VERSION "eCMP INFO-DIV vehicle review 2026-11-03; 125000 bit/s; PSA-RE 67f7581e7622410efdbb29c7eda3b86982b9b450; Apache-2.0"

NS_ :

BS_:

BU_: AAS AMPLI AVP BCM BGP BSG BSI BTA BTEL BTT CDC CMB CRT DIAG_TOOL EDP_C EMF FMUX IC ICSV IDVR IVC_D MATT MDS OVIP PDS_C RAD RBG SDCM VTH WLC

BO_ 223 EMF_MenuCommand: 4 EMF
 SG_ Unused1 : 26|3@0+ (1,0) [0|7] ""  RAD
 SG_ ListRefreshRequest : 28|2@0+ (1,0) [0|3] ""  RAD
 SG_ RepeatEnabled : 29|1@0+ (1,0) [0|1] ""  RAD
 SG_ ShuffleModeStatus : 30|1@0+ (1,0) [0|1] ""  RAD
 SG_ RandomEnabled : 31|1@0+ (1,0) [0|1] ""  RAD
 SG_ RadioDabFmStatus : 16|1@0+ (1,0) [0|1] ""  RAD
 SG_ RadioTextModeStatus : 17|1@0+ (1,0) [0|1] ""  RAD
 SG_ RadioRdsAfStatus : 18|1@0+ (1,0) [0|1] ""  RAD
 SG_ RadioNewsOption7Status : 19|1@0+ (1,0) [0|1] ""  RAD
 SG_ RadioNewsOption6Status : 20|1@0+ (1,0) [0|1] ""  RAD
 SG_ RadioNewsOption5Status : 21|1@0+ (1,0) [0|1] ""  RAD
 SG_ RadioNewsOption4Status : 22|1@0+ (1,0) [0|1] ""  RAD
 SG_ RadioNewsOption3Status : 23|1@0+ (1,0) [0|1] ""  RAD
 SG_ RadioNewsOption2Status : 8|1@0+ (1,0) [0|1] ""  RAD
 SG_ RadioNewsOption1Status : 9|1@0+ (1,0) [0|1] ""  RAD
 SG_ NextListTypeRequested : 12|3@0+ (1,0) [0|7] ""  RAD
 SG_ DesignatorBlockType : 15|3@0+ (1,0) [0|7] ""  RAD
 SG_ ListOpenRequest : 3|4@0+ (1,0) [0|15] ""  RAD
 SG_ CdTextModeStatus : 4|1@0+ (1,0) [0|1] ""  RAD
 SG_ ModificationInProgress : 5|1@0+ (1,0) [0|1] ""  RAD
 SG_ DesignatorButtonManager : 7|2@0+ (1,0) [0|3] ""  RAD

BO_ 224 BSI_ImmobilizerKeyUccEngine: 7 BSI
 SG_ AcPrecondSchedule4StartTime : 42|11@0+ (1,0) [0|1440] "min"  MDS,BTEL,OVIP
 SG_ Unused3 : 47|5@0+ (1,0) [0|31] ""  MDS,BTEL,OVIP
 SG_ AcPrecondSundaySchedule4Active : 32|1@0+ (1,0) [0|1] ""  MDS,BTEL,OVIP
 SG_ AcPrecondSaturdaySchedule4Active : 33|1@0+ (1,0) [0|1] ""  MDS,BTEL,OVIP
 SG_ AcPrecondFridaySchedule4Active : 34|1@0+ (1,0) [0|1] ""  MDS,BTEL,OVIP
 SG_ AcPrecondThursdaySchedule4Active : 35|1@0+ (1,0) [0|1] ""  MDS,BTEL,OVIP
 SG_ AcPrecondWednesdaySchedul_8f02bb : 36|1@0+ (1,0) [0|1] ""  MDS,BTEL,OVIP
 SG_ AcPrecondTuesdaySchedule4Active : 37|1@0+ (1,0) [0|1] ""  MDS,BTEL,OVIP
 SG_ AcPrecondMondaySchedule4Active : 38|1@0+ (1,0) [0|1] ""  MDS,BTEL,OVIP
 SG_ AcPrecondSchedule4Enabled : 39|1@0+ (1,0) [0|1] ""  MDS,BTEL,OVIP
 SG_ AcPrecondSchedule3StartTime : 18|11@0+ (1,0) [0|1440] "min"  MDS,BTEL,OVIP
 SG_ Unused2 : 23|5@0+ (1,0) [0|31] ""  MDS,BTEL,OVIP
 SG_ AcPrecondSundaySchedule3Active : 8|1@0+ (1,0) [0|1] ""  MDS,BTEL,OVIP
 SG_ AcPrecondSaturdaySchedule3Active : 9|1@0+ (1,0) [0|1] ""  MDS,BTEL,OVIP
 SG_ AcPrecondFridaySchedule3Active : 10|1@0+ (1,0) [0|1] ""  MDS,BTEL,OVIP
 SG_ AcPrecondThursdaySchedule3Active : 11|1@0+ (1,0) [0|1] ""  MDS,BTEL,OVIP
 SG_ AcPrecondWednesdaySchedul_dacc80 : 12|1@0+ (1,0) [0|1] ""  MDS,BTEL,OVIP
 SG_ AcPrecondTuesdaySchedule3Active : 13|1@0+ (1,0) [0|1] ""  MDS,BTEL,OVIP
 SG_ AcPrecondMondaySchedule3Active : 14|1@0+ (1,0) [0|1] ""  MDS,BTEL,OVIP
 SG_ AcPrecondSchedule3Enabled : 15|1@0+ (1,0) [0|1] ""  MDS,BTEL,OVIP
 SG_ Unused1 : 7|8@0+ (1,0) [0|255] ""  MDS,BTEL,OVIP

BO_ 225 AAS_Data: 8 AAS
 SG_ CpkMenuRequest : 56|1@0+ (1,0) [0|1] ""  RAD,BTEL,CMB,AVP,ICSV,MATT,BSI,AMPLI,EMF,PDS_C,OVIP,MDS
 SG_ Scp9HmiRequest : 59|3@0+ (1,0) [0|7] ""  RAD,BTEL,CMB,AVP,ICSV,MATT,BSI,AMPLI,EMF,PDS_C,OVIP,MDS
 SG_ Scp6HmiRequest : 62|3@0+ (1,0) [0|7] ""  RAD,BTEL,CMB,AVP,ICSV,MATT,BSI,AMPLI,EMF,PDS_C,OVIP,MDS
 SG_ Scp9Status : 63|1@0+ (1,0) [0|1] ""  RAD,BTEL,CMB,AVP,ICSV,MATT,BSI,AMPLI,EMF,PDS_C,OVIP,MDS
 SG_ NetworkVoltageBoostRequest : 48|1@0+ (1,0) [0|1] ""  RAD,BTEL,CMB,AVP,ICSV,MATT,BSI,AMPLI,EMF,PDS_C,OVIP,MDS
 SG_ EngineOnRequest : 49|1@0+ (1,0) [0|1] ""  RAD,BTEL,CMB,AVP,ICSV,MATT,BSI,AMPLI,EMF,PDS_C,OVIP,MDS
 SG_ SpaceMeasurementDisplayRequest : 50|1@0+ (1,0) [0|1] ""  RAD,BTEL,CMB,AVP,ICSV,MATT,BSI,AMPLI,EMF,PDS_C,OVIP,MDS
 SG_ MeasuredDistance : 52|2@0+ (1,0) [0|3] ""  RAD,BTEL,CMB,AVP,ICSV,MATT,BSI,AMPLI,EMF,PDS_C,OVIP,MDS
 SG_ SpaceMeasurementStatus : 55|3@0+ (1,0) [0|7] ""  RAD,BTEL,CMB,AVP,ICSV,MATT,BSI,AMPLI,EMF,PDS_C,OVIP,MDS
 SG_ Unused2 : 40|1@0+ (1,0) [0|1] ""  RAD,BTEL,CMB,AVP,ICSV,MATT,BSI,AMPLI,EMF,PDS_C,OVIP,MDS
 SG_ AasDisplayRequest : 41|1@0+ (1,0) [0|1] ""  RAD,BTEL,CMB,AVP,ICSV,MATT,BSI,AMPLI,EMF,PDS_C,OVIP,MDS
 SG_ FrontRightStatus : 44|3@0+ (1,0) [0|7] ""  RAD,BTEL,CMB,AVP,ICSV,MATT,BSI,AMPLI,EMF,PDS_C,OVIP,MDS
 SG_ FrontMiddleStatus : 47|3@0+ (1,0) [0|7] ""  RAD,BTEL,CMB,AVP,ICSV,MATT,BSI,AMPLI,EMF,PDS_C,OVIP,MDS
 SG_ LateralBeepLocation : 33|2@0+ (1,0) [0|3] ""  RAD,BTEL,CMB,AVP,ICSV,MATT,BSI,AMPLI,EMF,PDS_C,OVIP,MDS
 SG_ FrontLeftStatus : 36|3@0+ (1,0) [0|7] ""  RAD,BTEL,CMB,AVP,ICSV,MATT,BSI,AMPLI,EMF,PDS_C,OVIP,MDS
 SG_ RearRightStatus : 39|3@0+ (1,0) [0|7] ""  RAD,BTEL,CMB,AVP,ICSV,MATT,BSI,AMPLI,EMF,PDS_C,OVIP,MDS
 SG_ ScpLampStatus : 25|2@0+ (1,0) [0|3] ""  RAD,BTEL,CMB,AVP,ICSV,MATT,BSI,AMPLI,EMF,PDS_C,OVIP,MDS
 SG_ RearMiddleStatus : 28|3@0+ (1,0) [0|7] ""  RAD,BTEL,CMB,AVP,ICSV,MATT,BSI,AMPLI,EMF,PDS_C,OVIP,MDS
 SG_ RearLeftStatus : 31|3@0+ (1,0) [0|7] ""  RAD,BTEL,CMB,AVP,ICSV,MATT,BSI,AMPLI,EMF,PDS_C,OVIP,MDS
 SG_ ParkAssistBeepInterval : 21|6@0+ (8,0) [0|496] "ms"  RAD,BTEL,CMB,AVP,ICSV,MATT,BSI,AMPLI,EMF,PDS_C,OVIP,MDS
 SG_ ParkAssistBeepDuration : 23|2@0+ (1,0) [0|3] ""  RAD,BTEL,CMB,AVP,ICSV,MATT,BSI,AMPLI,EMF,PDS_C,OVIP,MDS
 SG_ Unused1 : 8|1@0+ (1,0) [0|1] ""  RAD,BTEL,CMB,AVP,ICSV,MATT,BSI,AMPLI,EMF,PDS_C,OVIP,MDS
 SG_ LateralParkAssistStatus : 11|3@0+ (1,0) [0|7] ""  RAD,BTEL,CMB,AVP,ICSV,MATT,BSI,AMPLI,EMF,PDS_C,OVIP,MDS
 SG_ SoundEnabled : 12|1@0+ (1,0) [0|1] ""  RAD,BTEL,CMB,AVP,ICSV,MATT,BSI,AMPLI,EMF,PDS_C,OVIP,MDS
 SG_ SoundFr : 13|1@0+ (1,0) [0|1] ""  RAD,BTEL,CMB,AVP,ICSV,MATT,BSI,AMPLI,EMF,PDS_C,OVIP,MDS
 SG_ SoundLr : 15|2@0+ (1,0) [0|3] ""  RAD,BTEL,CMB,AVP,ICSV,MATT,BSI,AMPLI,EMF,PDS_C,OVIP,MDS
 SG_ CpkSelection : 1|2@0+ (1,0) [0|3] ""  RAD,BTEL,CMB,AVP,ICSV,MATT,BSI,AMPLI,EMF,PDS_C,OVIP,MDS
 SG_ FrontStatus : 4|3@0+ (1,0) [0|7] ""  RAD,BTEL,CMB,AVP,ICSV,MATT,BSI,AMPLI,EMF,PDS_C,OVIP,MDS
 SG_ RearParkAssistStatus : 7|3@0+ (1,0) [0|7] ""  RAD,BTEL,CMB,AVP,ICSV,MATT,BSI,AMPLI,EMF,PDS_C,OVIP,MDS

BO_ 226 ICSV_CdChangerDiskListStatus: 8 ICSV
 SG_ Unused4 : 63|8@0+ (1,0) [0|255] ""  BTEL,OVIP,EMF,RAD
 SG_ DiscStatus6 : 49|2@0+ (1,0) [0|3] ""  BTEL,OVIP,EMF,RAD
 SG_ DiscFormat6 : 51|2@0+ (1,0) [0|3] ""  BTEL,OVIP,EMF,RAD
 SG_ DiscStatus5 : 53|2@0+ (1,0) [0|3] ""  BTEL,OVIP,EMF,RAD
 SG_ DiscFormat5 : 55|2@0+ (1,0) [0|3] ""  BTEL,OVIP,EMF,RAD
 SG_ DiscStatus4 : 41|2@0+ (1,0) [0|3] ""  BTEL,OVIP,EMF,RAD
 SG_ DiscFormat4 : 43|2@0+ (1,0) [0|3] ""  BTEL,OVIP,EMF,RAD
 SG_ DiscStatus3 : 45|2@0+ (1,0) [0|3] ""  BTEL,OVIP,EMF,RAD
 SG_ DiscFormat3 : 47|2@0+ (1,0) [0|3] ""  BTEL,OVIP,EMF,RAD
 SG_ DiscStatus2 : 33|2@0+ (1,0) [0|3] ""  BTEL,OVIP,EMF,RAD
 SG_ DiscFormat2 : 35|2@0+ (1,0) [0|3] ""  BTEL,OVIP,EMF,RAD
 SG_ DiscStatus1 : 37|2@0+ (1,0) [0|3] ""  BTEL,OVIP,EMF,RAD
 SG_ DiscFormat1 : 39|2@0+ (1,0) [0|3] ""  BTEL,OVIP,EMF,RAD
 SG_ Unused3 : 27|4@0+ (1,0) [0|15] ""  BTEL,OVIP,EMF,RAD
 SG_ SelectedPresetNumber : 31|4@0+ (1,0) [0|15] ""  BTEL,OVIP,EMF,RAD
 SG_ Unused2 : 17|2@0+ (1,0) [0|3] ""  BTEL,OVIP,EMF,RAD
 SG_ CdcListCommand : 19|2@0+ (1,0) [0|3] ""  BTEL,OVIP,EMF,RAD
 SG_ CdcDirectoryType : 23|4@0+ (1,0) [0|15] ""  BTEL,OVIP,EMF,RAD
 SG_ Unused1 : 7|16@0+ (1,0) [0|65535] ""  BTEL,OVIP,EMF,RAD

BO_ 230 ICSV_BrakeUnitStatus: 8 ICSV
 SG_ BrakeEcuFrame5Checksum : 59|4@0+ (1,0) [0|15] ""  BTEL,AAS,CMB,MDS,AVP,OVIP,RAD
 SG_ ProcessCounter4bit : 63|4@0+ (1,0) [0|15] ""  BTEL,AAS,CMB,MDS,AVP,OVIP,RAD
 SG_ Unused2 : 51|4@0+ (1,0) [0|15] ""  BTEL,AAS,CMB,MDS,AVP,OVIP,RAD
 SG_ BrakeFunctionNeedForStartStop : 53|2@0+ (1,0) [0|3] ""  BTEL,AAS,CMB,MDS,AVP,OVIP,RAD
 SG_ BrakeEcuPowerManagementFault : 54|1@0+ (1,0) [0|1] ""  BTEL,AAS,CMB,MDS,AVP,OVIP,RAD
 SG_ EmergencyBrakingSignaliza_517ee3 : 55|1@0+ (1,0) [0|1] ""  BTEL,AAS,CMB,MDS,AVP,OVIP,RAD
 SG_ BatteryVoltageUcBrake : 47|8@0+ (0.05,7) [7|18.5] "V"  BTEL,AAS,CMB,MDS,AVP,OVIP,RAD
 SG_ RearRightWheelSpinCounter : 30|15@0+ (1,0) [0|32767] ""  BTEL,AAS,CMB,MDS,AVP,OVIP,RAD
 SG_ RearRightWheelSpeedSensorFault : 31|1@0+ (1,0) [0|1] ""  BTEL,AAS,CMB,MDS,AVP,OVIP,RAD
 SG_ RearLeftWheelSpinCounter : 14|15@0+ (1,0) [0|32767] ""  BTEL,AAS,CMB,MDS,AVP,OVIP,RAD
 SG_ RearLeftWheelSpeedSensorFault : 15|1@0+ (1,0) [0|1] ""  BTEL,AAS,CMB,MDS,AVP,OVIP,RAD
 SG_ AbsFaultLampRequest : 0|1@0+ (1,0) [0|1] ""  BTEL,AAS,CMB,MDS,AVP,OVIP,RAD
 SG_ BrakeFluidLevelAlert : 1|1@0+ (1,0) [0|1] ""  BTEL,AAS,CMB,MDS,AVP,OVIP,RAD
 SG_ WornBrakePadsIndicator : 2|1@0+ (1,0) [0|1] ""  BTEL,AAS,CMB,MDS,AVP,OVIP,RAD
 SG_ RefInProgress : 3|1@0+ (1,0) [0|1] ""  BTEL,AAS,CMB,MDS,AVP,OVIP,RAD
 SG_ AutomaticHazardLightsByUcBrake : 4|1@0+ (1,0) [0|1] ""  BTEL,AAS,CMB,MDS,AVP,OVIP,RAD
 SG_ AbsInProgress : 5|1@0+ (1,0) [0|1] ""  BTEL,AAS,CMB,MDS,AVP,OVIP,RAD
 SG_ Unused1 : 6|1@0+ (1,0) [0|1] ""  BTEL,AAS,CMB,MDS,AVP,OVIP,RAD
 SG_ RefFaultLamp : 7|1@0+ (1,0) [0|1] ""  BTEL,AAS,CMB,MDS,AVP,OVIP,RAD

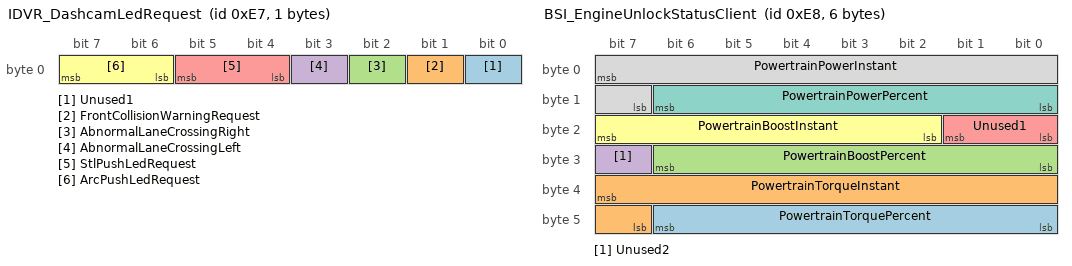
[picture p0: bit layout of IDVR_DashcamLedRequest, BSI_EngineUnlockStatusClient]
BO_ 231 IDVR_DashcamLedRequest: 1 IDVR
 SG_ Unused1 : 0|1@0+ (1,0) [0|1] ""  ICSV,FMUX,BTEL,CMB,OVIP,MDS
 SG_ FrontCollisionWarningRequest : 1|1@0+ (1,0) [0|1] ""  ICSV,FMUX,BTEL,CMB,OVIP,MDS
 SG_ AbnormalLaneCrossingRight : 2|1@0+ (1,0) [0|1] ""  ICSV,FMUX,BTEL,CMB,OVIP,MDS
 SG_ AbnormalLaneCrossingLeft : 3|1@0+ (1,0) [0|1] ""  ICSV,FMUX,BTEL,CMB,OVIP,MDS
 SG_ StlPushLedRequest : 5|2@0+ (1,0) [0|3] ""  ICSV,FMUX,BTEL,CMB,OVIP,MDS
 SG_ ArcPushLedRequest : 7|2@0+ (1,0) [0|3] ""  ICSV,FMUX,BTEL,CMB,OVIP,MDS

BO_ 232 BSI_EngineUnlockStatusClient: 6 BSI
 SG_ PowertrainTorquePercent : 46|7@0+ (1,0) [0|100] "%"  OVIP,CMB,MATT,RAD
 SG_ PowertrainTorqueInstant : 39|9@0+ (1,0) [0|500] "Nm"  OVIP,CMB,MATT,RAD
 SG_ PowertrainBoostPercent : 30|7@0+ (1,0) [0|100] "%"  OVIP,CMB,MATT,RAD
 SG_ Unused2 : 31|1@0+ (1,0) [0|1] ""  OVIP,CMB,MATT,RAD
 SG_ Unused1 : 17|2@0+ (1,0) [0|3] ""  OVIP,CMB,MATT,RAD
 SG_ PowertrainBoostInstant : 23|6@0+ (0.1,0) [0|5] "bar"  OVIP,CMB,MATT,RAD
 SG_ PowertrainPowerPercent : 14|7@0+ (1,0) [0|100] "%"  OVIP,CMB,MATT,RAD
 SG_ PowertrainPowerInstant : 7|9@0+ (1,0) [0|500] "hp"  OVIP,CMB,MATT,RAD

BO_ 233 ICSV_NavExportFlowControl: 8 ICSV
 SG_ FlowPadding5 m3 : 63|8@0+ (1,0) [0|255] "raw"  BTEL,OVIP
 SG_ FirstData6 m1 : 63|8@0+ (1,0) [0|255] "raw"  BTEL,OVIP
 SG_ UnknownData7 m4 : 63|8@0+ (1,0) [0|255] "raw"  BTEL,OVIP
 SG_ ConsecutiveData7 m2 : 63|8@0+ (1,0) [0|255] "raw"  BTEL,OVIP
 SG_ SingleData7 m0 : 63|8@0+ (1,0) [0|255] "raw"  BTEL,OVIP
 SG_ FlowPadding4 m3 : 55|8@0+ (1,0) [0|255] "raw"  BTEL,OVIP
 SG_ FirstData5 m1 : 55|8@0+ (1,0) [0|255] "raw"  BTEL,OVIP
 SG_ UnknownData6 m4 : 55|8@0+ (1,0) [0|255] "raw"  BTEL,OVIP
 SG_ ConsecutiveData6 m2 : 55|8@0+ (1,0) [0|255] "raw"  BTEL,OVIP
 SG_ SingleData6 m0 : 55|8@0+ (1,0) [0|255] "raw"  BTEL,OVIP
 SG_ FlowPadding3 m3 : 47|8@0+ (1,0) [0|255] "raw"  BTEL,OVIP
 SG_ FirstData4 m1 : 47|8@0+ (1,0) [0|255] "raw"  BTEL,OVIP
 SG_ UnknownData5 m4 : 47|8@0+ (1,0) [0|255] "raw"  BTEL,OVIP
 SG_ ConsecutiveData5 m2 : 47|8@0+ (1,0) [0|255] "raw"  BTEL,OVIP
 SG_ SingleData5 m0 : 47|8@0+ (1,0) [0|255] "raw"  BTEL,OVIP
 SG_ FlowPadding2 m3 : 39|8@0+ (1,0) [0|255] "raw"  BTEL,OVIP
 SG_ FirstData3 m1 : 39|8@0+ (1,0) [0|255] "raw"  BTEL,OVIP
 SG_ UnknownData4 m4 : 39|8@0+ (1,0) [0|255] "raw"  BTEL,OVIP
 SG_ ConsecutiveData4 m2 : 39|8@0+ (1,0) [0|255] "raw"  BTEL,OVIP
 SG_ SingleData4 m0 : 39|8@0+ (1,0) [0|255] "raw"  BTEL,OVIP
 SG_ FlowPadding1 m3 : 31|8@0+ (1,0) [0|255] "raw"  BTEL,OVIP
 SG_ FirstData2 m1 : 31|8@0+ (1,0) [0|255] "raw"  BTEL,OVIP
 SG_ UnknownData3 m4 : 31|8@0+ (1,0) [0|255] "raw"  BTEL,OVIP
 SG_ ConsecutiveData3 m2 : 31|8@0+ (1,0) [0|255] "raw"  BTEL,OVIP
 SG_ SingleData3 m0 : 31|8@0+ (1,0) [0|255] "raw"  BTEL,OVIP
 SG_ FirstData1 m1 : 23|8@0+ (1,0) [0|255] "raw"  BTEL,OVIP
 SG_ UnknownData2 m4 : 23|8@0+ (1,0) [0|255] "raw"  BTEL,OVIP
 SG_ ConsecutiveData2 m2 : 23|8@0+ (1,0) [0|255] "raw"  BTEL,OVIP
 SG_ SingleData2 m0 : 23|8@0+ (1,0) [0|255] "raw"  BTEL,OVIP
 SG_ SeparationTimeRaw m3 : 23|8@0+ (1,0) [0|255] "raw"  BTEL,OVIP
 SG_ UnknownData1 m4 : 15|8@0+ (1,0) [0|255] "raw"  BTEL,OVIP
 SG_ ConsecutiveData1 m2 : 15|8@0+ (1,0) [0|255] "raw"  BTEL,OVIP
 SG_ SingleData1 m0 : 15|8@0+ (1,0) [0|255] "raw"  BTEL,OVIP
 SG_ BlockSize m3 : 15|8@0+ (1,0) [0|255] "raw"  BTEL,OVIP
 SG_ UnknownPciLow m4 : 3|4@0+ (1,0) [0|15] "raw"  BTEL,OVIP
 SG_ FlowStatus m3 : 3|4@0+ (1,0) [0|15] "raw"  BTEL,OVIP
 SG_ ConsecutiveSequence m2 : 3|4@0+ (1,0) [0|15] "raw"  BTEL,OVIP
 SG_ FirstFrameLength m1 : 3|12@0+ (1,0) [0|4095] "raw"  BTEL,OVIP
 SG_ SingleFrameLength m0 : 3|4@0+ (1,0) [0|15] "raw"  BTEL,OVIP
 SG_ IsoTpFrameType M : 7|4@0+ (1,0) [0|15] ""  BTEL,OVIP

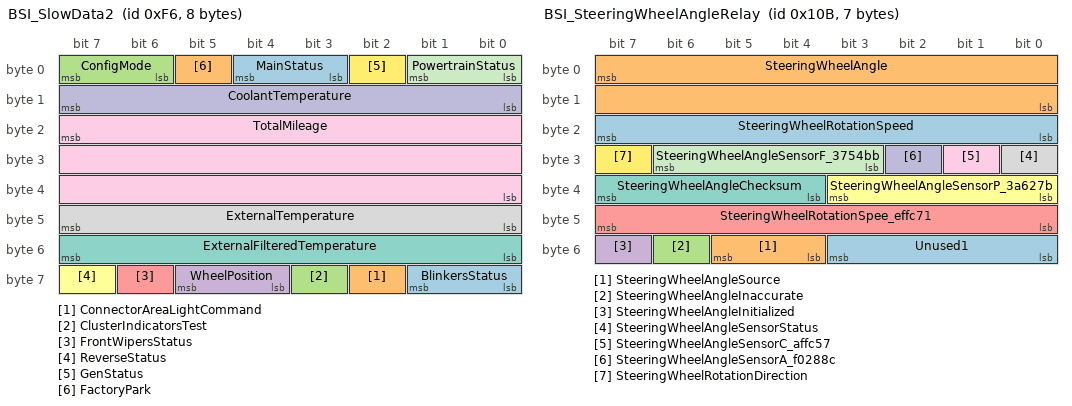
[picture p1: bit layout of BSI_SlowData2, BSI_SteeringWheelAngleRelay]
BO_ 246 BSI_SlowData2: 8 BSI
 SG_ BlinkersStatus : 57|2@0+ (1,0) [0|3] ""  SDCM,CRT,BTEL,ICSV,CDC,EMF,RAD,CMB,VTH,AAS,MDS,MATT,FMUX,BGP,AMPLI,AVP,OVIP,IDVR,WLC
 SG_ ConnectorAreaLightCommand : 58|1@0+ (1,0) [0|1] ""  SDCM,CRT,BTEL,ICSV,CDC,EMF,RAD,CMB,VTH,AAS,MDS,MATT,FMUX,BGP,AMPLI,AVP,OVIP,IDVR,WLC
 SG_ ClusterIndicatorsTest : 59|1@0+ (1,0) [0|1] ""  SDCM,CRT,BTEL,ICSV,CDC,EMF,RAD,CMB,VTH,AAS,MDS,MATT,FMUX,BGP,AMPLI,AVP,OVIP,IDVR,WLC
 SG_ WheelPosition : 61|2@0+ (1,0) [0|3] ""  SDCM,CRT,BTEL,ICSV,CDC,EMF,RAD,CMB,VTH,AAS,MDS,MATT,FMUX,BGP,AMPLI,AVP,OVIP,IDVR,WLC
 SG_ FrontWipersStatus : 62|1@0+ (1,0) [0|1] ""  SDCM,CRT,BTEL,ICSV,CDC,EMF,RAD,CMB,VTH,AAS,MDS,MATT,FMUX,BGP,AMPLI,AVP,OVIP,IDVR,WLC
 SG_ ReverseStatus : 63|1@0+ (1,0) [0|1] ""  SDCM,CRT,BTEL,ICSV,CDC,EMF,RAD,CMB,VTH,AAS,MDS,MATT,FMUX,BGP,AMPLI,AVP,OVIP,IDVR,WLC
 SG_ ExternalFilteredTemperature : 55|8@0+ (0.5,-40) [-40|85] "degC"  SDCM,CRT,BTEL,ICSV,CDC,EMF,RAD,CMB,VTH,AAS,MDS,MATT,FMUX,BGP,AMPLI,AVP,OVIP,IDVR,WLC
 SG_ ExternalTemperature : 47|8@0+ (0.5,-40) [-40|85] ""  SDCM,CRT,BTEL,ICSV,CDC,EMF,RAD,CMB,VTH,AAS,MDS,MATT,FMUX,BGP,AMPLI,AVP,OVIP,IDVR,WLC
 SG_ TotalMileage : 23|24@0+ (0.1,0) [0|1677721.4] "km"  SDCM,CRT,BTEL,ICSV,CDC,EMF,RAD,CMB,VTH,AAS,MDS,MATT,FMUX,BGP,AMPLI,AVP,OVIP,IDVR,WLC
 SG_ CoolantTemperature : 15|8@0+ (1,-40) [-40|214] "degC"  SDCM,CRT,BTEL,ICSV,CDC,EMF,RAD,CMB,VTH,AAS,MDS,MATT,FMUX,BGP,AMPLI,AVP,OVIP,IDVR,WLC
 SG_ PowertrainStatus : 1|2@0+ (1,0) [0|3] ""  SDCM,CRT,BTEL,ICSV,CDC,EMF,RAD,CMB,VTH,AAS,MDS,MATT,FMUX,BGP,AMPLI,AVP,OVIP,IDVR,WLC
 SG_ GenStatus : 2|1@0+ (1,0) [0|1] ""  SDCM,CRT,BTEL,ICSV,CDC,EMF,RAD,CMB,VTH,AAS,MDS,MATT,FMUX,BGP,AMPLI,AVP,OVIP,IDVR,WLC
 SG_ MainStatus : 4|2@0+ (1,0) [0|3] ""  SDCM,CRT,BTEL,ICSV,CDC,EMF,RAD,CMB,VTH,AAS,MDS,MATT,FMUX,BGP,AMPLI,AVP,OVIP,IDVR,WLC
 SG_ FactoryPark : 5|1@0+ (1,0) [0|1] ""  SDCM,CRT,BTEL,ICSV,CDC,EMF,RAD,CMB,VTH,AAS,MDS,MATT,FMUX,BGP,AMPLI,AVP,OVIP,IDVR,WLC
 SG_ ConfigMode : 7|2@0+ (1,0) [0|3] ""  SDCM,CRT,BTEL,ICSV,CDC,EMF,RAD,CMB,VTH,AAS,MDS,MATT,FMUX,BGP,AMPLI,AVP,OVIP,IDVR,WLC

BO_ 257 WLC_ScrVersion: 8 WLC
 SG_ FlowPadding5 m3 : 63|8@0+ (1,0) [0|255] "raw"  SDCM
 SG_ FirstData6 m1 : 63|8@0+ (1,0) [0|255] "raw"  SDCM
 SG_ UnknownData7 m4 : 63|8@0+ (1,0) [0|255] "raw"  SDCM
 SG_ ConsecutiveData7 m2 : 63|8@0+ (1,0) [0|255] "raw"  SDCM
 SG_ SingleData7 m0 : 63|8@0+ (1,0) [0|255] "raw"  SDCM
 SG_ FlowPadding4 m3 : 55|8@0+ (1,0) [0|255] "raw"  SDCM
 SG_ FirstData5 m1 : 55|8@0+ (1,0) [0|255] "raw"  SDCM
 SG_ UnknownData6 m4 : 55|8@0+ (1,0) [0|255] "raw"  SDCM
 SG_ ConsecutiveData6 m2 : 55|8@0+ (1,0) [0|255] "raw"  SDCM
 SG_ SingleData6 m0 : 55|8@0+ (1,0) [0|255] "raw"  SDCM
 SG_ FlowPadding3 m3 : 47|8@0+ (1,0) [0|255] "raw"  SDCM
 SG_ FirstData4 m1 : 47|8@0+ (1,0) [0|255] "raw"  SDCM
 SG_ UnknownData5 m4 : 47|8@0+ (1,0) [0|255] "raw"  SDCM
 SG_ ConsecutiveData5 m2 : 47|8@0+ (1,0) [0|255] "raw"  SDCM
 SG_ SingleData5 m0 : 47|8@0+ (1,0) [0|255] "raw"  SDCM
 SG_ FlowPadding2 m3 : 39|8@0+ (1,0) [0|255] "raw"  SDCM
 SG_ FirstData3 m1 : 39|8@0+ (1,0) [0|255] "raw"  SDCM
 SG_ UnknownData4 m4 : 39|8@0+ (1,0) [0|255] "raw"  SDCM
 SG_ ConsecutiveData4 m2 : 39|8@0+ (1,0) [0|255] "raw"  SDCM
 SG_ SingleData4 m0 : 39|8@0+ (1,0) [0|255] "raw"  SDCM
 SG_ FlowPadding1 m3 : 31|8@0+ (1,0) [0|255] "raw"  SDCM
 SG_ FirstData2 m1 : 31|8@0+ (1,0) [0|255] "raw"  SDCM
 SG_ UnknownData3 m4 : 31|8@0+ (1,0) [0|255] "raw"  SDCM
 SG_ ConsecutiveData3 m2 : 31|8@0+ (1,0) [0|255] "raw"  SDCM
 SG_ SingleData3 m0 : 31|8@0+ (1,0) [0|255] "raw"  SDCM
 SG_ FirstData1 m1 : 23|8@0+ (1,0) [0|255] "raw"  SDCM
 SG_ UnknownData2 m4 : 23|8@0+ (1,0) [0|255] "raw"  SDCM
 SG_ ConsecutiveData2 m2 : 23|8@0+ (1,0) [0|255] "raw"  SDCM
 SG_ SingleData2 m0 : 23|8@0+ (1,0) [0|255] "raw"  SDCM
 SG_ SeparationTimeRaw m3 : 23|8@0+ (1,0) [0|255] "raw"  SDCM
 SG_ UnknownData1 m4 : 15|8@0+ (1,0) [0|255] "raw"  SDCM
 SG_ ConsecutiveData1 m2 : 15|8@0+ (1,0) [0|255] "raw"  SDCM
 SG_ SingleData1 m0 : 15|8@0+ (1,0) [0|255] "raw"  SDCM
 SG_ BlockSize m3 : 15|8@0+ (1,0) [0|255] "raw"  SDCM
 SG_ UnknownPciLow m4 : 3|4@0+ (1,0) [0|15] "raw"  SDCM
 SG_ FlowStatus m3 : 3|4@0+ (1,0) [0|15] "raw"  SDCM
 SG_ ConsecutiveSequence m2 : 3|4@0+ (1,0) [0|15] "raw"  SDCM
 SG_ FirstFrameLength m1 : 3|12@0+ (1,0) [0|4095] "raw"  SDCM
 SG_ SingleFrameLength m0 : 3|4@0+ (1,0) [0|15] "raw"  SDCM
 SG_ IsoTpFrameType M : 7|4@0+ (1,0) [0|15] ""  SDCM

BO_ 267 BSI_SteeringWheelAngleRelay: 7 BSI
 SG_ Unused1 : 51|4@0+ (1,0) [0|15] ""  ICSV,AAS,AVP,BTEL,OVIP,IDVR
 SG_ SteeringWheelAngleSource : 53|2@0+ (1,0) [0|3] ""  ICSV,AAS,AVP,BTEL,OVIP,IDVR
 SG_ SteeringWheelAngleInaccurate : 54|1@0+ (1,0) [0|1] ""  ICSV,AAS,AVP,BTEL,OVIP,IDVR
 SG_ SteeringWheelAngleInitialized : 55|1@0+ (1,0) [0|1] ""  ICSV,AAS,AVP,BTEL,OVIP,IDVR
 SG_ SteeringWheelRotationSpee_effc71 : 47|8@0+ (4,0) [0|1016] ""  ICSV,AAS,AVP,BTEL,OVIP,IDVR
 SG_ SteeringWheelAngleSensorP_3a627b : 35|4@0+ (1,0) [0|15] ""  ICSV,AAS,AVP,BTEL,OVIP,IDVR
 SG_ SteeringWheelAngleChecksum : 39|4@0+ (1,0) [0|15] ""  ICSV,AAS,AVP,BTEL,OVIP,IDVR
 SG_ SteeringWheelAngleSensorStatus : 24|1@0+ (1,0) [0|1] ""  ICSV,AAS,AVP,BTEL,OVIP,IDVR
 SG_ SteeringWheelAngleSensorC_affc57 : 25|1@0+ (1,0) [0|1] ""  ICSV,AAS,AVP,BTEL,OVIP,IDVR
 SG_ SteeringWheelAngleSensorA_f0288c : 26|1@0+ (1,0) [0|1] ""  ICSV,AAS,AVP,BTEL,OVIP,IDVR
 SG_ SteeringWheelAngleSensorF_3754bb : 30|4@0+ (1,0) [0|15] ""  ICSV,AAS,AVP,BTEL,OVIP,IDVR
 SG_ SteeringWheelRotationDirection : 31|1@0+ (1,0) [0|1] ""  ICSV,AAS,AVP,BTEL,OVIP,IDVR
 SG_ SteeringWheelRotationSpeed : 23|8@0+ (4,0) [0|1016] ""  ICSV,AAS,AVP,BTEL,OVIP,IDVR
 SG_ SteeringWheelAngle : 7|16@0- (0.1,0) [-780|780] ""  ICSV,AAS,AVP,BTEL,OVIP,IDVR

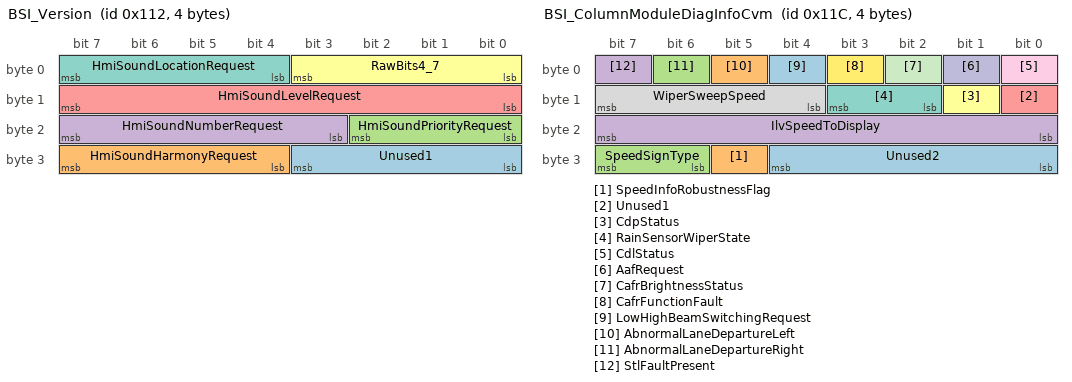
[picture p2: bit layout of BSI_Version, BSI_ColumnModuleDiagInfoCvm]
BO_ 274 BSI_Version: 4 BSI
 SG_ Unused1 : 27|4@0+ (1,0) [0|15] ""  BTEL
 SG_ HmiSoundHarmonyRequest : 31|4@0+ (1,0) [0|15] ""  BTEL
 SG_ HmiSoundPriorityRequest : 18|3@0+ (1,0) [0|7] ""  BTEL
 SG_ HmiSoundNumberRequest : 23|5@0+ (1,0) [0|22] ""  BTEL
 SG_ HmiSoundLevelRequest : 15|8@0+ (1,0) [0|255] ""  BTEL
 SG_ RawBits4_7 : 3|4@0+ (1,0) [0|15] "raw" Vector__XXX
 SG_ HmiSoundLocationRequest : 7|4@0+ (1,0) [0|15] ""  BTEL

BO_ 283 MDS_ClimatePrecondSchedRemote2: 7 MDS
 SG_ ClimatePrecondRemoteSlot4_321752 : 42|11@0+ (1,0) [0|1440] "min"  BSI
 SG_ RawBits40_44 : 47|5@0+ (1,0) [0|31] "raw" Vector__XXX
 SG_ ClimatePrecondRemoteSunda_f317f4 : 32|1@0+ (1,0) [0|1] ""  BSI
 SG_ ClimatePrecondRemoteSatur_993fe6 : 33|1@0+ (1,0) [0|1] ""  BSI
 SG_ ClimatePrecondRemoteFrida_b8e5fa : 34|1@0+ (1,0) [0|1] ""  BSI
 SG_ ClimatePrecondRemoteThurs_ff4734 : 35|1@0+ (1,0) [0|1] ""  BSI
 SG_ ClimatePrecondRemoteWedne_4ee4b3 : 36|1@0+ (1,0) [0|1] ""  BSI
 SG_ ClimatePrecondRemoteTuesd_931c43 : 37|1@0+ (1,0) [0|1] ""  BSI
 SG_ ClimatePrecondRemoteMonda_aa1b42 : 38|1@0+ (1,0) [0|1] ""  BSI
 SG_ ClimatePrecondRemoteSlot4Enabled : 39|1@0+ (1,0) [0|1] ""  BSI
 SG_ ClimatePrecondRemoteSlot3_8e10d4 : 18|11@0+ (1,0) [0|1440] "min"  BSI
 SG_ RawBits16_20 : 23|5@0+ (1,0) [0|31] "raw" Vector__XXX
 SG_ ClimatePrecondRemoteSunda_628b10 : 8|1@0+ (1,0) [0|1] ""  BSI
 SG_ ClimatePrecondRemoteSatur_18e3bf : 9|1@0+ (1,0) [0|1] ""  BSI
 SG_ ClimatePrecondRemoteFrida_c5f06a : 10|1@0+ (1,0) [0|1] ""  BSI
 SG_ ClimatePrecondRemoteThurs_3604aa : 11|1@0+ (1,0) [0|1] ""  BSI
 SG_ ClimatePrecondRemoteWedne_be6e1a : 12|1@0+ (1,0) [0|1] ""  BSI
 SG_ ClimatePrecondRemoteTuesd_46cf5d : 13|1@0+ (1,0) [0|1] ""  BSI
 SG_ ClimatePrecondRemoteMonda_edf0b6 : 14|1@0+ (1,0) [0|1] ""  BSI
 SG_ ClimatePrecondRemoteSlot3Enabled : 15|1@0+ (1,0) [0|1] ""  BSI
 SG_ RawByte1 : 7|8@0+ (1,0) [0|255] "raw" Vector__XXX

BO_ 284 BSI_ColumnModuleDiagInfoCvm: 4 BSI
 SG_ Unused2 : 28|5@0+ (1,0) [0|31] ""  BTEL,OVIP
 SG_ SpeedInfoRobustnessFlag : 29|1@0+ (1,0) [0|1] ""  BTEL,OVIP
 SG_ SpeedSignType : 31|2@0+ (1,0) [0|3] ""  BTEL,OVIP
 SG_ IlvSpeedToDisplay : 23|8@0+ (1,0) [0|253] "km/h"  BTEL,OVIP
 SG_ Unused1 : 8|1@0+ (1,0) [0|1] ""  BTEL,OVIP
 SG_ CdpStatus : 9|1@0+ (1,0) [0|1] ""  BTEL,OVIP
 SG_ RainSensorWiperState : 11|2@0+ (1,0) [0|3] ""  BTEL,OVIP
 SG_ WiperSweepSpeed : 15|4@0+ (1,0) [0|15] ""  BTEL,OVIP
 SG_ CdlStatus : 0|1@0+ (1,0) [0|1] ""  BTEL,OVIP
 SG_ AafRequest : 1|1@0+ (1,0) [0|1] ""  BTEL,OVIP
 SG_ CafrBrightnessStatus : 2|1@0+ (1,0) [0|1] ""  BTEL,OVIP
 SG_ CafrFunctionFault : 3|1@0+ (1,0) [0|1] ""  BTEL,OVIP
 SG_ LowHighBeamSwitchingRequest : 4|1@0+ (1,0) [0|1] ""  BTEL,OVIP
 SG_ AbnormalLaneDepartureLeft : 5|1@0+ (1,0) [0|1] ""  BTEL,OVIP
 SG_ AbnormalLaneDepartureRight : 6|1@0+ (1,0) [0|1] ""  BTEL,OVIP
 SG_ StlFaultPresent : 7|1@0+ (1,0) [0|1] ""  BTEL,OVIP

BO_ 287 ICSV_RadioReplyFlowControl: 8 ICSV
 SG_ FlowPadding5 m3 : 63|8@0+ (1,0) [0|255] "raw"  RAD
 SG_ FirstData6 m1 : 63|8@0+ (1,0) [0|255] "raw"  RAD
 SG_ UnknownData7 m4 : 63|8@0+ (1,0) [0|255] "raw"  RAD
 SG_ ConsecutiveData7 m2 : 63|8@0+ (1,0) [0|255] "raw"  RAD
 SG_ SingleData7 m0 : 63|8@0+ (1,0) [0|255] "raw"  RAD
 SG_ FlowPadding4 m3 : 55|8@0+ (1,0) [0|255] "raw"  RAD
 SG_ FirstData5 m1 : 55|8@0+ (1,0) [0|255] "raw"  RAD
 SG_ UnknownData6 m4 : 55|8@0+ (1,0) [0|255] "raw"  RAD
 SG_ ConsecutiveData6 m2 : 55|8@0+ (1,0) [0|255] "raw"  RAD
 SG_ SingleData6 m0 : 55|8@0+ (1,0) [0|255] "raw"  RAD
 SG_ FlowPadding3 m3 : 47|8@0+ (1,0) [0|255] "raw"  RAD
 SG_ FirstData4 m1 : 47|8@0+ (1,0) [0|255] "raw"  RAD
 SG_ UnknownData5 m4 : 47|8@0+ (1,0) [0|255] "raw"  RAD
 SG_ ConsecutiveData5 m2 : 47|8@0+ (1,0) [0|255] "raw"  RAD
 SG_ SingleData5 m0 : 47|8@0+ (1,0) [0|255] "raw"  RAD
 SG_ FlowPadding2 m3 : 39|8@0+ (1,0) [0|255] "raw"  RAD
 SG_ FirstData3 m1 : 39|8@0+ (1,0) [0|255] "raw"  RAD
 SG_ UnknownData4 m4 : 39|8@0+ (1,0) [0|255] "raw"  RAD
 SG_ ConsecutiveData4 m2 : 39|8@0+ (1,0) [0|255] "raw"  RAD
 SG_ SingleData4 m0 : 39|8@0+ (1,0) [0|255] "raw"  RAD
 SG_ FlowPadding1 m3 : 31|8@0+ (1,0) [0|255] "raw"  RAD
 SG_ FirstData2 m1 : 31|8@0+ (1,0) [0|255] "raw"  RAD
 SG_ UnknownData3 m4 : 31|8@0+ (1,0) [0|255] "raw"  RAD
 SG_ ConsecutiveData3 m2 : 31|8@0+ (1,0) [0|255] "raw"  RAD
 SG_ SingleData3 m0 : 31|8@0+ (1,0) [0|255] "raw"  RAD
 SG_ FirstData1 m1 : 23|8@0+ (1,0) [0|255] "raw"  RAD
 SG_ UnknownData2 m4 : 23|8@0+ (1,0) [0|255] "raw"  RAD
 SG_ ConsecutiveData2 m2 : 23|8@0+ (1,0) [0|255] "raw"  RAD
 SG_ SingleData2 m0 : 23|8@0+ (1,0) [0|255] "raw"  RAD
 SG_ SeparationTimeRaw m3 : 23|8@0+ (1,0) [0|255] "raw"  RAD
 SG_ UnknownData1 m4 : 15|8@0+ (1,0) [0|255] "raw"  RAD
 SG_ ConsecutiveData1 m2 : 15|8@0+ (1,0) [0|255] "raw"  RAD
 SG_ SingleData1 m0 : 15|8@0+ (1,0) [0|255] "raw"  RAD
 SG_ BlockSize m3 : 15|8@0+ (1,0) [0|255] "raw"  RAD
 SG_ UnknownPciLow m4 : 3|4@0+ (1,0) [0|15] "raw"  RAD
 SG_ FlowStatus m3 : 3|4@0+ (1,0) [0|15] "raw"  RAD
 SG_ ConsecutiveSequence m2 : 3|4@0+ (1,0) [0|15] "raw"  RAD
 SG_ FirstFrameLength m1 : 3|12@0+ (1,0) [0|4095] "raw"  RAD
 SG_ SingleFrameLength m0 : 3|4@0+ (1,0) [0|15] "raw"  RAD
 SG_ IsoTpFrameType M : 7|4@0+ (1,0) [0|15] ""  RAD

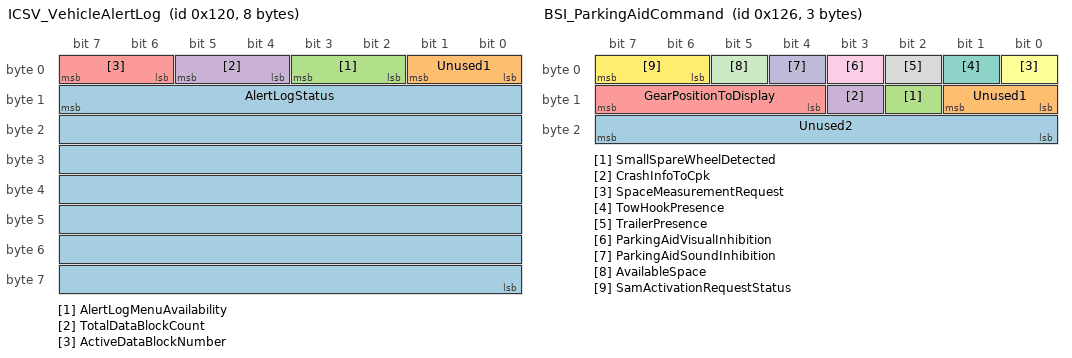
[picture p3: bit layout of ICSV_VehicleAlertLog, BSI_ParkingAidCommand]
BO_ 288 ICSV_VehicleAlertLog: 8 ICSV
 SG_ AlertLogStatus : 15|56@0+ (1,0) [0|7.20575940379279e+16] "raw"  OVIP,BTEL,EMF,CMB,MDS,RAD
 SG_ Unused1 : 1|2@0+ (1,0) [0|3] ""  OVIP,BTEL,EMF,CMB,MDS,RAD
 SG_ AlertLogMenuAvailability : 3|2@0+ (1,0) [0|3] ""  OVIP,BTEL,EMF,CMB,MDS,RAD
 SG_ TotalDataBlockCount : 5|2@0+ (1,0) [0|3] ""  OVIP,BTEL,EMF,CMB,MDS,RAD
 SG_ ActiveDataBlockNumber : 7|2@0+ (1,0) [0|3] ""  OVIP,BTEL,EMF,CMB,MDS,RAD

BO_ 289 BSI_GearboxRestartData: 1 BSI
 SG_ Unused1 : 5|6@0+ (1,0) [0|63] "" Vector__XXX
 SG_ StopStartPreparationStatus : 7|2@0+ (1,0) [0|3] "" Vector__XXX

BO_ 290 CMB_MultiplexedButtonsStatus2: 8 CMB
 SG_ Knob2StepCounter : 63|8@0+ (1,0) [0|255] ""  BSI,RAD,BTEL,OVIP
 SG_ Knob1StepCounter : 55|8@0+ (1,0) [0|255] ""  BSI,RAD,BTEL,OVIP
 SG_ Knob2SyncRequest : 40|1@0+ (1,0) [0|1] ""  BSI,RAD,BTEL,OVIP
 SG_ Knob1SyncRequest : 41|1@0+ (1,0) [0|1] ""  BSI,RAD,BTEL,OVIP
 SG_ FrontPanelBpKeyPressed : 42|1@0+ (1,0) [0|1] ""  BSI,RAD,BTEL,OVIP
 SG_ FrontPanelKey45Pressed : 43|1@0+ (1,0) [0|1] ""  BSI,RAD,BTEL,OVIP
 SG_ PanelKey44Pressed : 44|1@0+ (1,0) [0|1] ""  BSI,RAD,BTEL,OVIP
 SG_ PanelKey43Pressed : 45|1@0+ (1,0) [0|1] ""  BSI,RAD,BTEL,OVIP
 SG_ PanelKey42Pressed : 46|1@0+ (1,0) [0|1] ""  BSI,RAD,BTEL,OVIP
 SG_ PanelKey41Pressed : 47|1@0+ (1,0) [0|1] ""  BSI,RAD,BTEL,OVIP
 SG_ PanelKey40Pressed : 32|1@0+ (1,0) [0|1] ""  BSI,RAD,BTEL,OVIP
 SG_ PanelKey39Pressed : 33|1@0+ (1,0) [0|1] ""  BSI,RAD,BTEL,OVIP
 SG_ PanelKey38Pressed : 34|1@0+ (1,0) [0|1] ""  BSI,RAD,BTEL,OVIP
 SG_ PanelKey37Pressed : 35|1@0+ (1,0) [0|1] ""  BSI,RAD,BTEL,OVIP
 SG_ PanelKey36Pressed : 36|1@0+ (1,0) [0|1] ""  BSI,RAD,BTEL,OVIP
 SG_ PanelKey35Pressed : 37|1@0+ (1,0) [0|1] ""  BSI,RAD,BTEL,OVIP
 SG_ PanelKey34Pressed : 38|1@0+ (1,0) [0|1] ""  BSI,RAD,BTEL,OVIP
 SG_ PanelKey33Pressed : 39|1@0+ (1,0) [0|1] ""  BSI,RAD,BTEL,OVIP
 SG_ PanelKey32Pressed : 24|1@0+ (1,0) [0|1] ""  BSI,RAD,BTEL,OVIP
 SG_ PanelKey31Pressed : 25|1@0+ (1,0) [0|1] ""  BSI,RAD,BTEL,OVIP
 SG_ PanelKey30Pressed : 26|1@0+ (1,0) [0|1] ""  BSI,RAD,BTEL,OVIP
 SG_ PanelKey29Pressed : 27|1@0+ (1,0) [0|1] ""  BSI,RAD,BTEL,OVIP
 SG_ PanelKey28Pressed : 28|1@0+ (1,0) [0|1] ""  BSI,RAD,BTEL,OVIP
 SG_ PanelKey27Pressed : 29|1@0+ (1,0) [0|1] ""  BSI,RAD,BTEL,OVIP
 SG_ PanelKey26Pressed : 30|1@0+ (1,0) [0|1] ""  BSI,RAD,BTEL,OVIP
 SG_ PanelKey25Pressed : 31|1@0+ (1,0) [0|1] ""  BSI,RAD,BTEL,OVIP
 SG_ PanelKey24Pressed : 16|1@0+ (1,0) [0|1] ""  BSI,RAD,BTEL,OVIP
 SG_ PanelKey23Pressed : 17|1@0+ (1,0) [0|1] ""  BSI,RAD,BTEL,OVIP
 SG_ PanelKey22Pressed : 18|1@0+ (1,0) [0|1] ""  BSI,RAD,BTEL,OVIP
 SG_ PanelKey21Pressed : 19|1@0+ (1,0) [0|1] ""  BSI,RAD,BTEL,OVIP
 SG_ PanelKey20Pressed : 20|1@0+ (1,0) [0|1] ""  BSI,RAD,BTEL,OVIP
 SG_ PanelKey19Pressed : 21|1@0+ (1,0) [0|1] ""  BSI,RAD,BTEL,OVIP
 SG_ PanelKey18Pressed : 22|1@0+ (1,0) [0|1] ""  BSI,RAD,BTEL,OVIP
 SG_ PanelKey17Pressed : 23|1@0+ (1,0) [0|1] ""  BSI,RAD,BTEL,OVIP
 SG_ PanelKey16Pressed : 8|1@0+ (1,0) [0|1] ""  BSI,RAD,BTEL,OVIP
 SG_ PanelKey15Pressed : 9|1@0+ (1,0) [0|1] ""  BSI,RAD,BTEL,OVIP
 SG_ PanelKey14Pressed : 10|1@0+ (1,0) [0|1] ""  BSI,RAD,BTEL,OVIP
 SG_ PanelKey13Pressed : 11|1@0+ (1,0) [0|1] ""  BSI,RAD,BTEL,OVIP
 SG_ PanelKey12Pressed : 12|1@0+ (1,0) [0|1] ""  BSI,RAD,BTEL,OVIP
 SG_ PanelKey11Pressed : 13|1@0+ (1,0) [0|1] ""  BSI,RAD,BTEL,OVIP
 SG_ PanelKey10Pressed : 14|1@0+ (1,0) [0|1] ""  BSI,RAD,BTEL,OVIP
 SG_ PanelKey9Pressed : 15|1@0+ (1,0) [0|1] ""  BSI,RAD,BTEL,OVIP
 SG_ PanelKey8Pressed : 0|1@0+ (1,0) [0|1] ""  BSI,RAD,BTEL,OVIP
 SG_ PanelKey7Pressed : 1|1@0+ (1,0) [0|1] ""  BSI,RAD,BTEL,OVIP
 SG_ PanelKey6Pressed : 2|1@0+ (1,0) [0|1] ""  BSI,RAD,BTEL,OVIP
 SG_ PanelKey5Pressed : 3|1@0+ (1,0) [0|1] ""  BSI,RAD,BTEL,OVIP
 SG_ PanelKey4Pressed : 4|1@0+ (1,0) [0|1] ""  BSI,RAD,BTEL,OVIP
 SG_ PanelKey3Pressed : 5|1@0+ (1,0) [0|1] ""  BSI,RAD,BTEL,OVIP
 SG_ PanelKey2Pressed : 6|1@0+ (1,0) [0|1] ""  BSI,RAD,BTEL,OVIP
 SG_ PanelKey1Pressed : 7|1@0+ (1,0) [0|1] ""  BSI,RAD,BTEL,OVIP

BO_ 291 RAD_KmlCallStatus: 8 RAD
 SG_ FlowPadding5 m3 : 63|8@0+ (1,0) [0|255] "raw"  EMF,CRT,FMUX
 SG_ FirstData6 m1 : 63|8@0+ (1,0) [0|255] "raw"  EMF,CRT,FMUX
 SG_ UnknownData7 m4 : 63|8@0+ (1,0) [0|255] "raw"  EMF,CRT,FMUX
 SG_ ConsecutiveData7 m2 : 63|8@0+ (1,0) [0|255] "raw"  EMF,CRT,FMUX
 SG_ SingleData7 m0 : 63|8@0+ (1,0) [0|255] "raw"  EMF,CRT,FMUX
 SG_ FlowPadding4 m3 : 55|8@0+ (1,0) [0|255] "raw"  EMF,CRT,FMUX
 SG_ FirstData5 m1 : 55|8@0+ (1,0) [0|255] "raw"  EMF,CRT,FMUX
 SG_ UnknownData6 m4 : 55|8@0+ (1,0) [0|255] "raw"  EMF,CRT,FMUX
 SG_ ConsecutiveData6 m2 : 55|8@0+ (1,0) [0|255] "raw"  EMF,CRT,FMUX
 SG_ SingleData6 m0 : 55|8@0+ (1,0) [0|255] "raw"  EMF,CRT,FMUX
 SG_ FlowPadding3 m3 : 47|8@0+ (1,0) [0|255] "raw"  EMF,CRT,FMUX
 SG_ FirstData4 m1 : 47|8@0+ (1,0) [0|255] "raw"  EMF,CRT,FMUX
 SG_ UnknownData5 m4 : 47|8@0+ (1,0) [0|255] "raw"  EMF,CRT,FMUX
 SG_ ConsecutiveData5 m2 : 47|8@0+ (1,0) [0|255] "raw"  EMF,CRT,FMUX
 SG_ SingleData5 m0 : 47|8@0+ (1,0) [0|255] "raw"  EMF,CRT,FMUX
 SG_ FlowPadding2 m3 : 39|8@0+ (1,0) [0|255] "raw"  EMF,CRT,FMUX
 SG_ FirstData3 m1 : 39|8@0+ (1,0) [0|255] "raw"  EMF,CRT,FMUX
 SG_ UnknownData4 m4 : 39|8@0+ (1,0) [0|255] "raw"  EMF,CRT,FMUX
 SG_ ConsecutiveData4 m2 : 39|8@0+ (1,0) [0|255] "raw"  EMF,CRT,FMUX
 SG_ SingleData4 m0 : 39|8@0+ (1,0) [0|255] "raw"  EMF,CRT,FMUX
 SG_ FlowPadding1 m3 : 31|8@0+ (1,0) [0|255] "raw"  EMF,CRT,FMUX
 SG_ FirstData2 m1 : 31|8@0+ (1,0) [0|255] "raw"  EMF,CRT,FMUX
 SG_ UnknownData3 m4 : 31|8@0+ (1,0) [0|255] "raw"  EMF,CRT,FMUX
 SG_ ConsecutiveData3 m2 : 31|8@0+ (1,0) [0|255] "raw"  EMF,CRT,FMUX
 SG_ SingleData3 m0 : 31|8@0+ (1,0) [0|255] "raw"  EMF,CRT,FMUX
 SG_ FirstData1 m1 : 23|8@0+ (1,0) [0|255] "raw"  EMF,CRT,FMUX
 SG_ UnknownData2 m4 : 23|8@0+ (1,0) [0|255] "raw"  EMF,CRT,FMUX
 SG_ ConsecutiveData2 m2 : 23|8@0+ (1,0) [0|255] "raw"  EMF,CRT,FMUX
 SG_ SingleData2 m0 : 23|8@0+ (1,0) [0|255] "raw"  EMF,CRT,FMUX
 SG_ SeparationTimeRaw m3 : 23|8@0+ (1,0) [0|255] "raw"  EMF,CRT,FMUX
 SG_ UnknownData1 m4 : 15|8@0+ (1,0) [0|255] "raw"  EMF,CRT,FMUX
 SG_ ConsecutiveData1 m2 : 15|8@0+ (1,0) [0|255] "raw"  EMF,CRT,FMUX
 SG_ SingleData1 m0 : 15|8@0+ (1,0) [0|255] "raw"  EMF,CRT,FMUX
 SG_ BlockSize m3 : 15|8@0+ (1,0) [0|255] "raw"  EMF,CRT,FMUX
 SG_ UnknownPciLow m4 : 3|4@0+ (1,0) [0|15] "raw"  EMF,CRT,FMUX
 SG_ FlowStatus m3 : 3|4@0+ (1,0) [0|15] "raw"  EMF,CRT,FMUX
 SG_ ConsecutiveSequence m2 : 3|4@0+ (1,0) [0|15] "raw"  EMF,CRT,FMUX
 SG_ FirstFrameLength m1 : 3|12@0+ (1,0) [0|4095] "raw"  EMF,CRT,FMUX
 SG_ SingleFrameLength m0 : 3|4@0+ (1,0) [0|15] "raw"  EMF,CRT,FMUX
 SG_ IsoTpFrameType M : 7|4@0+ (1,0) [0|15] ""  EMF,CRT,FMUX

BO_ 293 RAD_Radio: 8 RAD
 SG_ FlowPadding5 m3 : 63|8@0+ (1,0) [0|255] "raw"  EMF
 SG_ FirstData6 m1 : 63|8@0+ (1,0) [0|255] "raw"  EMF
 SG_ UnknownData7 m4 : 63|8@0+ (1,0) [0|255] "raw"  EMF
 SG_ ConsecutiveData7 m2 : 63|8@0+ (1,0) [0|255] "raw"  EMF
 SG_ SingleData7 m0 : 63|8@0+ (1,0) [0|255] "raw"  EMF
 SG_ FlowPadding4 m3 : 55|8@0+ (1,0) [0|255] "raw"  EMF
 SG_ FirstData5 m1 : 55|8@0+ (1,0) [0|255] "raw"  EMF
 SG_ UnknownData6 m4 : 55|8@0+ (1,0) [0|255] "raw"  EMF
 SG_ ConsecutiveData6 m2 : 55|8@0+ (1,0) [0|255] "raw"  EMF
 SG_ SingleData6 m0 : 55|8@0+ (1,0) [0|255] "raw"  EMF
 SG_ FlowPadding3 m3 : 47|8@0+ (1,0) [0|255] "raw"  EMF
 SG_ FirstData4 m1 : 47|8@0+ (1,0) [0|255] "raw"  EMF
 SG_ UnknownData5 m4 : 47|8@0+ (1,0) [0|255] "raw"  EMF
 SG_ ConsecutiveData5 m2 : 47|8@0+ (1,0) [0|255] "raw"  EMF
 SG_ SingleData5 m0 : 47|8@0+ (1,0) [0|255] "raw"  EMF
 SG_ FlowPadding2 m3 : 39|8@0+ (1,0) [0|255] "raw"  EMF
 SG_ FirstData3 m1 : 39|8@0+ (1,0) [0|255] "raw"  EMF
 SG_ UnknownData4 m4 : 39|8@0+ (1,0) [0|255] "raw"  EMF
 SG_ ConsecutiveData4 m2 : 39|8@0+ (1,0) [0|255] "raw"  EMF
 SG_ SingleData4 m0 : 39|8@0+ (1,0) [0|255] "raw"  EMF
 SG_ FlowPadding1 m3 : 31|8@0+ (1,0) [0|255] "raw"  EMF
 SG_ FirstData2 m1 : 31|8@0+ (1,0) [0|255] "raw"  EMF
 SG_ UnknownData3 m4 : 31|8@0+ (1,0) [0|255] "raw"  EMF
 SG_ ConsecutiveData3 m2 : 31|8@0+ (1,0) [0|255] "raw"  EMF
 SG_ SingleData3 m0 : 31|8@0+ (1,0) [0|255] "raw"  EMF
 SG_ FirstData1 m1 : 23|8@0+ (1,0) [0|255] "raw"  EMF
 SG_ UnknownData2 m4 : 23|8@0+ (1,0) [0|255] "raw"  EMF
 SG_ ConsecutiveData2 m2 : 23|8@0+ (1,0) [0|255] "raw"  EMF
 SG_ SingleData2 m0 : 23|8@0+ (1,0) [0|255] "raw"  EMF
 SG_ SeparationTimeRaw m3 : 23|8@0+ (1,0) [0|255] "raw"  EMF
 SG_ UnknownData1 m4 : 15|8@0+ (1,0) [0|255] "raw"  EMF
 SG_ ConsecutiveData1 m2 : 15|8@0+ (1,0) [0|255] "raw"  EMF
 SG_ SingleData1 m0 : 15|8@0+ (1,0) [0|255] "raw"  EMF
 SG_ BlockSize m3 : 15|8@0+ (1,0) [0|255] "raw"  EMF
 SG_ UnknownPciLow m4 : 3|4@0+ (1,0) [0|15] "raw"  EMF
 SG_ FlowStatus m3 : 3|4@0+ (1,0) [0|15] "raw"  EMF
 SG_ ConsecutiveSequence m2 : 3|4@0+ (1,0) [0|15] "raw"  EMF
 SG_ FirstFrameLength m1 : 3|12@0+ (1,0) [0|4095] "raw"  EMF
 SG_ SingleFrameLength m0 : 3|4@0+ (1,0) [0|15] "raw"  EMF
 SG_ IsoTpFrameType M : 7|4@0+ (1,0) [0|15] ""  EMF

BO_ 294 BSI_ParkingAidCommand: 3 BSI
 SG_ Unused2 : 23|8@0+ (1,0) [0|255] ""  ICSV,BTEL,AAS,AVP,OVIP,RAD
 SG_ Unused1 : 9|2@0+ (1,0) [0|3] ""  ICSV,BTEL,AAS,AVP,OVIP,RAD
 SG_ SmallSpareWheelDetected : 10|1@0+ (1,0) [0|1] ""  ICSV,BTEL,AAS,AVP,OVIP,RAD
 SG_ CrashInfoToCpk : 11|1@0+ (1,0) [0|1] ""  ICSV,BTEL,AAS,AVP,OVIP,RAD
 SG_ GearPositionToDisplay : 15|4@0+ (1,0) [0|15] ""  ICSV,BTEL,AAS,AVP,OVIP,RAD
 SG_ SpaceMeasurementRequest : 0|1@0+ (1,0) [0|1] ""  ICSV,BTEL,AAS,AVP,OVIP,RAD
 SG_ TowHookPresence : 1|1@0+ (1,0) [0|1] ""  ICSV,BTEL,AAS,AVP,OVIP,RAD
 SG_ TrailerPresence : 2|1@0+ (1,0) [0|1] ""  ICSV,BTEL,AAS,AVP,OVIP,RAD
 SG_ ParkingAidVisualInhibition : 3|1@0+ (1,0) [0|1] ""  ICSV,BTEL,AAS,AVP,OVIP,RAD
 SG_ ParkingAidSoundInhibition : 4|1@0+ (1,0) [0|1] ""  ICSV,BTEL,AAS,AVP,OVIP,RAD
 SG_ AvailableSpace : 5|1@0+ (1,0) [0|1] ""  ICSV,BTEL,AAS,AVP,OVIP,RAD
 SG_ SamActivationRequestStatus : 7|2@0+ (1,0) [0|3] ""  ICSV,BTEL,AAS,AVP,OVIP,RAD

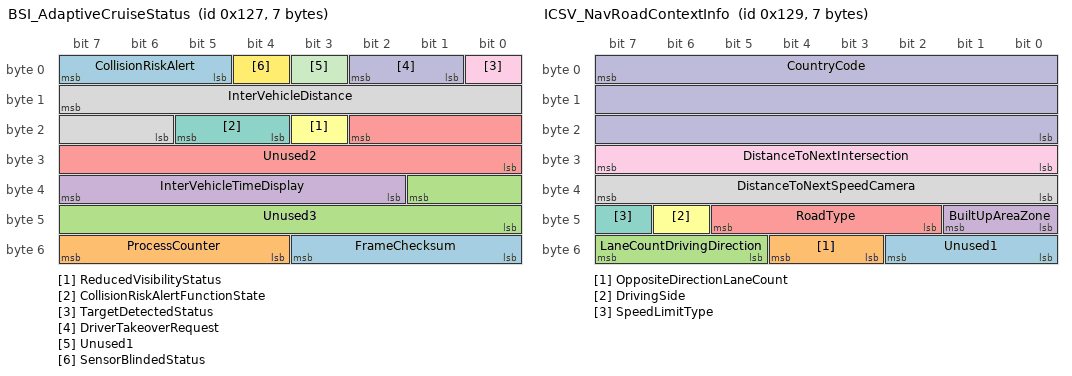
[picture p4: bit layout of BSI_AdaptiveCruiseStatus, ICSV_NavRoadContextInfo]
BO_ 295 BSI_AdaptiveCruiseStatus: 7 BSI
 SG_ FrameChecksum : 51|4@0+ (1,0) [0|15] ""  MATT,VTH
 SG_ ProcessCounter : 55|4@0+ (1,0) [0|15] ""  MATT,VTH
 SG_ Unused3 : 33|10@0+ (1,0) [0|1023] ""  MATT,VTH
 SG_ InterVehicleTimeDisplay : 39|6@0+ (0.1,0) [0|6.3] ""  MATT,VTH
 SG_ Unused2 : 18|11@0+ (1,0) [0|2047] ""  MATT,VTH
 SG_ ReducedVisibilityStatus : 19|1@0+ (1,0) [0|1] ""  MATT,VTH
 SG_ CollisionRiskAlertFunctionState : 21|2@0+ (1,0) [0|3] ""  MATT,VTH
 SG_ InterVehicleDistance : 15|10@0+ (0.25,0) [0|255.75] "m"  MATT,VTH
 SG_ TargetDetectedStatus : 0|1@0+ (1,0) [0|1] ""  MATT,VTH
 SG_ DriverTakeoverRequest : 2|2@0+ (1,0) [0|3] ""  MATT,VTH
 SG_ Unused1 : 3|1@0+ (1,0) [0|1] ""  MATT,VTH
 SG_ SensorBlindedStatus : 4|1@0+ (1,0) [0|1] ""  MATT,VTH
 SG_ CollisionRiskAlert : 7|3@0+ (1,0) [0|7] ""  MATT,VTH

BO_ 296 ICSV_ClusterSignalCommand: 8 ICSV
 SG_ Customization : 56|1@0+ (1,0) [0|1] ""  FMUX,BTEL,CMB,MATT,AVP,OVIP,MDS,RAD
 SG_ ColorChange : 57|1@0+ (1,0) [0|1] ""  FMUX,BTEL,CMB,MATT,AVP,OVIP,MDS,RAD
 SG_ IgnitionReady : 58|1@0+ (1,0) [0|1] ""  FMUX,BTEL,CMB,MATT,AVP,OVIP,MDS,RAD
 SG_ LowFuelBlink : 59|1@0+ (1,0) [0|1] ""  FMUX,BTEL,CMB,MATT,AVP,OVIP,MDS,RAD
 SG_ ClutchPedal : 61|2@0+ (1,0) [0|3] ""  FMUX,BTEL,CMB,MATT,AVP,OVIP,MDS,RAD
 SG_ EngineWarningLampCommand : 63|2@0+ (1,0) [0|3] ""  FMUX,BTEL,CMB,MATT,AVP,OVIP,MDS,RAD
 SG_ FrontPassengerProtection : 48|1@0+ (1,0) [0|1] ""  FMUX,BTEL,CMB,MATT,AVP,OVIP,MDS,RAD
 SG_ Warnings : 49|1@0+ (1,0) [0|1] ""  FMUX,BTEL,CMB,MATT,AVP,OVIP,MDS,RAD
 SG_ OdometerStatus : 50|1@0+ (1,0) [0|1] ""  FMUX,BTEL,CMB,MATT,AVP,OVIP,MDS,RAD
 SG_ RearRightSeatbeltBlinkDuplicate : 51|1@0+ (1,0) [0|1] ""  FMUX,BTEL,CMB,MATT,AVP,OVIP,MDS,RAD
 SG_ RearRightSeatbelt : 52|1@0+ (1,0) [0|1] ""  FMUX,BTEL,CMB,MATT,AVP,OVIP,MDS,RAD
 SG_ RearMiddleSeatbeltBlink : 53|1@0+ (1,0) [0|1] ""  FMUX,BTEL,CMB,MATT,AVP,OVIP,MDS,RAD
 SG_ RearMiddleSeatbelt : 54|1@0+ (1,0) [0|1] ""  FMUX,BTEL,CMB,MATT,AVP,OVIP,MDS,RAD
 SG_ RearLeftSeatbeltBlink : 55|1@0+ (1,0) [0|1] ""  FMUX,BTEL,CMB,MATT,AVP,OVIP,MDS,RAD
 SG_ RearLeftSeatbelt : 40|1@0+ (1,0) [0|1] ""  FMUX,BTEL,CMB,MATT,AVP,OVIP,MDS,RAD
 SG_ RequestPilotLigthScr : 42|2@0+ (1,0) [0|3] ""  FMUX,BTEL,CMB,MATT,AVP,OVIP,MDS,RAD
 SG_ FrontRightSeatbeltBlink : 43|1@0+ (1,0) [0|1] ""  FMUX,BTEL,CMB,MATT,AVP,OVIP,MDS,RAD
 SG_ FrontRightSeatbelt : 44|1@0+ (1,0) [0|1] ""  FMUX,BTEL,CMB,MATT,AVP,OVIP,MDS,RAD
 SG_ FrontLeftSeatbeltBlink : 45|1@0+ (1,0) [0|1] ""  FMUX,BTEL,CMB,MATT,AVP,OVIP,MDS,RAD
 SG_ FrontLeftSeatbelt : 46|1@0+ (1,0) [0|1] ""  FMUX,BTEL,CMB,MATT,AVP,OVIP,MDS,RAD
 SG_ LowFuel : 47|1@0+ (1,0) [0|1] ""  FMUX,BTEL,CMB,MATT,AVP,OVIP,MDS,RAD
 SG_ Suspension : 32|1@0+ (1,0) [0|1] ""  FMUX,BTEL,CMB,MATT,AVP,OVIP,MDS,RAD
 SG_ EspBlink : 33|1@0+ (1,0) [0|1] ""  FMUX,BTEL,CMB,MATT,AVP,OVIP,MDS,RAD
 SG_ EspDesactived : 34|1@0+ (1,0) [0|1] ""  FMUX,BTEL,CMB,MATT,AVP,OVIP,MDS,RAD
 SG_ CafrIndicatorLighting : 35|1@0+ (1,0) [0|1] ""  FMUX,BTEL,CMB,MATT,AVP,OVIP,MDS,RAD
 SG_ AvailablePlaceBlink : 36|1@0+ (1,0) [0|1] ""  FMUX,BTEL,CMB,MATT,AVP,OVIP,MDS,RAD
 SG_ AvailableSpace : 37|1@0+ (1,0) [0|1] ""  FMUX,BTEL,CMB,MATT,AVP,OVIP,MDS,RAD
 SG_ OpenDoorWarningLamp : 38|1@0+ (1,0) [0|1] ""  FMUX,BTEL,CMB,MATT,AVP,OVIP,MDS,RAD
 SG_ Preheat : 39|1@0+ (1,0) [0|1] ""  FMUX,BTEL,CMB,MATT,AVP,OVIP,MDS,RAD
 SG_ ParkingBrakeDesactivated : 24|1@0+ (1,0) [0|1] ""  FMUX,BTEL,CMB,MATT,AVP,OVIP,MDS,RAD
 SG_ ParkingBrakes : 25|1@0+ (1,0) [0|1] ""  FMUX,BTEL,CMB,MATT,AVP,OVIP,MDS,RAD
 SG_ BrakePedal : 27|2@0+ (1,0) [0|3] ""  FMUX,BTEL,CMB,MATT,AVP,OVIP,MDS,RAD
 SG_ PassengerAirbag : 28|1@0+ (1,0) [0|1] ""  FMUX,BTEL,CMB,MATT,AVP,OVIP,MDS,RAD
 SG_ ChildSafety : 29|1@0+ (1,0) [0|1] ""  FMUX,BTEL,CMB,MATT,AVP,OVIP,MDS,RAD
 SG_ Stop : 30|1@0+ (1,0) [0|1] ""  FMUX,BTEL,CMB,MATT,AVP,OVIP,MDS,RAD
 SG_ Maintenance : 31|1@0+ (1,0) [0|1] ""  FMUX,BTEL,CMB,MATT,AVP,OVIP,MDS,RAD
 SG_ GearboxType : 17|2@0+ (1,0) [0|3] ""  FMUX,BTEL,CMB,MATT,AVP,OVIP,MDS,RAD
 SG_ GearShiftArrow : 19|2@0+ (1,0) [0|3] ""  FMUX,BTEL,CMB,MATT,AVP,OVIP,MDS,RAD
 SG_ GearboxMode : 22|3@0+ (1,0) [0|7] ""  FMUX,BTEL,CMB,MATT,AVP,OVIP,MDS,RAD
 SG_ GearShiftArrowBlink : 23|1@0+ (1,0) [0|1] ""  FMUX,BTEL,CMB,MATT,AVP,OVIP,MDS,RAD
 SG_ CurrentGearBlink : 8|1@0+ (1,0) [0|1] ""  FMUX,BTEL,CMB,MATT,AVP,OVIP,MDS,RAD
 SG_ DriveGear : 11|3@0+ (1,0) [0|7] ""  FMUX,BTEL,CMB,MATT,AVP,OVIP,MDS,RAD
 SG_ GearPositionToDisplay : 15|4@0+ (1,0) [0|15] ""  FMUX,BTEL,CMB,MATT,AVP,OVIP,MDS,RAD
 SG_ Daylights : 0|1@0+ (1,0) [0|1] ""  FMUX,BTEL,CMB,MATT,AVP,OVIP,MDS,RAD
 SG_ LeftTurn : 1|1@0+ (1,0) [0|1] ""  FMUX,BTEL,CMB,MATT,AVP,OVIP,MDS,RAD
 SG_ RightTurn : 2|1@0+ (1,0) [0|1] ""  FMUX,BTEL,CMB,MATT,AVP,OVIP,MDS,RAD
 SG_ RearFogLights : 3|1@0+ (1,0) [0|1] ""  FMUX,BTEL,CMB,MATT,AVP,OVIP,MDS,RAD
 SG_ FrontFogLights : 4|1@0+ (1,0) [0|1] ""  FMUX,BTEL,CMB,MATT,AVP,OVIP,MDS,RAD
 SG_ FullBeam : 5|1@0+ (1,0) [0|1] ""  FMUX,BTEL,CMB,MATT,AVP,OVIP,MDS,RAD
 SG_ LowBeam : 6|1@0+ (1,0) [0|1] ""  FMUX,BTEL,CMB,MATT,AVP,OVIP,MDS,RAD
 SG_ Sidelights : 7|1@0+ (1,0) [0|1] ""  FMUX,BTEL,CMB,MATT,AVP,OVIP,MDS,RAD

BO_ 297 ICSV_NavRoadContextInfo: 7 ICSV
 SG_ Unused1 : 50|3@0+ (1,0) [0|7] ""  BSI
 SG_ OppositeDirectionLaneCount : 52|2@0+ (1,0) [0|3] ""  BSI
 SG_ LaneCountDrivingDirection : 55|3@0+ (1,0) [0|7] ""  BSI
 SG_ BuiltUpAreaZone : 41|2@0+ (1,0) [0|3] ""  BSI
 SG_ RoadType : 45|4@0+ (1,0) [0|15] ""  BSI
 SG_ DrivingSide : 46|1@0+ (1,0) [0|1] ""  BSI
 SG_ SpeedLimitType : 47|1@0+ (1,0) [0|1] ""  BSI
 SG_ DistanceToNextSpeedCamera : 39|8@0+ (10,0) [0|1000] "m"  BSI
 SG_ DistanceToNextIntersection : 31|8@0+ (10,0) [0|1000] "m"  BSI
 SG_ CountryCode : 7|24@0+ (1,0) [0|16777215] "raw"  BSI

BO_TX_BU_ 223 : EMF,ICSV;
BO_TX_BU_ 226 : ICSV,CDC;
BO_TX_BU_ 230 : ICSV,BSI;
BO_TX_BU_ 233 : ICSV,CMB;
BO_TX_BU_ 287 : ICSV,EMF;
BO_TX_BU_ 288 : ICSV,BSI;
BO_TX_BU_ 290 : CMB,CRT,EMF,FMUX,ICSV;
BO_TX_BU_ 291 : RAD,ICSV;
BO_TX_BU_ 293 : RAD,ICSV;
BO_TX_BU_ 296 : ICSV,BSI;
BO_TX_BU_ 297 : ICSV,BTEL,OVIP;
CM_ BO_ 223 "DATABASE_CANDIDATE: physical interpretation unverified; capture/layout evidence reported separately. INFO-DIV CAN, 125000 bit/s; CAN ID 0x0DF. PSA-RE title: EMF_MENU_COMMAND. Menu command sent by the EMF module to the radio/display: selected item code, list line count and new value. Source: https://github.com/prototux/PSA-RE/blob/67f7581e7622410efdbb29c7eda3b86982b9b450/buses/AEE2010.full/LS.INFO-DIV/0DF.yml. Source sender alternatives: EMF,ICSV; physical TX/gateway forwarding not verified. ";
CM_ SG_ 223 Unused1 "DATABASE_CANDIDATE: physical interpretation unverified; capture/layout evidence reported separately. PSA-RE bits 4.2-4.0. ";
CM_ SG_ 223 ListRefreshRequest "DATABASE_CANDIDATE: physical interpretation unverified; capture/layout evidence reported separately. PSA-RE bits 4.4-4.3. Request to refresh or stop refreshing the list Upstream default raw=0 (not necessarily valid data).";
CM_ SG_ 223 RepeatEnabled "DATABASE_CANDIDATE: physical interpretation unverified; capture/layout evidence reported separately. PSA-RE bits 4.5. Disc/directory repeat mode activation status Upstream default raw=0 (not necessarily valid data).";
CM_ SG_ 223 ShuffleModeStatus "DATABASE_CANDIDATE: physical interpretation unverified; capture/layout evidence reported separately. PSA-RE bits 4.6. Global shuffle mode activation status Upstream default raw=0 (not necessarily valid data).";
CM_ SG_ 223 RandomEnabled "DATABASE_CANDIDATE: physical interpretation unverified; capture/layout evidence reported separately. PSA-RE bits 4.7. Track/file shuffle mode activation status Upstream default raw=0 (not necessarily valid data).";
CM_ SG_ 223 RadioDabFmStatus "DATABASE_CANDIDATE: physical interpretation unverified; capture/layout evidence reported separately. PSA-RE bits 3.0. Status of the DAB/FM option Upstream default raw=0 (not necessarily valid data).";
CM_ SG_ 223 RadioTextModeStatus "DATABASE_CANDIDATE: physical interpretation unverified; capture/layout evidence reported separately. PSA-RE bits 3.1. Radio Text mode activation status Upstream default raw=0 (not necessarily valid data).";
CM_ SG_ 223 RadioRdsAfStatus "DATABASE_CANDIDATE: physical interpretation unverified; capture/layout evidence reported separately. PSA-RE bits 3.2. Status of RDS alternative frequency (AF) monitoring Upstream default raw=0 (not necessarily valid data).";
CM_ SG_ 223 RadioNewsOption7Status "DATABASE_CANDIDATE: physical interpretation unverified; capture/layout evidence reported separately. PSA-RE bits 3.3. Status of the NEWS7 radio option Upstream default raw=0 (not necessarily valid data).";
CM_ SG_ 223 RadioNewsOption6Status "DATABASE_CANDIDATE: physical interpretation unverified; capture/layout evidence reported separately. PSA-RE bits 3.4. Status of the NEWS6 radio option Upstream default raw=0 (not necessarily valid data).";
CM_ SG_ 223 RadioNewsOption5Status "DATABASE_CANDIDATE: physical interpretation unverified; capture/layout evidence reported separately. PSA-RE bits 3.5. Status of the NEWS5 radio option Upstream default raw=0 (not necessarily valid data).";
CM_ SG_ 223 RadioNewsOption4Status "DATABASE_CANDIDATE: physical interpretation unverified; capture/layout evidence reported separately. PSA-RE bits 3.6. Status of the NEWS4 radio option Upstream default raw=0 (not necessarily valid data).";
CM_ SG_ 223 RadioNewsOption3Status "DATABASE_CANDIDATE: physical interpretation unverified; capture/layout evidence reported separately. PSA-RE bits 3.7. Status of the NEWS3 radio option Upstream default raw=0 (not necessarily valid data).";
CM_ SG_ 223 RadioNewsOption2Status "DATABASE_CANDIDATE: physical interpretation unverified; capture/layout evidence reported separately. PSA-RE bits 2.0. Status of the NEWS2 radio option Upstream default raw=0 (not necessarily valid data).";
CM_ SG_ 223 RadioNewsOption1Status "DATABASE_CANDIDATE: physical interpretation unverified; capture/layout evidence reported separately. PSA-RE bits 2.1. Status of the NEWS1 radio option Upstream default raw=0 (not necessarily valid data).";
CM_ SG_ 223 NextListTypeRequested "DATABASE_CANDIDATE: physical interpretation unverified; capture/layout evidence reported separately. PSA-RE bits 2.4-2.2. Type of the next list requested (directory, artist, genre, playlist) Upstream default raw=0 (not necessarily valid data).";
CM_ SG_ 223 DesignatorBlockType "DATABASE_CANDIDATE: physical interpretation unverified; capture/layout evidence reported separately. PSA-RE bits 2.7-2.5. Type of blocks processed by the device managing the designator button presses Upstream default raw=2 (not necessarily valid data).";
CM_ SG_ 223 ListOpenRequest "DATABASE_CANDIDATE: physical interpretation unverified; capture/layout evidence reported separately. PSA-RE bits 1.3-1.0. Request to open a list (media, paired device, or directory) Upstream default raw=0 (not necessarily valid data).";
CM_ SG_ 223 CdTextModeStatus "DATABASE_CANDIDATE: physical interpretation unverified; capture/layout evidence reported separately. PSA-RE bits 1.4. CD Text mode activation status Upstream default raw=0 (not necessarily valid data).";
CM_ SG_ 223 ModificationInProgress "DATABASE_CANDIDATE: physical interpretation unverified; capture/layout evidence reported separately. PSA-RE bits 1.5. Modification in progress Upstream default raw=0 (not necessarily valid data).";
CM_ SG_ 223 DesignatorButtonManager "DATABASE_CANDIDATE: physical interpretation unverified; capture/layout evidence reported separately. PSA-RE bits 1.7-1.6. Device managing the designator (scroll wheel) button presses Upstream default raw=0 (not necessarily valid data).";
CM_ BO_ 224 "DATABASE_CANDIDATE: physical interpretation unverified; capture/layout evidence reported separately. INFO-DIV CAN, 125000 bit/s; CAN ID 0x0E0. PSA-RE title: IMMOBILIZER_KEY_UCC_ENGINE. Preconditioning (cabin climate scheduling) profile information, defined by the profile message structure. Source: https://github.com/prototux/PSA-RE/blob/67f7581e7622410efdbb29c7eda3b86982b9b450/buses/AEE2010.full/LS.INFO-DIV/0E0.yml. Source sender alternatives: BSI; physical TX/gateway forwarding not verified. Observed 1173 frames in info_apka.csv,info_buzeni_obc.csv,info_charging.csv,info_standby.csv,info_start_jizda.csv,infocan.csv; DLCs [7]. ";
CM_ SG_ 224 AcPrecondSchedule4StartTime "DATABASE_CANDIDATE: physical interpretation unverified; capture/layout evidence reported separately. PSA-RE bits 6.2-7.0. Memorized start time of climate preconditioning schedule 4, in minutes since midnight Upstream default raw=0 (not necessarily valid data).";
CM_ SG_ 224 Unused3 "DATABASE_CANDIDATE: physical interpretation unverified; capture/layout evidence reported separately. PSA-RE bits 6.7-6.3. ";
CM_ SG_ 224 AcPrecondSundaySchedule4Active "DATABASE_CANDIDATE: physical interpretation unverified; capture/layout evidence reported separately. PSA-RE bits 5.0. Memorized activation status of climate preconditioning schedule 4 for Sunday Upstream default raw=0 (not necessarily valid data).";
CM_ SG_ 224 AcPrecondSaturdaySchedule4Active "DATABASE_CANDIDATE: physical interpretation unverified; capture/layout evidence reported separately. PSA-RE bits 5.1. Memorized activation status of climate preconditioning schedule 4 for Saturday Upstream default raw=0 (not necessarily valid data).";
CM_ SG_ 224 AcPrecondFridaySchedule4Active "DATABASE_CANDIDATE: physical interpretation unverified; capture/layout evidence reported separately. PSA-RE bits 5.2. Memorized activation status of climate preconditioning schedule 4 for Friday Upstream default raw=0 (not necessarily valid data).";
CM_ SG_ 224 AcPrecondThursdaySchedule4Active "DATABASE_CANDIDATE: physical interpretation unverified; capture/layout evidence reported separately. PSA-RE bits 5.3. Memorized activation status of climate preconditioning schedule 4 for Thursday Upstream default raw=0 (not necessarily valid data).";
CM_ SG_ 224 AcPrecondWednesdaySchedul_8f02bb "DATABASE_CANDIDATE: physical interpretation unverified; capture/layout evidence reported separately. PSA-RE bits 5.4. Memorized activation status of climate preconditioning schedule 4 for Wednesday Upstream default raw=0 (not necessarily valid data).";
CM_ SG_ 224 AcPrecondTuesdaySchedule4Active "DATABASE_CANDIDATE: physical interpretation unverified; capture/layout evidence reported separately. PSA-RE bits 5.5. Memorized activation status of climate preconditioning schedule 4 for Tuesday Upstream default raw=0 (not necessarily valid data).";
CM_ SG_ 224 AcPrecondMondaySchedule4Active "DATABASE_CANDIDATE: physical interpretation unverified; capture/layout evidence reported separately. PSA-RE bits 5.6. Memorized activation status of climate preconditioning schedule 4 for Monday Upstream default raw=0 (not necessarily valid data).";
CM_ SG_ 224 AcPrecondSchedule4Enabled "DATABASE_CANDIDATE: physical interpretation unverified; capture/layout evidence reported separately. PSA-RE bits 5.7. Memorized global activation status of climate preconditioning schedule 4 Upstream default raw=0 (not necessarily valid data).";
CM_ SG_ 224 AcPrecondSchedule3StartTime "DATABASE_CANDIDATE: physical interpretation unverified; capture/layout evidence reported separately. PSA-RE bits 3.2-4.0. Memorized start time of climate preconditioning schedule 3, in minutes since midnight Upstream default raw=0 (not necessarily valid data).";
CM_ SG_ 224 Unused2 "DATABASE_CANDIDATE: physical interpretation unverified; capture/layout evidence reported separately. PSA-RE bits 3.7-3.3. ";
CM_ SG_ 224 AcPrecondSundaySchedule3Active "DATABASE_CANDIDATE: physical interpretation unverified; capture/layout evidence reported separately. PSA-RE bits 2.0. Memorized activation status of climate preconditioning schedule 3 for Sunday Upstream default raw=0 (not necessarily valid data).";
CM_ SG_ 224 AcPrecondSaturdaySchedule3Active "DATABASE_CANDIDATE: physical interpretation unverified; capture/layout evidence reported separately. PSA-RE bits 2.1. Memorized activation status of climate preconditioning schedule 3 for Saturday Upstream default raw=0 (not necessarily valid data).";
CM_ SG_ 224 AcPrecondFridaySchedule3Active "DATABASE_CANDIDATE: physical interpretation unverified; capture/layout evidence reported separately. PSA-RE bits 2.2. Memorized activation status of climate preconditioning schedule 3 for Friday Upstream default raw=0 (not necessarily valid data).";
CM_ SG_ 224 AcPrecondThursdaySchedule3Active "DATABASE_CANDIDATE: physical interpretation unverified; capture/layout evidence reported separately. PSA-RE bits 2.3. Memorized activation status of climate preconditioning schedule 3 for Thursday Upstream default raw=0 (not necessarily valid data).";
CM_ SG_ 224 AcPrecondWednesdaySchedul_dacc80 "DATABASE_CANDIDATE: physical interpretation unverified; capture/layout evidence reported separately. PSA-RE bits 2.4. Memorized activation status of climate preconditioning schedule 3 for Wednesday Upstream default raw=0 (not necessarily valid data).";
CM_ SG_ 224 AcPrecondTuesdaySchedule3Active "DATABASE_CANDIDATE: physical interpretation unverified; capture/layout evidence reported separately. PSA-RE bits 2.5. Memorized activation status of climate preconditioning schedule 3 for Tuesday Upstream default raw=0 (not necessarily valid data).";
CM_ SG_ 224 AcPrecondMondaySchedule3Active "DATABASE_CANDIDATE: physical interpretation unverified; capture/layout evidence reported separately. PSA-RE bits 2.6. Memorized activation status of climate preconditioning schedule 3 for Monday Upstream default raw=0 (not necessarily valid data).";
CM_ SG_ 224 AcPrecondSchedule3Enabled "DATABASE_CANDIDATE: physical interpretation unverified; capture/layout evidence reported separately. PSA-RE bits 2.7. Memorized global activation status of climate preconditioning schedule 3 Upstream default raw=0 (not necessarily valid data).";
CM_ SG_ 224 Unused1 "DATABASE_CANDIDATE: physical interpretation unverified; capture/layout evidence reported separately. PSA-RE bits 1.7-1.0. ";
CM_ BO_ 225 "DATABASE_CANDIDATE: physical interpretation unverified; capture/layout evidence reported separately. INFO-DIV CAN, 125000 bit/s; CAN ID 0x0E1. PSA-RE title: AAS_DATA. Parking aid status: display request, measured side, beep delay/duration, and distances at front and rear (left, right, centre). Source: https://github.com/prototux/PSA-RE/blob/67f7581e7622410efdbb29c7eda3b86982b9b450/buses/AEE2010.full/LS.INFO-DIV/0E1.yml. Source sender alternatives: AAS; physical TX/gateway forwarding not verified. ";
CM_ SG_ 225 CpkMenuRequest "DATABASE_CANDIDATE: physical interpretation unverified; capture/layout evidence reported separately. PSA-RE bits 8.0. CPK (park assist) menu request Upstream default raw=0 (not necessarily valid data).";
CM_ SG_ 225 Scp9HmiRequest "DATABASE_CANDIDATE: physical interpretation unverified; capture/layout evidence reported separately. PSA-RE bits 8.3-8.1. SCP9 (automatic parking) HMI request Upstream default raw=0 (not necessarily valid data).";
CM_ SG_ 225 Scp6HmiRequest "DATABASE_CANDIDATE: physical interpretation unverified; capture/layout evidence reported separately. PSA-RE bits 8.6-8.4. SCP6 (automatic parking) HMI request Upstream default raw=0 (not necessarily valid data).";
CM_ SG_ 225 Scp9Status "DATABASE_CANDIDATE: physical interpretation unverified; capture/layout evidence reported separately. PSA-RE bits 8.7. SCP9 (automatic parking) status Upstream default raw=0 (not necessarily valid data).";
CM_ SG_ 225 NetworkVoltageBoostRequest "DATABASE_CANDIDATE: physical interpretation unverified; capture/layout evidence reported separately. PSA-RE bits 7.0. Onboard network voltage boost need Upstream default raw=0 (not necessarily valid data).";
CM_ SG_ 225 EngineOnRequest "DATABASE_CANDIDATE: physical interpretation unverified; capture/layout evidence reported separately. PSA-RE bits 7.1. Engine-on request status (for ACPK parking assist HMI) Upstream default raw=0 (not necessarily valid data).";
CM_ SG_ 225 SpaceMeasurementDisplayRequest "DATABASE_CANDIDATE: physical interpretation unverified; capture/layout evidence reported separately. PSA-RE bits 7.2. Request to display the evaluation result of the measured parking spot Upstream default raw=0 (not necessarily valid data).";
CM_ SG_ 225 MeasuredDistance "DATABASE_CANDIDATE: physical interpretation unverified; capture/layout evidence reported separately. PSA-RE bits 7.4-7.3. System evaluation of the measured parking spot size Upstream default raw=0 (not necessarily valid data).";
CM_ SG_ 225 SpaceMeasurementStatus "DATABASE_CANDIDATE: physical interpretation unverified; capture/layout evidence reported separately. PSA-RE bits 7.7-7.5. Available space measurement system status Upstream default raw=6 (not necessarily valid data).";
CM_ SG_ 225 Unused2 "DATABASE_CANDIDATE: physical interpretation unverified; capture/layout evidence reported separately. PSA-RE bits 6.0. ";
CM_ SG_ 225 AasDisplayRequest "DATABASE_CANDIDATE: physical interpretation unverified; capture/layout evidence reported separately. PSA-RE bits 6.1. Parking assist display request Upstream default raw=0 (not necessarily valid data).";
CM_ SG_ 225 FrontRightStatus "DATABASE_CANDIDATE: physical interpretation unverified; capture/layout evidence reported separately. PSA-RE bits 6.4-6.2. Obstacle distance for the parking aid display unit Upstream default raw=7 (not necessarily valid data).";
CM_ SG_ 225 FrontMiddleStatus "DATABASE_CANDIDATE: physical interpretation unverified; capture/layout evidence reported separately. PSA-RE bits 6.7-6.5. Obstacle distance for the parking aid display unit Upstream default raw=7 (not necessarily valid data).";
CM_ SG_ 225 LateralBeepLocation "DATABASE_CANDIDATE: physical interpretation unverified; capture/layout evidence reported separately. PSA-RE bits 5.1-5.0. Front / rear location for the lateral parking assist beep Upstream default raw=0 (not necessarily valid data).";
CM_ SG_ 225 FrontLeftStatus "DATABASE_CANDIDATE: physical interpretation unverified; capture/layout evidence reported separately. PSA-RE bits 5.4-5.2. Obstacle distance for the parking aid display unit Upstream default raw=7 (not necessarily valid data).";
CM_ SG_ 225 RearRightStatus "DATABASE_CANDIDATE: physical interpretation unverified; capture/layout evidence reported separately. PSA-RE bits 5.7-5.5. Obstacle distance for the parking aid display unit Upstream default raw=7 (not necessarily valid data).";
CM_ SG_ 225 ScpLampStatus "DATABASE_CANDIDATE: physical interpretation unverified; capture/layout evidence reported separately. PSA-RE bits 4.1-4.0. SCP (automatic parking) telltale lamp status Upstream default raw=0 (not necessarily valid data).";
CM_ SG_ 225 RearMiddleStatus "DATABASE_CANDIDATE: physical interpretation unverified; capture/layout evidence reported separately. PSA-RE bits 4.4-4.2. Obstacle distance for the parking aid display unit Upstream default raw=7 (not necessarily valid data).";
CM_ SG_ 225 RearLeftStatus "DATABASE_CANDIDATE: physical interpretation unverified; capture/layout evidence reported separately. PSA-RE bits 4.7-4.5. Obstacle distance for the parking aid display unit Upstream default raw=7 (not necessarily valid data).";
CM_ SG_ 225 ParkAssistBeepInterval "DATABASE_CANDIDATE: physical interpretation unverified; capture/layout evidence reported separately. PSA-RE bits 3.5-3.0. Time between two parking assist beeps Upstream default raw=63 (not necessarily valid data).";
CM_ SG_ 225 ParkAssistBeepDuration "DATABASE_CANDIDATE: physical interpretation unverified; capture/layout evidence reported separately. PSA-RE bits 3.7-3.6. Parking assist beep duration (provisional) Upstream default raw=0 (not necessarily valid data).";
CM_ SG_ 225 Unused1 "DATABASE_CANDIDATE: physical interpretation unverified; capture/layout evidence reported separately. PSA-RE bits 2.0. ";
CM_ SG_ 225 LateralParkAssistStatus "DATABASE_CANDIDATE: physical interpretation unverified; capture/layout evidence reported separately. PSA-RE bits 2.3-2.1. Lateral ultrasonic park assist status Upstream default raw=0 (not necessarily valid data).";
CM_ SG_ 225 SoundEnabled "DATABASE_CANDIDATE: physical interpretation unverified; capture/layout evidence reported separately. PSA-RE bits 2.4. Audio activation request (parking assist) Upstream default raw=0 (not necessarily valid data).";
CM_ SG_ 225 SoundFr "DATABASE_CANDIDATE: physical interpretation unverified; capture/layout evidence reported separately. PSA-RE bits 2.5. Front / rear location for the parking assist beep Upstream default raw=0 (not necessarily valid data).";
CM_ SG_ 225 SoundLr "DATABASE_CANDIDATE: physical interpretation unverified; capture/layout evidence reported separately. PSA-RE bits 2.7-2.6. Left / right distribution area for the parking assist beep (audio) Upstream default raw=0 (not necessarily valid data).";
CM_ SG_ 225 CpkSelection "DATABASE_CANDIDATE: physical interpretation unverified; capture/layout evidence reported separately. PSA-RE bits 1.1-1.0. Choice of the CPK manoeuvre side Upstream default raw=0 (not necessarily valid data).";
CM_ SG_ 225 FrontStatus "DATABASE_CANDIDATE: physical interpretation unverified; capture/layout evidence reported separately. PSA-RE bits 1.4-1.2. Front parking assist status Upstream default raw=6 (not necessarily valid data).";
CM_ SG_ 225 RearParkAssistStatus "DATABASE_CANDIDATE: physical interpretation unverified; capture/layout evidence reported separately. PSA-RE bits 1.7-1.5. Rear parking assist status Upstream default raw=6 (not necessarily valid data).";
CM_ BO_ 226 "DATABASE_CANDIDATE: physical interpretation unverified; capture/layout evidence reported separately. INFO-DIV CAN, 125000 bit/s; CAN ID 0x0E2. PSA-RE title: CD_CHANGER_DISK_LIST_STATUS. CD changer per-slot disk status (6 slots), preset selection and reply type. Source: https://github.com/prototux/PSA-RE/blob/67f7581e7622410efdbb29c7eda3b86982b9b450/buses/AEE2010.full/LS.INFO-DIV/0E2.yml. Source sender alternatives: ICSV,CDC; physical TX/gateway forwarding not verified. ";
CM_ SG_ 226 Unused4 "DATABASE_CANDIDATE: physical interpretation unverified; capture/layout evidence reported separately. PSA-RE bits 8.7-8.0. ";
CM_ SG_ 226 DiscStatus6 "DATABASE_CANDIDATE: physical interpretation unverified; capture/layout evidence reported separately. PSA-RE bits 7.1-7.0. Status of disc 6 Upstream default raw=0 (not necessarily valid data).";
CM_ SG_ 226 DiscFormat6 "DATABASE_CANDIDATE: physical interpretation unverified; capture/layout evidence reported separately. PSA-RE bits 7.3-7.2. Format of disc 6 Upstream default raw=0 (not necessarily valid data).";
CM_ SG_ 226 DiscStatus5 "DATABASE_CANDIDATE: physical interpretation unverified; capture/layout evidence reported separately. PSA-RE bits 7.5-7.4. Status of disc 5 Upstream default raw=0 (not necessarily valid data).";
CM_ SG_ 226 DiscFormat5 "DATABASE_CANDIDATE: physical interpretation unverified; capture/layout evidence reported separately. PSA-RE bits 7.7-7.6. Format of disc 5 Upstream default raw=0 (not necessarily valid data).";
CM_ SG_ 226 DiscStatus4 "DATABASE_CANDIDATE: physical interpretation unverified; capture/layout evidence reported separately. PSA-RE bits 6.1-6.0. Status of disc 4 Upstream default raw=0 (not necessarily valid data).";
CM_ SG_ 226 DiscFormat4 "DATABASE_CANDIDATE: physical interpretation unverified; capture/layout evidence reported separately. PSA-RE bits 6.3-6.2. Format of disc 4 Upstream default raw=0 (not necessarily valid data).";
CM_ SG_ 226 DiscStatus3 "DATABASE_CANDIDATE: physical interpretation unverified; capture/layout evidence reported separately. PSA-RE bits 6.5-6.4. Status of disc 3 Upstream default raw=0 (not necessarily valid data).";
CM_ SG_ 226 DiscFormat3 "DATABASE_CANDIDATE: physical interpretation unverified; capture/layout evidence reported separately. PSA-RE bits 6.7-6.6. Format of disc 3 Upstream default raw=0 (not necessarily valid data).";
CM_ SG_ 226 DiscStatus2 "DATABASE_CANDIDATE: physical interpretation unverified; capture/layout evidence reported separately. PSA-RE bits 5.1-5.0. Status of disc 2 Upstream default raw=0 (not necessarily valid data).";
CM_ SG_ 226 DiscFormat2 "DATABASE_CANDIDATE: physical interpretation unverified; capture/layout evidence reported separately. PSA-RE bits 5.3-5.2. Format of disc 2 Upstream default raw=0 (not necessarily valid data).";
CM_ SG_ 226 DiscStatus1 "DATABASE_CANDIDATE: physical interpretation unverified; capture/layout evidence reported separately. PSA-RE bits 5.5-5.4. Status of disc 1 Upstream default raw=0 (not necessarily valid data).";
CM_ SG_ 226 DiscFormat1 "DATABASE_CANDIDATE: physical interpretation unverified; capture/layout evidence reported separately. PSA-RE bits 5.7-5.6. Format of disc 1 Upstream default raw=0 (not necessarily valid data).";
CM_ SG_ 226 Unused3 "DATABASE_CANDIDATE: physical interpretation unverified; capture/layout evidence reported separately. PSA-RE bits 4.3-4.0. ";
CM_ SG_ 226 SelectedPresetNumber "DATABASE_CANDIDATE: physical interpretation unverified; capture/layout evidence reported separately. PSA-RE bits 4.7-4.4. Number of the selected preset Upstream default raw=0 (not necessarily valid data).";
CM_ SG_ 226 Unused2 "DATABASE_CANDIDATE: physical interpretation unverified; capture/layout evidence reported separately. PSA-RE bits 3.1-3.0. ";
CM_ SG_ 226 CdcListCommand "DATABASE_CANDIDATE: physical interpretation unverified; capture/layout evidence reported separately. PSA-RE bits 3.3-3.2. CD/MP3 list command Upstream default raw=0 (not necessarily valid data).";
CM_ SG_ 226 CdcDirectoryType "DATABASE_CANDIDATE: physical interpretation unverified; capture/layout evidence reported separately. PSA-RE bits 3.7-3.4. Type of directory sent by the CD changer Upstream default raw=0 (not necessarily valid data).";
CM_ SG_ 226 Unused1 "DATABASE_CANDIDATE: physical interpretation unverified; capture/layout evidence reported separately. PSA-RE bits 1.7-2.0. ";
CM_ BO_ 230 "DATABASE_CANDIDATE: physical interpretation unverified; capture/layout evidence reported separately. INFO-DIV CAN, 125000 bit/s; CAN ID 0x0E6. PSA-RE title: BRAKE_UNIT_STATUS. Brake unit status relayed by the body computer: brake fluid alert, hill-hold request, wheel pulse counters and start&stop brake demand. Source: https://github.com/prototux/PSA-RE/blob/67f7581e7622410efdbb29c7eda3b86982b9b450/buses/AEE2010.full/LS.INFO-DIV/0E6.yml. Source sender alternatives: ICSV,BSI; physical TX/gateway forwarding not verified. Observed 1703 frames in info_apka.csv,info_buzeni_obc.csv,info_charging.csv,info_standby.csv,info_start_jizda.csv,infocan.csv; DLCs [8]. ";
CM_ SG_ 230 BrakeEcuFrame5Checksum "DATABASE_CANDIDATE: physical interpretation unverified; capture/layout evidence reported separately. PSA-RE bits 8.3-8.0. Checksum of dynamic frame 5 from the brake ECU";
CM_ SG_ 230 ProcessCounter4bit "DATABASE_CANDIDATE: physical interpretation unverified; capture/layout evidence reported separately. PSA-RE bits 8.7-8.4. 4-bit process counter Upstream default raw=0 (not necessarily valid data).";
CM_ SG_ 230 Unused2 "DATABASE_CANDIDATE: physical interpretation unverified; capture/layout evidence reported separately. PSA-RE bits 7.3-7.0. ";
CM_ SG_ 230 BrakeFunctionNeedForStartStop "DATABASE_CANDIDATE: physical interpretation unverified; capture/layout evidence reported separately. PSA-RE bits 7.5-7.4. Brake function requirement for the stop-start (STT) system Upstream default raw=0 (not necessarily valid data).";
CM_ SG_ 230 BrakeEcuPowerManagementFault "DATABASE_CANDIDATE: physical interpretation unverified; capture/layout evidence reported separately. PSA-RE bits 7.6. Electrical power management fault detected by the brake ECU Upstream default raw=0 (not necessarily valid data).";
CM_ SG_ 230 EmergencyBrakingSignaliza_517ee3 "DATABASE_CANDIDATE: physical interpretation unverified; capture/layout evidence reported separately. PSA-RE bits 7.7. Indicates whether the emergency braking signal function is implemented in the brake ECU Upstream default raw=0 (not necessarily valid data).";
CM_ SG_ 230 BatteryVoltageUcBrake "DATABASE_CANDIDATE: physical interpretation unverified; capture/layout evidence reported separately. PSA-RE bits 6.7-6.0. Battery voltage measured by the brake ECU Raw invalid=255; numeric DBC decoders may still scale it: check raw before use.";
CM_ SG_ 230 RearRightWheelSpinCounter "DATABASE_CANDIDATE: physical interpretation unverified; capture/layout evidence reported separately. PSA-RE bits 4.6-5.0. Free-running rear right wheel speed sensor pulse counter";
CM_ SG_ 230 RearRightWheelSpeedSensorFault "DATABASE_CANDIDATE: physical interpretation unverified; capture/layout evidence reported separately. PSA-RE bits 4.7. Rear right wheel-speed pulse counter malfunction";
CM_ SG_ 230 RearLeftWheelSpinCounter "DATABASE_CANDIDATE: physical interpretation unverified; capture/layout evidence reported separately. PSA-RE bits 2.6-3.0. Free-running rear left wheel speed sensor pulse counter";
CM_ SG_ 230 RearLeftWheelSpeedSensorFault "DATABASE_CANDIDATE: physical interpretation unverified; capture/layout evidence reported separately. PSA-RE bits 2.7. Rear left wheel-speed pulse counter malfunction";
CM_ SG_ 230 AbsFaultLampRequest "DATABASE_CANDIDATE: physical interpretation unverified; capture/layout evidence reported separately. PSA-RE bits 1.0. ABS fault warning lamp activation request";
CM_ SG_ 230 BrakeFluidLevelAlert "DATABASE_CANDIDATE: physical interpretation unverified; capture/layout evidence reported separately. PSA-RE bits 1.1. Brake fluid level alert";
CM_ SG_ 230 WornBrakePadsIndicator "DATABASE_CANDIDATE: physical interpretation unverified; capture/layout evidence reported separately. PSA-RE bits 1.2. Brake pad wear indicator";
CM_ SG_ 230 RefInProgress "DATABASE_CANDIDATE: physical interpretation unverified; capture/layout evidence reported separately. PSA-RE bits 1.3. Electronic brake force distribution (REF) regulation in progress Upstream default raw=0 (not necessarily valid data).";
CM_ SG_ 230 AutomaticHazardLightsByUcBrake "DATABASE_CANDIDATE: physical interpretation unverified; capture/layout evidence reported separately. PSA-RE bits 1.4. Indicates whether the automatic hazard warning lights function is implemented in the brake ECU Upstream default raw=0 (not necessarily valid data).";
CM_ SG_ 230 AbsInProgress "DATABASE_CANDIDATE: physical interpretation unverified; capture/layout evidence reported separately. PSA-RE bits 1.5. ABS regulation in progress";
CM_ SG_ 230 Unused1 "DATABASE_CANDIDATE: physical interpretation unverified; capture/layout evidence reported separately. PSA-RE bits 1.6. ";
CM_ SG_ 230 RefFaultLamp "DATABASE_CANDIDATE: physical interpretation unverified; capture/layout evidence reported separately. PSA-RE bits 1.7. Electronic brake force distribution (REF) fault warning lamp activation request";
CM_ BO_ 231 "DATABASE_CANDIDATE: physical interpretation unverified; capture/layout evidence reported separately. INFO-DIV CAN, 125000 bit/s; CAN ID 0x0E7. PSA-RE title: DASHCAM_LED_REQUEST. Request to light the LEDs of the dashcam recording buttons, sent by the dashcam (IDVR). Source: https://github.com/prototux/PSA-RE/blob/67f7581e7622410efdbb29c7eda3b86982b9b450/buses/AEE2010.full/LS.INFO-DIV/0E7.yml. Source sender alternatives: IDVR; physical TX/gateway forwarding not verified. ";
CM_ SG_ 231 Unused1 "DATABASE_CANDIDATE: physical interpretation unverified; capture/layout evidence reported separately. PSA-RE bits 1.0. ";
CM_ SG_ 231 FrontCollisionWarningRequest "DATABASE_CANDIDATE: physical interpretation unverified; capture/layout evidence reported separately. PSA-RE bits 1.1. Front collision warning request (for IDVR) Upstream default raw=0 (not necessarily valid data).";
CM_ SG_ 231 AbnormalLaneCrossingRight "DATABASE_CANDIDATE: physical interpretation unverified; capture/layout evidence reported separately. PSA-RE bits 1.2. Abnormal right-hand lane crossing (for IDVR) Upstream default raw=0 (not necessarily valid data).";
CM_ SG_ 231 AbnormalLaneCrossingLeft "DATABASE_CANDIDATE: physical interpretation unverified; capture/layout evidence reported separately. PSA-RE bits 1.3. Abnormal left-hand lane crossing (for IDVR) Upstream default raw=0 (not necessarily valid data).";
CM_ SG_ 231 StlPushLedRequest "DATABASE_CANDIDATE: physical interpretation unverified; capture/layout evidence reported separately. PSA-RE bits 1.5-1.4. Request to light the LED on the lateral path control button (for IDVR) Upstream default raw=0 (not necessarily valid data).";
CM_ SG_ 231 ArcPushLedRequest "DATABASE_CANDIDATE: physical interpretation unverified; capture/layout evidence reported separately. PSA-RE bits 1.7-1.6. Request to light the LED on the front collision warning button Upstream default raw=0 (not necessarily valid data).";
CM_ BO_ 232 "DATABASE_CANDIDATE: physical interpretation unverified; capture/layout evidence reported separately. INFO-DIV CAN, 125000 bit/s; CAN ID 0x0E8. PSA-RE title: ENGINE_UNLOCK_STATUS_CLIENT. Powertrain dynamic data: instantaneous and percentage boost, power and torque. Source: https://github.com/prototux/PSA-RE/blob/67f7581e7622410efdbb29c7eda3b86982b9b450/buses/AEE2010.full/LS.INFO-DIV/0E8.yml. Source sender alternatives: BSI; physical TX/gateway forwarding not verified. Observed 2933 frames in info_apka.csv,info_buzeni_obc.csv,info_charging.csv,info_standby.csv,info_start_jizda.csv,infocan.csv; DLCs [6]. ";
CM_ SG_ 232 PowertrainTorquePercent "DATABASE_CANDIDATE: physical interpretation unverified; capture/layout evidence reported separately. PSA-RE bits 6.6-6.0. Powertrain torque percentage Raw invalid=101; numeric DBC decoders may still scale it: check raw before use. Upstream default raw=0 (not necessarily valid data).";
CM_ SG_ 232 PowertrainTorqueInstant "DATABASE_CANDIDATE: physical interpretation unverified; capture/layout evidence reported separately. PSA-RE bits 5.7-6.7. Powertrain instantaneous torque value Upstream default raw=0 (not necessarily valid data).";
CM_ SG_ 232 PowertrainBoostPercent "DATABASE_CANDIDATE: physical interpretation unverified; capture/layout evidence reported separately. PSA-RE bits 4.6-4.0. Powertrain boost percentage Raw invalid=101; numeric DBC decoders may still scale it: check raw before use. Upstream default raw=0 (not necessarily valid data).";
CM_ SG_ 232 Unused2 "DATABASE_CANDIDATE: physical interpretation unverified; capture/layout evidence reported separately. PSA-RE bits 4.7. ";
CM_ SG_ 232 Unused1 "DATABASE_CANDIDATE: physical interpretation unverified; capture/layout evidence reported separately. PSA-RE bits 3.1-3.0. ";
CM_ SG_ 232 PowertrainBoostInstant "DATABASE_CANDIDATE: physical interpretation unverified; capture/layout evidence reported separately. PSA-RE bits 3.7-3.2. Powertrain instantaneous boost value Upstream default raw=0 (not necessarily valid data).";
CM_ SG_ 232 PowertrainPowerPercent "DATABASE_CANDIDATE: physical interpretation unverified; capture/layout evidence reported separately. PSA-RE bits 2.6-2.0. Powertrain power percentage Raw invalid=101; numeric DBC decoders may still scale it: check raw before use. Upstream default raw=0 (not necessarily valid data).";
CM_ SG_ 232 PowertrainPowerInstant "DATABASE_CANDIDATE: physical interpretation unverified; capture/layout evidence reported separately. PSA-RE bits 1.7-2.7. Powertrain instantaneous power value Upstream default raw=0 (not necessarily valid data).";
CM_ BO_ 233 "DATABASE_CANDIDATE: physical interpretation unverified; capture/layout evidence reported separately. INFO-DIV CAN, 125000 bit/s; CAN ID 0x0E9. PSA-RE title: NAV_EXPORT_FLOW_CONTROL. ISO-TP flow-control frame for the second navigation export multi-frame transfer. Source: https://github.com/prototux/PSA-RE/blob/67f7581e7622410efdbb29c7eda3b86982b9b450/buses/AEE2010.full/LS.INFO-DIV/0E9.yml. Source sender alternatives: ICSV,CMB; physical TX/gateway forwarding not verified. WIRE ISO-TP ONLY: normal addressing candidate, maximum Classical CAN DLC 8; actual DLC may be shorter. Data includes padding. No reassembly, text, DID or application-layer decoding. Original application layouts are preserved in source JSON; do not decode them at wire offsets. ";
CM_ SG_ 233 FlowPadding5 "TRANSPORT_CANDIDATE: normal-addressing ISO-TP. PSA-RE bits 8.7-8.0. ";
CM_ SG_ 233 FirstData6 "TRANSPORT_CANDIDATE: normal-addressing ISO-TP. PSA-RE bits 8.7-8.0. ";
CM_ SG_ 233 UnknownData7 "TRANSPORT_CANDIDATE: normal-addressing ISO-TP. PSA-RE bits 8.7-8.0. ";
CM_ SG_ 233 ConsecutiveData7 "TRANSPORT_CANDIDATE: normal-addressing ISO-TP. PSA-RE bits 8.7-8.0. ";
CM_ SG_ 233 SingleData7 "TRANSPORT_CANDIDATE: normal-addressing ISO-TP. PSA-RE bits 8.7-8.0. ";
CM_ SG_ 233 FlowPadding4 "TRANSPORT_CANDIDATE: normal-addressing ISO-TP. PSA-RE bits 7.7-7.0. ";
CM_ SG_ 233 FirstData5 "TRANSPORT_CANDIDATE: normal-addressing ISO-TP. PSA-RE bits 7.7-7.0. ";
CM_ SG_ 233 UnknownData6 "TRANSPORT_CANDIDATE: normal-addressing ISO-TP. PSA-RE bits 7.7-7.0. ";
CM_ SG_ 233 ConsecutiveData6 "TRANSPORT_CANDIDATE: normal-addressing ISO-TP. PSA-RE bits 7.7-7.0. ";
CM_ SG_ 233 SingleData6 "TRANSPORT_CANDIDATE: normal-addressing ISO-TP. PSA-RE bits 7.7-7.0. ";
CM_ SG_ 233 FlowPadding3 "TRANSPORT_CANDIDATE: normal-addressing ISO-TP. PSA-RE bits 6.7-6.0. ";
CM_ SG_ 233 FirstData4 "TRANSPORT_CANDIDATE: normal-addressing ISO-TP. PSA-RE bits 6.7-6.0. ";
CM_ SG_ 233 UnknownData5 "TRANSPORT_CANDIDATE: normal-addressing ISO-TP. PSA-RE bits 6.7-6.0. ";
CM_ SG_ 233 ConsecutiveData5 "TRANSPORT_CANDIDATE: normal-addressing ISO-TP. PSA-RE bits 6.7-6.0. ";
CM_ SG_ 233 SingleData5 "TRANSPORT_CANDIDATE: normal-addressing ISO-TP. PSA-RE bits 6.7-6.0. ";
CM_ SG_ 233 FlowPadding2 "TRANSPORT_CANDIDATE: normal-addressing ISO-TP. PSA-RE bits 5.7-5.0. ";
CM_ SG_ 233 FirstData3 "TRANSPORT_CANDIDATE: normal-addressing ISO-TP. PSA-RE bits 5.7-5.0. ";
CM_ SG_ 233 UnknownData4 "TRANSPORT_CANDIDATE: normal-addressing ISO-TP. PSA-RE bits 5.7-5.0. ";
CM_ SG_ 233 ConsecutiveData4 "TRANSPORT_CANDIDATE: normal-addressing ISO-TP. PSA-RE bits 5.7-5.0. ";
CM_ SG_ 233 SingleData4 "TRANSPORT_CANDIDATE: normal-addressing ISO-TP. PSA-RE bits 5.7-5.0. ";
CM_ SG_ 233 FlowPadding1 "TRANSPORT_CANDIDATE: normal-addressing ISO-TP. PSA-RE bits 4.7-4.0. ";
CM_ SG_ 233 FirstData2 "TRANSPORT_CANDIDATE: normal-addressing ISO-TP. PSA-RE bits 4.7-4.0. ";
CM_ SG_ 233 UnknownData3 "TRANSPORT_CANDIDATE: normal-addressing ISO-TP. PSA-RE bits 4.7-4.0. ";
CM_ SG_ 233 ConsecutiveData3 "TRANSPORT_CANDIDATE: normal-addressing ISO-TP. PSA-RE bits 4.7-4.0. ";
CM_ SG_ 233 SingleData3 "TRANSPORT_CANDIDATE: normal-addressing ISO-TP. PSA-RE bits 4.7-4.0. ";
CM_ SG_ 233 FirstData1 "TRANSPORT_CANDIDATE: normal-addressing ISO-TP. PSA-RE bits 3.7-3.0. ";
CM_ SG_ 233 UnknownData2 "TRANSPORT_CANDIDATE: normal-addressing ISO-TP. PSA-RE bits 3.7-3.0. ";
CM_ SG_ 233 ConsecutiveData2 "TRANSPORT_CANDIDATE: normal-addressing ISO-TP. PSA-RE bits 3.7-3.0. ";
CM_ SG_ 233 SingleData2 "TRANSPORT_CANDIDATE: normal-addressing ISO-TP. PSA-RE bits 3.7-3.0. ";
CM_ SG_ 233 SeparationTimeRaw "TRANSPORT_CANDIDATE: normal-addressing ISO-TP. PSA-RE bits 3.7-3.0. Raw STmin code; 0xF1..0xF9 are not milliseconds.";
CM_ SG_ 233 UnknownData1 "TRANSPORT_CANDIDATE: normal-addressing ISO-TP. PSA-RE bits 2.7-2.0. ";
CM_ SG_ 233 ConsecutiveData1 "TRANSPORT_CANDIDATE: normal-addressing ISO-TP. PSA-RE bits 2.7-2.0. ";
CM_ SG_ 233 SingleData1 "TRANSPORT_CANDIDATE: normal-addressing ISO-TP. PSA-RE bits 2.7-2.0. ";
CM_ SG_ 233 BlockSize "TRANSPORT_CANDIDATE: normal-addressing ISO-TP. PSA-RE bits 2.7-2.0. ";
CM_ SG_ 233 UnknownPciLow "TRANSPORT_CANDIDATE: normal-addressing ISO-TP. PSA-RE bits 1.3-1.0. ";
CM_ SG_ 233 FlowStatus "TRANSPORT_CANDIDATE: normal-addressing ISO-TP. PSA-RE bits 1.3-1.0. ";
CM_ SG_ 233 ConsecutiveSequence "TRANSPORT_CANDIDATE: normal-addressing ISO-TP. PSA-RE bits 1.3-1.0. ";
CM_ SG_ 233 FirstFrameLength "TRANSPORT_CANDIDATE: normal-addressing ISO-TP. PSA-RE bits 1.3-2.0. 12-bit declared PDU length; not a reassembled value.";
CM_ SG_ 233 SingleFrameLength "TRANSPORT_CANDIDATE: normal-addressing ISO-TP. PSA-RE bits 1.3-1.0. Declared data length; not a validity check.";
CM_ SG_ 233 IsoTpFrameType "TRANSPORT_CANDIDATE: normal-addressing ISO-TP. PSA-RE bits 1.7-1.4. PCI high nibble; normal addressing candidate.";
CM_ BO_ 246 "OWNER_CONFIRMED_FIELDS: TotalMileage, ExternalFilteredTemperature; other fields remain candidates. INFO-DIV CAN, 125000 bit/s; CAN ID 0x0F6. PSA-RE title: BSI_SLOW_DATA_2. Vehicle state broadcast by the body controller: lighting/dimming, power supply state and key position, coolant temperature, odometer, outside temperature. Source: https://github.com/prototux/PSA-RE/blob/67f7581e7622410efdbb29c7eda3b86982b9b450/buses/AEE2010.full/LS.INFO-DIV/0F6.yml. Source sender alternatives: BSI; physical TX/gateway forwarding not verified. Observed 1183 frames in info_apka.csv,info_buzeni_obc.csv,info_charging.csv,info_standby.csv,info_start_jizda.csv,infocan.csv; DLCs [8]. ";
CM_ SG_ 246 BlinkersStatus "DATABASE_CANDIDATE: physical interpretation unverified; capture/layout evidence reported separately. PSA-RE bits 8.1-8.0. Turn indicator state Upstream default raw=0 (not necessarily valid data).";
CM_ SG_ 246 ConnectorAreaLightCommand "DATABASE_CANDIDATE: physical interpretation unverified; capture/layout evidence reported separately. PSA-RE bits 8.2. Interface/connector area lighting command Upstream default raw=0 (not necessarily valid data).";
CM_ SG_ 246 ClusterIndicatorsTest "DATABASE_CANDIDATE: physical interpretation unverified; capture/layout evidence reported separately. PSA-RE bits 8.3. Instrument cluster telltale lamps test Upstream default raw=0 (not necessarily valid data).";
CM_ SG_ 246 WheelPosition "DATABASE_CANDIDATE: physical interpretation unverified; capture/layout evidence reported separately. PSA-RE bits 8.5-8.4. Type of vehicle steering (left-hand / right-hand drive) Upstream default raw=0 (not necessarily valid data).";
CM_ SG_ 246 FrontWipersStatus "DATABASE_CANDIDATE: physical interpretation unverified; capture/layout evidence reported separately. PSA-RE bits 8.6. Confirmed front wiping Upstream default raw=0 (not necessarily valid data).";
CM_ SG_ 246 ReverseStatus "DATABASE_CANDIDATE: physical interpretation unverified; capture/layout evidence reported separately. PSA-RE bits 8.7. Reverse gear state Upstream default raw=0 (not necessarily valid data).";
CM_ SG_ 246 ExternalFilteredTemperature "OWNER_CONFIRMED: owner Opel Corsa-e, 2026-10-31; Owner confirms BSI_SlowData2 data matches the vehicle. Scope: Currently consumed odometer and filtered outside temperature; remaining fields have not been checked individually.. PSA-RE bits 7.7-7.0. Filtered outside temperature Raw invalid=255; numeric DBC decoders may still scale it: check raw before use. Upstream default raw=255 (not necessarily valid data).";
CM_ SG_ 246 ExternalTemperature "DATABASE_CANDIDATE: physical interpretation unverified; capture/layout evidence reported separately. PSA-RE bits 6.7-6.0. Outside temperature, T = N/2 - 40 °C; specific codes indicate sensor absent or unmanaged Raw invalid=255; numeric DBC decoders may still scale it: check raw before use. Upstream default raw=252 (not necessarily valid data).";
CM_ SG_ 246 TotalMileage "OWNER_CONFIRMED: owner Opel Corsa-e, 2026-10-31; Owner confirms BSI_SlowData2 data matches the vehicle. Scope: Currently consumed odometer and filtered outside temperature; remaining fields have not been checked individually.. PSA-RE bits 3.7-5.0. Vehicle odometer, 0.1 km per bit; invalid when all bits set Raw invalid=16777215; numeric DBC decoders may still scale it: check raw before use. Upstream default raw=16777215 (not necessarily valid data).";
CM_ SG_ 246 CoolantTemperature "DATABASE_CANDIDATE: physical interpretation unverified; capture/layout evidence reported separately. PSA-RE bits 2.7-2.0. Coolant temperature Raw invalid=255; numeric DBC decoders may still scale it: check raw before use. Upstream default raw=60 (not necessarily valid data).";
CM_ SG_ 246 PowertrainStatus "DATABASE_CANDIDATE: physical interpretation unverified; capture/layout evidence reported separately. PSA-RE bits 1.1-1.0. Powertrain operating status (off, stopped, starting, restarting, running) Upstream default raw=0 (not necessarily valid data).";
CM_ SG_ 246 GenStatus "DATABASE_CANDIDATE: physical interpretation unverified; capture/layout evidence reported separately. PSA-RE bits 1.2. Generator state Upstream default raw=0 (not necessarily valid data).";
CM_ SG_ 246 MainStatus "DATABASE_CANDIDATE: physical interpretation unverified; capture/layout evidence reported separately. PSA-RE bits 1.4-1.3. Vehicle electrical system main state Upstream default raw=0 (not necessarily valid data).";
CM_ SG_ 246 FactoryPark "DATABASE_CANDIDATE: physical interpretation unverified; capture/layout evidence reported separately. PSA-RE bits 1.5. Factory park (storage) configuration Upstream default raw=0 (not necessarily valid data).";
CM_ SG_ 246 ConfigMode "DATABASE_CANDIDATE: physical interpretation unverified; capture/layout evidence reported separately. PSA-RE bits 1.7-1.6. Configuration mode Upstream default raw=2 (not necessarily valid data).";
CM_ BO_ 257 "DATABASE_CANDIDATE: physical interpretation unverified; capture/layout evidence reported separately. INFO-DIV CAN, 125000 bit/s; CAN ID 0x101. PSA-RE title: SCR_VERSION. Data payload sent by the wireless charger module, carrying navigation export information. Source: https://github.com/prototux/PSA-RE/blob/67f7581e7622410efdbb29c7eda3b86982b9b450/buses/AEE2010.full/LS.INFO-DIV/101.yml. Source sender alternatives: WLC; physical TX/gateway forwarding not verified. WIRE ISO-TP ONLY: normal addressing candidate, maximum Classical CAN DLC 8; actual DLC may be shorter. Data includes padding. No reassembly, text, DID or application-layer decoding. Original application layouts are preserved in source JSON; do not decode them at wire offsets. Unresolved alternative source layouts preserved in source JSON. ";
CM_ SG_ 257 FlowPadding5 "TRANSPORT_CANDIDATE: normal-addressing ISO-TP. PSA-RE bits 8.7-8.0. ";
CM_ SG_ 257 FirstData6 "TRANSPORT_CANDIDATE: normal-addressing ISO-TP. PSA-RE bits 8.7-8.0. ";
CM_ SG_ 257 UnknownData7 "TRANSPORT_CANDIDATE: normal-addressing ISO-TP. PSA-RE bits 8.7-8.0. ";
CM_ SG_ 257 ConsecutiveData7 "TRANSPORT_CANDIDATE: normal-addressing ISO-TP. PSA-RE bits 8.7-8.0. ";
CM_ SG_ 257 SingleData7 "TRANSPORT_CANDIDATE: normal-addressing ISO-TP. PSA-RE bits 8.7-8.0. ";
CM_ SG_ 257 FlowPadding4 "TRANSPORT_CANDIDATE: normal-addressing ISO-TP. PSA-RE bits 7.7-7.0. ";
CM_ SG_ 257 FirstData5 "TRANSPORT_CANDIDATE: normal-addressing ISO-TP. PSA-RE bits 7.7-7.0. ";
CM_ SG_ 257 UnknownData6 "TRANSPORT_CANDIDATE: normal-addressing ISO-TP. PSA-RE bits 7.7-7.0. ";
CM_ SG_ 257 ConsecutiveData6 "TRANSPORT_CANDIDATE: normal-addressing ISO-TP. PSA-RE bits 7.7-7.0. ";
CM_ SG_ 257 SingleData6 "TRANSPORT_CANDIDATE: normal-addressing ISO-TP. PSA-RE bits 7.7-7.0. ";
CM_ SG_ 257 FlowPadding3 "TRANSPORT_CANDIDATE: normal-addressing ISO-TP. PSA-RE bits 6.7-6.0. ";
CM_ SG_ 257 FirstData4 "TRANSPORT_CANDIDATE: normal-addressing ISO-TP. PSA-RE bits 6.7-6.0. ";
CM_ SG_ 257 UnknownData5 "TRANSPORT_CANDIDATE: normal-addressing ISO-TP. PSA-RE bits 6.7-6.0. ";
CM_ SG_ 257 ConsecutiveData5 "TRANSPORT_CANDIDATE: normal-addressing ISO-TP. PSA-RE bits 6.7-6.0. ";
CM_ SG_ 257 SingleData5 "TRANSPORT_CANDIDATE: normal-addressing ISO-TP. PSA-RE bits 6.7-6.0. ";
CM_ SG_ 257 FlowPadding2 "TRANSPORT_CANDIDATE: normal-addressing ISO-TP. PSA-RE bits 5.7-5.0. ";
CM_ SG_ 257 FirstData3 "TRANSPORT_CANDIDATE: normal-addressing ISO-TP. PSA-RE bits 5.7-5.0. ";
CM_ SG_ 257 UnknownData4 "TRANSPORT_CANDIDATE: normal-addressing ISO-TP. PSA-RE bits 5.7-5.0. ";
CM_ SG_ 257 ConsecutiveData4 "TRANSPORT_CANDIDATE: normal-addressing ISO-TP. PSA-RE bits 5.7-5.0. ";
CM_ SG_ 257 SingleData4 "TRANSPORT_CANDIDATE: normal-addressing ISO-TP. PSA-RE bits 5.7-5.0. ";
CM_ SG_ 257 FlowPadding1 "TRANSPORT_CANDIDATE: normal-addressing ISO-TP. PSA-RE bits 4.7-4.0. ";
CM_ SG_ 257 FirstData2 "TRANSPORT_CANDIDATE: normal-addressing ISO-TP. PSA-RE bits 4.7-4.0. ";
CM_ SG_ 257 UnknownData3 "TRANSPORT_CANDIDATE: normal-addressing ISO-TP. PSA-RE bits 4.7-4.0. ";
CM_ SG_ 257 ConsecutiveData3 "TRANSPORT_CANDIDATE: normal-addressing ISO-TP. PSA-RE bits 4.7-4.0. ";
CM_ SG_ 257 SingleData3 "TRANSPORT_CANDIDATE: normal-addressing ISO-TP. PSA-RE bits 4.7-4.0. ";
CM_ SG_ 257 FirstData1 "TRANSPORT_CANDIDATE: normal-addressing ISO-TP. PSA-RE bits 3.7-3.0. ";
CM_ SG_ 257 UnknownData2 "TRANSPORT_CANDIDATE: normal-addressing ISO-TP. PSA-RE bits 3.7-3.0. ";
CM_ SG_ 257 ConsecutiveData2 "TRANSPORT_CANDIDATE: normal-addressing ISO-TP. PSA-RE bits 3.7-3.0. ";
CM_ SG_ 257 SingleData2 "TRANSPORT_CANDIDATE: normal-addressing ISO-TP. PSA-RE bits 3.7-3.0. ";
CM_ SG_ 257 SeparationTimeRaw "TRANSPORT_CANDIDATE: normal-addressing ISO-TP. PSA-RE bits 3.7-3.0. Raw STmin code; 0xF1..0xF9 are not milliseconds.";
CM_ SG_ 257 UnknownData1 "TRANSPORT_CANDIDATE: normal-addressing ISO-TP. PSA-RE bits 2.7-2.0. ";
CM_ SG_ 257 ConsecutiveData1 "TRANSPORT_CANDIDATE: normal-addressing ISO-TP. PSA-RE bits 2.7-2.0. ";
CM_ SG_ 257 SingleData1 "TRANSPORT_CANDIDATE: normal-addressing ISO-TP. PSA-RE bits 2.7-2.0. ";
CM_ SG_ 257 BlockSize "TRANSPORT_CANDIDATE: normal-addressing ISO-TP. PSA-RE bits 2.7-2.0. ";
CM_ SG_ 257 UnknownPciLow "TRANSPORT_CANDIDATE: normal-addressing ISO-TP. PSA-RE bits 1.3-1.0. ";
CM_ SG_ 257 FlowStatus "TRANSPORT_CANDIDATE: normal-addressing ISO-TP. PSA-RE bits 1.3-1.0. ";
CM_ SG_ 257 ConsecutiveSequence "TRANSPORT_CANDIDATE: normal-addressing ISO-TP. PSA-RE bits 1.3-1.0. ";
CM_ SG_ 257 FirstFrameLength "TRANSPORT_CANDIDATE: normal-addressing ISO-TP. PSA-RE bits 1.3-2.0. 12-bit declared PDU length; not a reassembled value.";
CM_ SG_ 257 SingleFrameLength "TRANSPORT_CANDIDATE: normal-addressing ISO-TP. PSA-RE bits 1.3-1.0. Declared data length; not a validity check.";
CM_ SG_ 257 IsoTpFrameType "TRANSPORT_CANDIDATE: normal-addressing ISO-TP. PSA-RE bits 1.7-1.4. PCI high nibble; normal addressing candidate.";
CM_ BO_ 267 "DATABASE_CANDIDATE: physical interpretation unverified; capture/layout evidence reported separately. INFO-DIV CAN, 125000 bit/s; CAN ID 0x10B. PSA-RE title: STEERING_WHEEL_ANGLE_RELAY. Steering wheel angle data relayed to the car-comfort bus by the body computer (BSI) gateway. Source: https://github.com/prototux/PSA-RE/blob/67f7581e7622410efdbb29c7eda3b86982b9b450/buses/AEE2010.full/LS.INFO-DIV/10B.yml. Source sender alternatives: BSI; physical TX/gateway forwarding not verified. Observed 284 frames in info_start_jizda.csv; DLCs [7]. Unresolved alternative source layouts preserved in source JSON. ";
CM_ SG_ 267 Unused1 "DATABASE_CANDIDATE: physical interpretation unverified; capture/layout evidence reported separately. PSA-RE bits 7.3-7.0. ";
CM_ SG_ 267 SteeringWheelAngleSource "DATABASE_CANDIDATE: physical interpretation unverified; capture/layout evidence reported separately. PSA-RE bits 7.5-7.4. Indication of the source of the steering wheel angle information Upstream default raw=0 (not necessarily valid data).";
CM_ SG_ 267 SteeringWheelAngleInaccurate "DATABASE_CANDIDATE: physical interpretation unverified; capture/layout evidence reported separately. PSA-RE bits 7.6. Steering wheel angle flagged as inaccurate Upstream default raw=1 (not necessarily valid data).";
CM_ SG_ 267 SteeringWheelAngleInitialized "DATABASE_CANDIDATE: physical interpretation unverified; capture/layout evidence reported separately. PSA-RE bits 7.7. Steering wheel angle initialization flag Upstream default raw=1 (not necessarily valid data).";
CM_ SG_ 267 SteeringWheelRotationSpee_effc71 "DATABASE_CANDIDATE: physical interpretation unverified; capture/layout evidence reported separately. PSA-RE bits 6.7-6.0. Steering wheel rotation speed, optimized response time Raw invalid=255; numeric DBC decoders may still scale it: check raw before use.";
CM_ SG_ 267 SteeringWheelAngleSensorP_3a627b "DATABASE_CANDIDATE: physical interpretation unverified; capture/layout evidence reported separately. PSA-RE bits 5.3-5.0. Rolling counter of the steering wheel angle sensor calculation";
CM_ SG_ 267 SteeringWheelAngleChecksum "DATABASE_CANDIDATE: physical interpretation unverified; capture/layout evidence reported separately. PSA-RE bits 5.7-5.4. Steering wheel angle signal checksum";
CM_ SG_ 267 SteeringWheelAngleSensorStatus "DATABASE_CANDIDATE: physical interpretation unverified; capture/layout evidence reported separately. PSA-RE bits 4.0. Internal status of the steering wheel angle sensor";
CM_ SG_ 267 SteeringWheelAngleSensorC_affc57 "DATABASE_CANDIDATE: physical interpretation unverified; capture/layout evidence reported separately. PSA-RE bits 4.1. Steering wheel angle sensor calibration status";
CM_ SG_ 267 SteeringWheelAngleSensorA_f0288c "DATABASE_CANDIDATE: physical interpretation unverified; capture/layout evidence reported separately. PSA-RE bits 4.2. Indication of the supplier factory trim of the steering wheel angle sensor";
CM_ SG_ 267 SteeringWheelAngleSensorF_3754bb "DATABASE_CANDIDATE: physical interpretation unverified; capture/layout evidence reported separately. PSA-RE bits 4.6-4.3. Steering wheel angle sensor fault code";
CM_ SG_ 267 SteeringWheelRotationDirection "DATABASE_CANDIDATE: physical interpretation unverified; capture/layout evidence reported separately. PSA-RE bits 4.7. Steering wheel angle sensor rotation direction";
CM_ SG_ 267 SteeringWheelRotationSpeed "DATABASE_CANDIDATE: physical interpretation unverified; capture/layout evidence reported separately. PSA-RE bits 3.7-3.0. Steering wheel rotation speed Raw invalid=255; numeric DBC decoders may still scale it: check raw before use.";
CM_ SG_ 267 SteeringWheelAngle "DATABASE_CANDIDATE: physical interpretation unverified; capture/layout evidence reported separately. PSA-RE bits 1.7-2.0. Steering wheel angle Raw invalid=32767; numeric DBC decoders may still scale it: check raw before use.";
CM_ BO_ 274 "DATABASE_CANDIDATE: physical interpretation unverified; capture/layout evidence reported separately. INFO-DIV CAN, 125000 bit/s; CAN ID 0x112. PSA-RE title: BSI_VERSION. Alert sound requests sent by the BSI to the telematics unit: sound harmonisation, localisation, level, noise reduction and priority. Source: https://github.com/prototux/PSA-RE/blob/67f7581e7622410efdbb29c7eda3b86982b9b450/buses/AEE2010.full/LS.INFO-DIV/112.yml. Source sender alternatives: BSI; physical TX/gateway forwarding not verified. ";
CM_ SG_ 274 Unused1 "DATABASE_CANDIDATE: physical interpretation unverified; capture/layout evidence reported separately. PSA-RE bits 4.3-4.0. ";
CM_ SG_ 274 HmiSoundHarmonyRequest "DATABASE_CANDIDATE: physical interpretation unverified; capture/layout evidence reported separately. PSA-RE bits 4.7-4.4. Requested sound harmony (family) for the HMI alert";
CM_ SG_ 274 HmiSoundPriorityRequest "DATABASE_CANDIDATE: physical interpretation unverified; capture/layout evidence reported separately. PSA-RE bits 3.2-3.0. Requested priority level for the HMI alert sound";
CM_ SG_ 274 HmiSoundNumberRequest "DATABASE_CANDIDATE: physical interpretation unverified; capture/layout evidence reported separately. PSA-RE bits 3.7-3.3. Requested number of repetitions for the HMI alert sound";
CM_ SG_ 274 HmiSoundLevelRequest "DATABASE_CANDIDATE: physical interpretation unverified; capture/layout evidence reported separately. PSA-RE bits 2.7-2.0. Requested volume level for the HMI alert sound";
CM_ SG_ 274 RawBits4_7 "RAW. PSA-RE bits 1.3-1.0. Unmapped/padding bits, no physical interpretation.";
CM_ SG_ 274 HmiSoundLocationRequest "DATABASE_CANDIDATE: physical interpretation unverified; capture/layout evidence reported separately. PSA-RE bits 1.7-1.4. Requested speaker location for the HMI alert sound Unresolved source alternatives: [{\"note\": \"Also observed at bits 1.7-1.0\", \"bits\": \"1.7-1.0\"}]";
CM_ BO_ 283 "DATABASE_CANDIDATE: physical interpretation unverified; capture/layout evidence reported separately. INFO-DIV CAN, 125000 bit/s; CAN ID 0x11B. PSA-RE title: BEBA_VERSION. Climate preconditioning weekly programming screen requests from the remote app (part 2). Source: https://github.com/prototux/PSA-RE/blob/67f7581e7622410efdbb29c7eda3b86982b9b450/buses/AEE2010.full/LS.INFO-DIV/11B.yml. Source sender alternatives: MDS; physical TX/gateway forwarding not verified. ";
CM_ SG_ 283 ClimatePrecondRemoteSlot4_321752 "DATABASE_CANDIDATE: physical interpretation unverified; capture/layout evidence reported separately. PSA-RE bits 6.2-7.0. Start time of remote thermal preconditioning schedule 4";
CM_ SG_ 283 RawBits40_44 "RAW. PSA-RE bits 6.7-6.3. Unmapped/padding bits, no physical interpretation.";
CM_ SG_ 283 ClimatePrecondRemoteSunda_f317f4 "DATABASE_CANDIDATE: physical interpretation unverified; capture/layout evidence reported separately. PSA-RE bits 5.0. Remote thermal preconditioning schedule 4 enabled (Sunday)";
CM_ SG_ 283 ClimatePrecondRemoteSatur_993fe6 "DATABASE_CANDIDATE: physical interpretation unverified; capture/layout evidence reported separately. PSA-RE bits 5.1. Remote thermal preconditioning schedule 4 enabled (Saturday)";
CM_ SG_ 283 ClimatePrecondRemoteFrida_b8e5fa "DATABASE_CANDIDATE: physical interpretation unverified; capture/layout evidence reported separately. PSA-RE bits 5.2. Remote thermal preconditioning schedule 4 enabled (Friday)";
CM_ SG_ 283 ClimatePrecondRemoteThurs_ff4734 "DATABASE_CANDIDATE: physical interpretation unverified; capture/layout evidence reported separately. PSA-RE bits 5.3. Remote thermal preconditioning schedule 4 enabled (Thursday)";
CM_ SG_ 283 ClimatePrecondRemoteWedne_4ee4b3 "DATABASE_CANDIDATE: physical interpretation unverified; capture/layout evidence reported separately. PSA-RE bits 5.4. Remote thermal preconditioning schedule 4 enabled (Wednesday)";
CM_ SG_ 283 ClimatePrecondRemoteTuesd_931c43 "DATABASE_CANDIDATE: physical interpretation unverified; capture/layout evidence reported separately. PSA-RE bits 5.5. Remote thermal preconditioning schedule 4 enabled (Tuesday)";
CM_ SG_ 283 ClimatePrecondRemoteMonda_aa1b42 "DATABASE_CANDIDATE: physical interpretation unverified; capture/layout evidence reported separately. PSA-RE bits 5.6. Remote thermal preconditioning schedule 4 enabled (Monday)";
CM_ SG_ 283 ClimatePrecondRemoteSlot4Enabled "DATABASE_CANDIDATE: physical interpretation unverified; capture/layout evidence reported separately. PSA-RE bits 5.7. Remote thermal preconditioning schedule 4 enabled";
CM_ SG_ 283 ClimatePrecondRemoteSlot3_8e10d4 "DATABASE_CANDIDATE: physical interpretation unverified; capture/layout evidence reported separately. PSA-RE bits 3.2-4.0. Start time of remote thermal preconditioning schedule 3";
CM_ SG_ 283 RawBits16_20 "RAW. PSA-RE bits 3.7-3.3. Unmapped/padding bits, no physical interpretation.";
CM_ SG_ 283 ClimatePrecondRemoteSunda_628b10 "DATABASE_CANDIDATE: physical interpretation unverified; capture/layout evidence reported separately. PSA-RE bits 2.0. Remote thermal preconditioning schedule 3 enabled (Sunday)";
CM_ SG_ 283 ClimatePrecondRemoteSatur_18e3bf "DATABASE_CANDIDATE: physical interpretation unverified; capture/layout evidence reported separately. PSA-RE bits 2.1. Remote thermal preconditioning schedule 3 enabled (Saturday)";
CM_ SG_ 283 ClimatePrecondRemoteFrida_c5f06a "DATABASE_CANDIDATE: physical interpretation unverified; capture/layout evidence reported separately. PSA-RE bits 2.2. Remote thermal preconditioning schedule 3 enabled (Friday)";
CM_ SG_ 283 ClimatePrecondRemoteThurs_3604aa "DATABASE_CANDIDATE: physical interpretation unverified; capture/layout evidence reported separately. PSA-RE bits 2.3. Remote thermal preconditioning schedule 3 enabled (Thursday)";
CM_ SG_ 283 ClimatePrecondRemoteWedne_be6e1a "DATABASE_CANDIDATE: physical interpretation unverified; capture/layout evidence reported separately. PSA-RE bits 2.4. Remote thermal preconditioning schedule 3 enabled (Wednesday)";
CM_ SG_ 283 ClimatePrecondRemoteTuesd_46cf5d "DATABASE_CANDIDATE: physical interpretation unverified; capture/layout evidence reported separately. PSA-RE bits 2.5. Remote thermal preconditioning schedule 3 enabled (Tuesday)";
CM_ SG_ 283 ClimatePrecondRemoteMonda_edf0b6 "DATABASE_CANDIDATE: physical interpretation unverified; capture/layout evidence reported separately. PSA-RE bits 2.6. Remote thermal preconditioning schedule 3 enabled (Monday)";
CM_ SG_ 283 ClimatePrecondRemoteSlot3Enabled "DATABASE_CANDIDATE: physical interpretation unverified; capture/layout evidence reported separately. PSA-RE bits 2.7. Remote thermal preconditioning schedule 3 enabled";
CM_ SG_ 283 RawByte1 "RAW. PSA-RE bits 1.7-1.0. Unmapped/padding bits, no physical interpretation.";
CM_ BO_ 284 "DATABASE_CANDIDATE: physical interpretation unverified; capture/layout evidence reported separately. INFO-DIV CAN, 125000 bit/s; CAN ID 0x11C. PSA-RE title: COLUMN_MODULE_DIAG_INFO_CVM. Faults and requests relayed by the body computer between column-mounted modules: wiper state, headlamp and degraded-mode requests, lever alignment faults. Source: https://github.com/prototux/PSA-RE/blob/67f7581e7622410efdbb29c7eda3b86982b9b450/buses/AEE2010.full/LS.INFO-DIV/11C.yml. Source sender alternatives: BSI; physical TX/gateway forwarding not verified. ";
CM_ SG_ 284 Unused2 "DATABASE_CANDIDATE: physical interpretation unverified; capture/layout evidence reported separately. PSA-RE bits 4.4-4.0. ";
CM_ SG_ 284 SpeedInfoRobustnessFlag "DATABASE_CANDIDATE: physical interpretation unverified; capture/layout evidence reported separately. PSA-RE bits 4.5. Robustness flag of the vehicle speed information Upstream default raw=0 (not necessarily valid data).";
CM_ SG_ 284 SpeedSignType "DATABASE_CANDIDATE: physical interpretation unverified; capture/layout evidence reported separately. PSA-RE bits 4.7-4.6. Type of speed sign read (speed limit start or end of limited area) Upstream default raw=3 (not necessarily valid data).";
CM_ SG_ 284 IlvSpeedToDisplay "DATABASE_CANDIDATE: physical interpretation unverified; capture/layout evidence reported separately. PSA-RE bits 3.7-3.0. ILV speed information to display Raw invalid=255; numeric DBC decoders may still scale it: check raw before use. Upstream default raw=254 (not necessarily valid data).";
CM_ SG_ 284 Unused1 "DATABASE_CANDIDATE: physical interpretation unverified; capture/layout evidence reported separately. PSA-RE bits 2.0. ";
CM_ SG_ 284 CdpStatus "DATABASE_CANDIDATE: physical interpretation unverified; capture/layout evidence reported separately. PSA-RE bits 2.1. CDP module status (normal or faulty) Upstream default raw=0 (not necessarily valid data).";
CM_ SG_ 284 RainSensorWiperState "DATABASE_CANDIDATE: physical interpretation unverified; capture/layout evidence reported separately. PSA-RE bits 2.3-2.2. Wiper state controlled by the rain sensor Upstream default raw=0 (not necessarily valid data).";
CM_ SG_ 284 WiperSweepSpeed "DATABASE_CANDIDATE: physical interpretation unverified; capture/layout evidence reported separately. PSA-RE bits 2.7-2.4. Wiper sweep speed Upstream default raw=0 (not necessarily valid data).";
CM_ SG_ 284 CdlStatus "DATABASE_CANDIDATE: physical interpretation unverified; capture/layout evidence reported separately. PSA-RE bits 1.0. CDL module status (normal or faulty) Upstream default raw=0 (not necessarily valid data).";
CM_ SG_ 284 AafRequest "DATABASE_CANDIDATE: physical interpretation unverified; capture/layout evidence reported separately. PSA-RE bits 1.1. AAF request Upstream default raw=0 (not necessarily valid data).";
CM_ SG_ 284 CafrBrightnessStatus "DATABASE_CANDIDATE: physical interpretation unverified; capture/layout evidence reported separately. PSA-RE bits 1.2. CAFR brightness validity status Upstream default raw=0 (not necessarily valid data).";
CM_ SG_ 284 CafrFunctionFault "DATABASE_CANDIDATE: physical interpretation unverified; capture/layout evidence reported separately. PSA-RE bits 1.3. CAFR function status (normal or faulty) Upstream default raw=0 (not necessarily valid data).";
CM_ SG_ 284 LowHighBeamSwitchingRequest "DATABASE_CANDIDATE: physical interpretation unverified; capture/layout evidence reported separately. PSA-RE bits 1.4. Low/high beam switching request Upstream default raw=0 (not necessarily valid data).";
CM_ SG_ 284 AbnormalLaneDepartureLeft "DATABASE_CANDIDATE: physical interpretation unverified; capture/layout evidence reported separately. PSA-RE bits 1.5. Abnormal left lane departure detected. Upstream default raw=0 (not necessarily valid data).";
CM_ SG_ 284 AbnormalLaneDepartureRight "DATABASE_CANDIDATE: physical interpretation unverified; capture/layout evidence reported separately. PSA-RE bits 1.6. Abnormal right lane departure detected. Upstream default raw=0 (not necessarily valid data).";
CM_ SG_ 284 StlFaultPresent "DATABASE_CANDIDATE: physical interpretation unverified; capture/layout evidence reported separately. PSA-RE bits 1.7. Fault present in the lane departure warning system (STL). Upstream default raw=0 (not necessarily valid data).";
CM_ BO_ 287 "DATABASE_CANDIDATE: physical interpretation unverified; capture/layout evidence reported separately. INFO-DIV CAN, 125000 bit/s; CAN ID 0x11F. PSA-RE title: RADIO_REPLY_FLOW_CONTROL. ISO-TP flow control frame for the radio reply multi-frame reply (block size, flow status, separation time). Source: https://github.com/prototux/PSA-RE/blob/67f7581e7622410efdbb29c7eda3b86982b9b450/buses/AEE2010.full/LS.INFO-DIV/11F.yml. Source sender alternatives: ICSV,EMF; physical TX/gateway forwarding not verified. WIRE ISO-TP ONLY: normal addressing candidate, maximum Classical CAN DLC 8; actual DLC may be shorter. Data includes padding. No reassembly, text, DID or application-layer decoding. Original application layouts are preserved in source JSON; do not decode them at wire offsets. ";
CM_ SG_ 287 FlowPadding5 "TRANSPORT_CANDIDATE: normal-addressing ISO-TP. PSA-RE bits 8.7-8.0. ";
CM_ SG_ 287 FirstData6 "TRANSPORT_CANDIDATE: normal-addressing ISO-TP. PSA-RE bits 8.7-8.0. ";
CM_ SG_ 287 UnknownData7 "TRANSPORT_CANDIDATE: normal-addressing ISO-TP. PSA-RE bits 8.7-8.0. ";
CM_ SG_ 287 ConsecutiveData7 "TRANSPORT_CANDIDATE: normal-addressing ISO-TP. PSA-RE bits 8.7-8.0. ";
CM_ SG_ 287 SingleData7 "TRANSPORT_CANDIDATE: normal-addressing ISO-TP. PSA-RE bits 8.7-8.0. ";
CM_ SG_ 287 FlowPadding4 "TRANSPORT_CANDIDATE: normal-addressing ISO-TP. PSA-RE bits 7.7-7.0. ";
CM_ SG_ 287 FirstData5 "TRANSPORT_CANDIDATE: normal-addressing ISO-TP. PSA-RE bits 7.7-7.0. ";
CM_ SG_ 287 UnknownData6 "TRANSPORT_CANDIDATE: normal-addressing ISO-TP. PSA-RE bits 7.7-7.0. ";
CM_ SG_ 287 ConsecutiveData6 "TRANSPORT_CANDIDATE: normal-addressing ISO-TP. PSA-RE bits 7.7-7.0. ";
CM_ SG_ 287 SingleData6 "TRANSPORT_CANDIDATE: normal-addressing ISO-TP. PSA-RE bits 7.7-7.0. ";
CM_ SG_ 287 FlowPadding3 "TRANSPORT_CANDIDATE: normal-addressing ISO-TP. PSA-RE bits 6.7-6.0. ";
CM_ SG_ 287 FirstData4 "TRANSPORT_CANDIDATE: normal-addressing ISO-TP. PSA-RE bits 6.7-6.0. ";
CM_ SG_ 287 UnknownData5 "TRANSPORT_CANDIDATE: normal-addressing ISO-TP. PSA-RE bits 6.7-6.0. ";
CM_ SG_ 287 ConsecutiveData5 "TRANSPORT_CANDIDATE: normal-addressing ISO-TP. PSA-RE bits 6.7-6.0. ";
CM_ SG_ 287 SingleData5 "TRANSPORT_CANDIDATE: normal-addressing ISO-TP. PSA-RE bits 6.7-6.0. ";
CM_ SG_ 287 FlowPadding2 "TRANSPORT_CANDIDATE: normal-addressing ISO-TP. PSA-RE bits 5.7-5.0. ";
CM_ SG_ 287 FirstData3 "TRANSPORT_CANDIDATE: normal-addressing ISO-TP. PSA-RE bits 5.7-5.0. ";
CM_ SG_ 287 UnknownData4 "TRANSPORT_CANDIDATE: normal-addressing ISO-TP. PSA-RE bits 5.7-5.0. ";
CM_ SG_ 287 ConsecutiveData4 "TRANSPORT_CANDIDATE: normal-addressing ISO-TP. PSA-RE bits 5.7-5.0. ";
CM_ SG_ 287 SingleData4 "TRANSPORT_CANDIDATE: normal-addressing ISO-TP. PSA-RE bits 5.7-5.0. ";
CM_ SG_ 287 FlowPadding1 "TRANSPORT_CANDIDATE: normal-addressing ISO-TP. PSA-RE bits 4.7-4.0. ";
CM_ SG_ 287 FirstData2 "TRANSPORT_CANDIDATE: normal-addressing ISO-TP. PSA-RE bits 4.7-4.0. ";
CM_ SG_ 287 UnknownData3 "TRANSPORT_CANDIDATE: normal-addressing ISO-TP. PSA-RE bits 4.7-4.0. ";
CM_ SG_ 287 ConsecutiveData3 "TRANSPORT_CANDIDATE: normal-addressing ISO-TP. PSA-RE bits 4.7-4.0. ";
CM_ SG_ 287 SingleData3 "TRANSPORT_CANDIDATE: normal-addressing ISO-TP. PSA-RE bits 4.7-4.0. ";
CM_ SG_ 287 FirstData1 "TRANSPORT_CANDIDATE: normal-addressing ISO-TP. PSA-RE bits 3.7-3.0. ";
CM_ SG_ 287 UnknownData2 "TRANSPORT_CANDIDATE: normal-addressing ISO-TP. PSA-RE bits 3.7-3.0. ";
CM_ SG_ 287 ConsecutiveData2 "TRANSPORT_CANDIDATE: normal-addressing ISO-TP. PSA-RE bits 3.7-3.0. ";
CM_ SG_ 287 SingleData2 "TRANSPORT_CANDIDATE: normal-addressing ISO-TP. PSA-RE bits 3.7-3.0. ";
CM_ SG_ 287 SeparationTimeRaw "TRANSPORT_CANDIDATE: normal-addressing ISO-TP. PSA-RE bits 3.7-3.0. Raw STmin code; 0xF1..0xF9 are not milliseconds.";
CM_ SG_ 287 UnknownData1 "TRANSPORT_CANDIDATE: normal-addressing ISO-TP. PSA-RE bits 2.7-2.0. ";
CM_ SG_ 287 ConsecutiveData1 "TRANSPORT_CANDIDATE: normal-addressing ISO-TP. PSA-RE bits 2.7-2.0. ";
CM_ SG_ 287 SingleData1 "TRANSPORT_CANDIDATE: normal-addressing ISO-TP. PSA-RE bits 2.7-2.0. ";
CM_ SG_ 287 BlockSize "TRANSPORT_CANDIDATE: normal-addressing ISO-TP. PSA-RE bits 2.7-2.0. ";
CM_ SG_ 287 UnknownPciLow "TRANSPORT_CANDIDATE: normal-addressing ISO-TP. PSA-RE bits 1.3-1.0. ";
CM_ SG_ 287 FlowStatus "TRANSPORT_CANDIDATE: normal-addressing ISO-TP. PSA-RE bits 1.3-1.0. ";
CM_ SG_ 287 ConsecutiveSequence "TRANSPORT_CANDIDATE: normal-addressing ISO-TP. PSA-RE bits 1.3-1.0. ";
CM_ SG_ 287 FirstFrameLength "TRANSPORT_CANDIDATE: normal-addressing ISO-TP. PSA-RE bits 1.3-2.0. 12-bit declared PDU length; not a reassembled value.";
CM_ SG_ 287 SingleFrameLength "TRANSPORT_CANDIDATE: normal-addressing ISO-TP. PSA-RE bits 1.3-1.0. Declared data length; not a validity check.";
CM_ SG_ 287 IsoTpFrameType "TRANSPORT_CANDIDATE: normal-addressing ISO-TP. PSA-RE bits 1.7-1.4. PCI high nibble; normal addressing candidate.";
CM_ BO_ 288 "DATABASE_CANDIDATE: physical interpretation unverified; capture/layout evidence reported separately. INFO-DIV CAN, 125000 bit/s; CAN ID 0x120. PSA-RE title: VEHICLE_ALERT_LOG. Vehicle alert log access frame, sent by the body computer (BSI) when the alert log is accessed. Source: https://github.com/prototux/PSA-RE/blob/67f7581e7622410efdbb29c7eda3b86982b9b450/buses/AEE2010.full/LS.INFO-DIV/120.yml. Source sender alternatives: ICSV,BSI; physical TX/gateway forwarding not verified. Observed 28 frames in info_start_jizda.csv; DLCs [8]. Unresolved alternative source layouts preserved in source JSON. ";
CM_ SG_ 288 AlertLogStatus "DATABASE_CANDIDATE: physical interpretation unverified; capture/layout evidence reported separately. PSA-RE bits 2.7-8.0. Status of the alerts to display in the alert log Source text/byte field exposed as raw integer; no string decoding. Upstream default raw=0 (not necessarily valid data).";
CM_ SG_ 288 Unused1 "DATABASE_CANDIDATE: physical interpretation unverified; capture/layout evidence reported separately. PSA-RE bits 1.1-1.0. ";
CM_ SG_ 288 AlertLogMenuAvailability "DATABASE_CANDIDATE: physical interpretation unverified; capture/layout evidence reported separately. PSA-RE bits 1.3-1.2. Accessibility of the alert-log menu Upstream default raw=0 (not necessarily valid data).";
CM_ SG_ 288 TotalDataBlockCount "DATABASE_CANDIDATE: physical interpretation unverified; capture/layout evidence reported separately. PSA-RE bits 1.5-1.4. Total number of VEHICLE_ALERT_LOG data blocks needed for the alert log function Upstream default raw=0 (not necessarily valid data).";
CM_ SG_ 288 ActiveDataBlockNumber "DATABASE_CANDIDATE: physical interpretation unverified; capture/layout evidence reported separately. PSA-RE bits 1.7-1.6. Identification of the VEHICLE_ALERT_LOG data block Upstream default raw=0 (not necessarily valid data).";
CM_ BO_ 289 "DATABASE_CANDIDATE: physical interpretation unverified; capture/layout evidence reported separately. INFO-DIV CAN, 125000 bit/s; CAN ID 0x121. PSA-RE title: GEARBOX_RESTART_DATA. Rear-gear preparation-in-progress flag, relayed by the body computer. Source: https://github.com/prototux/PSA-RE/blob/67f7581e7622410efdbb29c7eda3b86982b9b450/buses/AEE2010.full/LS.INFO-DIV/121.yml. Source sender alternatives: BSI; physical TX/gateway forwarding not verified. ";
CM_ SG_ 289 Unused1 "DATABASE_CANDIDATE: physical interpretation unverified; capture/layout evidence reported separately. PSA-RE bits 1.5-1.0. ";
CM_ SG_ 289 StopStartPreparationStatus "DATABASE_CANDIDATE: physical interpretation unverified; capture/layout evidence reported separately. PSA-RE bits 1.7-1.6. Stop-start restart preparation status Upstream default raw=1 (not necessarily valid data).";
CM_ BO_ 290 "DATABASE_CANDIDATE: physical interpretation unverified; capture/layout evidence reported separately. INFO-DIV CAN, 125000 bit/s; CAN ID 0x122. PSA-RE title: MULTIPLEXED_BUTTONS_STATUS_2. Multiplexed push-button panel status: individual button states, scroll-wheel counters and ESP button. Source: https://github.com/prototux/PSA-RE/blob/67f7581e7622410efdbb29c7eda3b86982b9b450/buses/AEE2010.full/LS.INFO-DIV/122.yml. Source sender alternatives: CMB,CRT,EMF,FMUX,ICSV; physical TX/gateway forwarding not verified. Observed 2945 frames in info_apka.csv,info_buzeni_obc.csv,info_charging.csv,info_standby.csv,info_start_jizda.csv,infocan.csv; DLCs [8]. ";
CM_ SG_ 290 Knob2StepCounter "DATABASE_CANDIDATE: physical interpretation unverified; capture/layout evidence reported separately. PSA-RE bits 8.7-8.0. Knob 2 step counter Upstream default raw=0 (not necessarily valid data).";
CM_ SG_ 290 Knob1StepCounter "DATABASE_CANDIDATE: physical interpretation unverified; capture/layout evidence reported separately. PSA-RE bits 7.7-7.0. Knob 1 step counter Upstream default raw=0 (not necessarily valid data).";
CM_ SG_ 290 Knob2SyncRequest "DATABASE_CANDIDATE: physical interpretation unverified; capture/layout evidence reported separately. PSA-RE bits 6.0. Synchronization request for knob 2 on the multiplexed front panel Upstream default raw=0 (not necessarily valid data).";
CM_ SG_ 290 Knob1SyncRequest "DATABASE_CANDIDATE: physical interpretation unverified; capture/layout evidence reported separately. PSA-RE bits 6.1. Synchronization request for knob 1 on the multiplexed front panel Upstream default raw=0 (not necessarily valid data).";
CM_ SG_ 290 FrontPanelBpKeyPressed "DATABASE_CANDIDATE: physical interpretation unverified; capture/layout evidence reported separately. PSA-RE bits 6.2. BP key of the multiplexed front panel pressed Upstream default raw=0 (not necessarily valid data).";
CM_ SG_ 290 FrontPanelKey45Pressed "DATABASE_CANDIDATE: physical interpretation unverified; capture/layout evidence reported separately. PSA-RE bits 6.3. Key 45 of the multiplexed front panel pressed Upstream default raw=0 (not necessarily valid data).";
CM_ SG_ 290 PanelKey44Pressed "DATABASE_CANDIDATE: physical interpretation unverified; capture/layout evidence reported separately. PSA-RE bits 6.4. Press status of key 44 on the multiplexed front panel Upstream default raw=0 (not necessarily valid data).";
CM_ SG_ 290 PanelKey43Pressed "DATABASE_CANDIDATE: physical interpretation unverified; capture/layout evidence reported separately. PSA-RE bits 6.5. Press status of key 43 on the multiplexed front panel Upstream default raw=0 (not necessarily valid data).";
CM_ SG_ 290 PanelKey42Pressed "DATABASE_CANDIDATE: physical interpretation unverified; capture/layout evidence reported separately. PSA-RE bits 6.6. Press status of key 42 on the multiplexed front panel Upstream default raw=0 (not necessarily valid data).";
CM_ SG_ 290 PanelKey41Pressed "DATABASE_CANDIDATE: physical interpretation unverified; capture/layout evidence reported separately. PSA-RE bits 6.7. Press status of key 41 on the multiplexed front panel Upstream default raw=0 (not necessarily valid data).";
CM_ SG_ 290 PanelKey40Pressed "DATABASE_CANDIDATE: physical interpretation unverified; capture/layout evidence reported separately. PSA-RE bits 5.0. Press status of key 40 on the multiplexed front panel Upstream default raw=0 (not necessarily valid data).";
CM_ SG_ 290 PanelKey39Pressed "DATABASE_CANDIDATE: physical interpretation unverified; capture/layout evidence reported separately. PSA-RE bits 5.1. Press status of key 39 on the multiplexed front panel Upstream default raw=0 (not necessarily valid data).";
CM_ SG_ 290 PanelKey38Pressed "DATABASE_CANDIDATE: physical interpretation unverified; capture/layout evidence reported separately. PSA-RE bits 5.2. Press status of key 38 on the multiplexed front panel Upstream default raw=0 (not necessarily valid data).";
CM_ SG_ 290 PanelKey37Pressed "DATABASE_CANDIDATE: physical interpretation unverified; capture/layout evidence reported separately. PSA-RE bits 5.3. Press status of key 37 on the multiplexed front panel Upstream default raw=0 (not necessarily valid data).";
CM_ SG_ 290 PanelKey36Pressed "DATABASE_CANDIDATE: physical interpretation unverified; capture/layout evidence reported separately. PSA-RE bits 5.4. Press status of key 36 on the multiplexed front panel Upstream default raw=0 (not necessarily valid data).";
CM_ SG_ 290 PanelKey35Pressed "DATABASE_CANDIDATE: physical interpretation unverified; capture/layout evidence reported separately. PSA-RE bits 5.5. Press status of key 35 on the multiplexed front panel Upstream default raw=0 (not necessarily valid data).";
CM_ SG_ 290 PanelKey34Pressed "DATABASE_CANDIDATE: physical interpretation unverified; capture/layout evidence reported separately. PSA-RE bits 5.6. Press status of key 34 on the multiplexed front panel Upstream default raw=0 (not necessarily valid data).";
CM_ SG_ 290 PanelKey33Pressed "DATABASE_CANDIDATE: physical interpretation unverified; capture/layout evidence reported separately. PSA-RE bits 5.7. Press status of key 33 on the multiplexed front panel Upstream default raw=0 (not necessarily valid data).";
CM_ SG_ 290 PanelKey32Pressed "DATABASE_CANDIDATE: physical interpretation unverified; capture/layout evidence reported separately. PSA-RE bits 4.0. Press status of key 32 on the multiplexed front panel Upstream default raw=0 (not necessarily valid data).";
CM_ SG_ 290 PanelKey31Pressed "DATABASE_CANDIDATE: physical interpretation unverified; capture/layout evidence reported separately. PSA-RE bits 4.1. Press status of key 31 on the multiplexed front panel Upstream default raw=0 (not necessarily valid data).";
CM_ SG_ 290 PanelKey30Pressed "DATABASE_CANDIDATE: physical interpretation unverified; capture/layout evidence reported separately. PSA-RE bits 4.2. Press status of key 30 on the multiplexed front panel Upstream default raw=0 (not necessarily valid data).";
CM_ SG_ 290 PanelKey29Pressed "DATABASE_CANDIDATE: physical interpretation unverified; capture/layout evidence reported separately. PSA-RE bits 4.3. Press status of key 29 on the multiplexed front panel Upstream default raw=0 (not necessarily valid data).";
CM_ SG_ 290 PanelKey28Pressed "DATABASE_CANDIDATE: physical interpretation unverified; capture/layout evidence reported separately. PSA-RE bits 4.4. Press status of key 28 on the multiplexed front panel Upstream default raw=0 (not necessarily valid data).";
CM_ SG_ 290 PanelKey27Pressed "DATABASE_CANDIDATE: physical interpretation unverified; capture/layout evidence reported separately. PSA-RE bits 4.5. Press status of key 27 on the multiplexed front panel Upstream default raw=0 (not necessarily valid data).";
CM_ SG_ 290 PanelKey26Pressed "DATABASE_CANDIDATE: physical interpretation unverified; capture/layout evidence reported separately. PSA-RE bits 4.6. Press status of key 26 on the multiplexed front panel Upstream default raw=0 (not necessarily valid data).";
CM_ SG_ 290 PanelKey25Pressed "DATABASE_CANDIDATE: physical interpretation unverified; capture/layout evidence reported separately. PSA-RE bits 4.7. Press status of key 25 on the multiplexed front panel Upstream default raw=0 (not necessarily valid data).";
CM_ SG_ 290 PanelKey24Pressed "DATABASE_CANDIDATE: physical interpretation unverified; capture/layout evidence reported separately. PSA-RE bits 3.0. Press status of key 24 on the multiplexed front panel Upstream default raw=0 (not necessarily valid data).";
CM_ SG_ 290 PanelKey23Pressed "DATABASE_CANDIDATE: physical interpretation unverified; capture/layout evidence reported separately. PSA-RE bits 3.1. Press status of key 23 on the multiplexed front panel Upstream default raw=0 (not necessarily valid data).";
CM_ SG_ 290 PanelKey22Pressed "DATABASE_CANDIDATE: physical interpretation unverified; capture/layout evidence reported separately. PSA-RE bits 3.2. Press status of key 22 on the multiplexed front panel Upstream default raw=0 (not necessarily valid data).";
CM_ SG_ 290 PanelKey21Pressed "DATABASE_CANDIDATE: physical interpretation unverified; capture/layout evidence reported separately. PSA-RE bits 3.3. Press status of key 21 on the multiplexed front panel Upstream default raw=0 (not necessarily valid data).";
CM_ SG_ 290 PanelKey20Pressed "DATABASE_CANDIDATE: physical interpretation unverified; capture/layout evidence reported separately. PSA-RE bits 3.4. Press status of key 20 on the multiplexed front panel Upstream default raw=0 (not necessarily valid data).";
CM_ SG_ 290 PanelKey19Pressed "DATABASE_CANDIDATE: physical interpretation unverified; capture/layout evidence reported separately. PSA-RE bits 3.5. Press status of key 19 on the multiplexed front panel Upstream default raw=0 (not necessarily valid data).";
CM_ SG_ 290 PanelKey18Pressed "DATABASE_CANDIDATE: physical interpretation unverified; capture/layout evidence reported separately. PSA-RE bits 3.6. Press status of key 18 on the multiplexed front panel Upstream default raw=0 (not necessarily valid data).";
CM_ SG_ 290 PanelKey17Pressed "DATABASE_CANDIDATE: physical interpretation unverified; capture/layout evidence reported separately. PSA-RE bits 3.7. Press status of key 17 on the multiplexed front panel Upstream default raw=0 (not necessarily valid data).";
CM_ SG_ 290 PanelKey16Pressed "DATABASE_CANDIDATE: physical interpretation unverified; capture/layout evidence reported separately. PSA-RE bits 2.0. Press status of key 16 on the multiplexed front panel Upstream default raw=0 (not necessarily valid data).";
CM_ SG_ 290 PanelKey15Pressed "DATABASE_CANDIDATE: physical interpretation unverified; capture/layout evidence reported separately. PSA-RE bits 2.1. Press status of key 15 on the multiplexed front panel Upstream default raw=0 (not necessarily valid data).";
CM_ SG_ 290 PanelKey14Pressed "DATABASE_CANDIDATE: physical interpretation unverified; capture/layout evidence reported separately. PSA-RE bits 2.2. Press status of key 14 on the multiplexed front panel Upstream default raw=0 (not necessarily valid data).";
CM_ SG_ 290 PanelKey13Pressed "DATABASE_CANDIDATE: physical interpretation unverified; capture/layout evidence reported separately. PSA-RE bits 2.3. Press status of key 13 on the multiplexed front panel Upstream default raw=0 (not necessarily valid data).";
CM_ SG_ 290 PanelKey12Pressed "DATABASE_CANDIDATE: physical interpretation unverified; capture/layout evidence reported separately. PSA-RE bits 2.4. Press status of key 12 on the multiplexed front panel Upstream default raw=0 (not necessarily valid data).";
CM_ SG_ 290 PanelKey11Pressed "DATABASE_CANDIDATE: physical interpretation unverified; capture/layout evidence reported separately. PSA-RE bits 2.5. Press status of key 11 on the multiplexed front panel Upstream default raw=0 (not necessarily valid data).";
CM_ SG_ 290 PanelKey10Pressed "DATABASE_CANDIDATE: physical interpretation unverified; capture/layout evidence reported separately. PSA-RE bits 2.6. Press status of key 10 on the multiplexed front panel Upstream default raw=0 (not necessarily valid data).";
CM_ SG_ 290 PanelKey9Pressed "DATABASE_CANDIDATE: physical interpretation unverified; capture/layout evidence reported separately. PSA-RE bits 2.7. Press status of key 9 on the multiplexed front panel Upstream default raw=0 (not necessarily valid data).";
CM_ SG_ 290 PanelKey8Pressed "DATABASE_CANDIDATE: physical interpretation unverified; capture/layout evidence reported separately. PSA-RE bits 1.0. Press status of key 8 on the multiplexed front panel Upstream default raw=0 (not necessarily valid data).";
CM_ SG_ 290 PanelKey7Pressed "DATABASE_CANDIDATE: physical interpretation unverified; capture/layout evidence reported separately. PSA-RE bits 1.1. Press status of key 7 on the multiplexed front panel Upstream default raw=0 (not necessarily valid data).";
CM_ SG_ 290 PanelKey6Pressed "DATABASE_CANDIDATE: physical interpretation unverified; capture/layout evidence reported separately. PSA-RE bits 1.2. Press status of key 6 on the multiplexed front panel Upstream default raw=0 (not necessarily valid data).";
CM_ SG_ 290 PanelKey5Pressed "DATABASE_CANDIDATE: physical interpretation unverified; capture/layout evidence reported separately. PSA-RE bits 1.3. Press status of key 5 on the multiplexed front panel Upstream default raw=0 (not necessarily valid data).";
CM_ SG_ 290 PanelKey4Pressed "DATABASE_CANDIDATE: physical interpretation unverified; capture/layout evidence reported separately. PSA-RE bits 1.4. Press status of key 4 on the multiplexed front panel Upstream default raw=0 (not necessarily valid data).";
CM_ SG_ 290 PanelKey3Pressed "DATABASE_CANDIDATE: physical interpretation unverified; capture/layout evidence reported separately. PSA-RE bits 1.5. Press status of key 3 on the multiplexed front panel Upstream default raw=0 (not necessarily valid data).";
CM_ SG_ 290 PanelKey2Pressed "DATABASE_CANDIDATE: physical interpretation unverified; capture/layout evidence reported separately. PSA-RE bits 1.6. Press status of key 2 on the multiplexed front panel Upstream default raw=0 (not necessarily valid data).";
CM_ SG_ 290 PanelKey1Pressed "DATABASE_CANDIDATE: physical interpretation unverified; capture/layout evidence reported separately. PSA-RE bits 1.7. Press status of key 1 on the multiplexed front panel Upstream default raw=0 (not necessarily valid data).";
CM_ BO_ 291 "DATABASE_CANDIDATE: physical interpretation unverified; capture/layout evidence reported separately. INFO-DIV CAN, 125000 bit/s; CAN ID 0x123. PSA-RE title: KML_CALL_STATUS. Family of frames sharing this ID: the content depends on CALL_OPERATOR_PHONE_MODE_2 Source: https://github.com/prototux/PSA-RE/blob/67f7581e7622410efdbb29c7eda3b86982b9b450/buses/AEE2010.full/LS.INFO-DIV/123.yml. Source sender alternatives: RAD,ICSV; physical TX/gateway forwarding not verified. WIRE ISO-TP ONLY: normal addressing candidate, maximum Classical CAN DLC 8; actual DLC may be shorter. Data includes padding. No reassembly, text, DID or application-layer decoding. Original application layouts are preserved in source JSON; do not decode them at wire offsets. Unresolved alternative source layouts preserved in source JSON. ";
CM_ SG_ 291 FlowPadding5 "TRANSPORT_CANDIDATE: normal-addressing ISO-TP. PSA-RE bits 8.7-8.0. ";
CM_ SG_ 291 FirstData6 "TRANSPORT_CANDIDATE: normal-addressing ISO-TP. PSA-RE bits 8.7-8.0. ";
CM_ SG_ 291 UnknownData7 "TRANSPORT_CANDIDATE: normal-addressing ISO-TP. PSA-RE bits 8.7-8.0. ";
CM_ SG_ 291 ConsecutiveData7 "TRANSPORT_CANDIDATE: normal-addressing ISO-TP. PSA-RE bits 8.7-8.0. ";
CM_ SG_ 291 SingleData7 "TRANSPORT_CANDIDATE: normal-addressing ISO-TP. PSA-RE bits 8.7-8.0. ";
CM_ SG_ 291 FlowPadding4 "TRANSPORT_CANDIDATE: normal-addressing ISO-TP. PSA-RE bits 7.7-7.0. ";
CM_ SG_ 291 FirstData5 "TRANSPORT_CANDIDATE: normal-addressing ISO-TP. PSA-RE bits 7.7-7.0. ";
CM_ SG_ 291 UnknownData6 "TRANSPORT_CANDIDATE: normal-addressing ISO-TP. PSA-RE bits 7.7-7.0. ";
CM_ SG_ 291 ConsecutiveData6 "TRANSPORT_CANDIDATE: normal-addressing ISO-TP. PSA-RE bits 7.7-7.0. ";
CM_ SG_ 291 SingleData6 "TRANSPORT_CANDIDATE: normal-addressing ISO-TP. PSA-RE bits 7.7-7.0. ";
CM_ SG_ 291 FlowPadding3 "TRANSPORT_CANDIDATE: normal-addressing ISO-TP. PSA-RE bits 6.7-6.0. ";
CM_ SG_ 291 FirstData4 "TRANSPORT_CANDIDATE: normal-addressing ISO-TP. PSA-RE bits 6.7-6.0. ";
CM_ SG_ 291 UnknownData5 "TRANSPORT_CANDIDATE: normal-addressing ISO-TP. PSA-RE bits 6.7-6.0. ";
CM_ SG_ 291 ConsecutiveData5 "TRANSPORT_CANDIDATE: normal-addressing ISO-TP. PSA-RE bits 6.7-6.0. ";
CM_ SG_ 291 SingleData5 "TRANSPORT_CANDIDATE: normal-addressing ISO-TP. PSA-RE bits 6.7-6.0. ";
CM_ SG_ 291 FlowPadding2 "TRANSPORT_CANDIDATE: normal-addressing ISO-TP. PSA-RE bits 5.7-5.0. ";
CM_ SG_ 291 FirstData3 "TRANSPORT_CANDIDATE: normal-addressing ISO-TP. PSA-RE bits 5.7-5.0. ";
CM_ SG_ 291 UnknownData4 "TRANSPORT_CANDIDATE: normal-addressing ISO-TP. PSA-RE bits 5.7-5.0. ";
CM_ SG_ 291 ConsecutiveData4 "TRANSPORT_CANDIDATE: normal-addressing ISO-TP. PSA-RE bits 5.7-5.0. ";
CM_ SG_ 291 SingleData4 "TRANSPORT_CANDIDATE: normal-addressing ISO-TP. PSA-RE bits 5.7-5.0. ";
CM_ SG_ 291 FlowPadding1 "TRANSPORT_CANDIDATE: normal-addressing ISO-TP. PSA-RE bits 4.7-4.0. ";
CM_ SG_ 291 FirstData2 "TRANSPORT_CANDIDATE: normal-addressing ISO-TP. PSA-RE bits 4.7-4.0. ";
CM_ SG_ 291 UnknownData3 "TRANSPORT_CANDIDATE: normal-addressing ISO-TP. PSA-RE bits 4.7-4.0. ";
CM_ SG_ 291 ConsecutiveData3 "TRANSPORT_CANDIDATE: normal-addressing ISO-TP. PSA-RE bits 4.7-4.0. ";
CM_ SG_ 291 SingleData3 "TRANSPORT_CANDIDATE: normal-addressing ISO-TP. PSA-RE bits 4.7-4.0. ";
CM_ SG_ 291 FirstData1 "TRANSPORT_CANDIDATE: normal-addressing ISO-TP. PSA-RE bits 3.7-3.0. ";
CM_ SG_ 291 UnknownData2 "TRANSPORT_CANDIDATE: normal-addressing ISO-TP. PSA-RE bits 3.7-3.0. ";
CM_ SG_ 291 ConsecutiveData2 "TRANSPORT_CANDIDATE: normal-addressing ISO-TP. PSA-RE bits 3.7-3.0. ";
CM_ SG_ 291 SingleData2 "TRANSPORT_CANDIDATE: normal-addressing ISO-TP. PSA-RE bits 3.7-3.0. ";
CM_ SG_ 291 SeparationTimeRaw "TRANSPORT_CANDIDATE: normal-addressing ISO-TP. PSA-RE bits 3.7-3.0. Raw STmin code; 0xF1..0xF9 are not milliseconds.";
CM_ SG_ 291 UnknownData1 "TRANSPORT_CANDIDATE: normal-addressing ISO-TP. PSA-RE bits 2.7-2.0. ";
CM_ SG_ 291 ConsecutiveData1 "TRANSPORT_CANDIDATE: normal-addressing ISO-TP. PSA-RE bits 2.7-2.0. ";
CM_ SG_ 291 SingleData1 "TRANSPORT_CANDIDATE: normal-addressing ISO-TP. PSA-RE bits 2.7-2.0. ";
CM_ SG_ 291 BlockSize "TRANSPORT_CANDIDATE: normal-addressing ISO-TP. PSA-RE bits 2.7-2.0. ";
CM_ SG_ 291 UnknownPciLow "TRANSPORT_CANDIDATE: normal-addressing ISO-TP. PSA-RE bits 1.3-1.0. ";
CM_ SG_ 291 FlowStatus "TRANSPORT_CANDIDATE: normal-addressing ISO-TP. PSA-RE bits 1.3-1.0. ";
CM_ SG_ 291 ConsecutiveSequence "TRANSPORT_CANDIDATE: normal-addressing ISO-TP. PSA-RE bits 1.3-1.0. ";
CM_ SG_ 291 FirstFrameLength "TRANSPORT_CANDIDATE: normal-addressing ISO-TP. PSA-RE bits 1.3-2.0. 12-bit declared PDU length; not a reassembled value.";
CM_ SG_ 291 SingleFrameLength "TRANSPORT_CANDIDATE: normal-addressing ISO-TP. PSA-RE bits 1.3-1.0. Declared data length; not a validity check.";
CM_ SG_ 291 IsoTpFrameType "TRANSPORT_CANDIDATE: normal-addressing ISO-TP. PSA-RE bits 1.7-1.4. PCI high nibble; normal addressing candidate.";
CM_ BO_ 293 "DATABASE_CANDIDATE: physical interpretation unverified; capture/layout evidence reported separately. INFO-DIV CAN, 125000 bit/s; CAN ID 0x125. PSA-RE title: RADIO. Family of frames sharing this ID: the content depends on SENT_DIRECTORY_TYPE Source: https://github.com/prototux/PSA-RE/blob/67f7581e7622410efdbb29c7eda3b86982b9b450/buses/AEE2010.full/LS.INFO-DIV/125.yml. Source sender alternatives: RAD,ICSV; physical TX/gateway forwarding not verified. WIRE ISO-TP ONLY: normal addressing candidate, maximum Classical CAN DLC 8; actual DLC may be shorter. Data includes padding. No reassembly, text, DID or application-layer decoding. Original application layouts are preserved in source JSON; do not decode them at wire offsets. Unresolved alternative source layouts preserved in source JSON. ";
CM_ SG_ 293 FlowPadding5 "TRANSPORT_CANDIDATE: normal-addressing ISO-TP. PSA-RE bits 8.7-8.0. ";
CM_ SG_ 293 FirstData6 "TRANSPORT_CANDIDATE: normal-addressing ISO-TP. PSA-RE bits 8.7-8.0. ";
CM_ SG_ 293 UnknownData7 "TRANSPORT_CANDIDATE: normal-addressing ISO-TP. PSA-RE bits 8.7-8.0. ";
CM_ SG_ 293 ConsecutiveData7 "TRANSPORT_CANDIDATE: normal-addressing ISO-TP. PSA-RE bits 8.7-8.0. ";
CM_ SG_ 293 SingleData7 "TRANSPORT_CANDIDATE: normal-addressing ISO-TP. PSA-RE bits 8.7-8.0. ";
CM_ SG_ 293 FlowPadding4 "TRANSPORT_CANDIDATE: normal-addressing ISO-TP. PSA-RE bits 7.7-7.0. ";
CM_ SG_ 293 FirstData5 "TRANSPORT_CANDIDATE: normal-addressing ISO-TP. PSA-RE bits 7.7-7.0. ";
CM_ SG_ 293 UnknownData6 "TRANSPORT_CANDIDATE: normal-addressing ISO-TP. PSA-RE bits 7.7-7.0. ";
CM_ SG_ 293 ConsecutiveData6 "TRANSPORT_CANDIDATE: normal-addressing ISO-TP. PSA-RE bits 7.7-7.0. ";
CM_ SG_ 293 SingleData6 "TRANSPORT_CANDIDATE: normal-addressing ISO-TP. PSA-RE bits 7.7-7.0. ";
CM_ SG_ 293 FlowPadding3 "TRANSPORT_CANDIDATE: normal-addressing ISO-TP. PSA-RE bits 6.7-6.0. ";
CM_ SG_ 293 FirstData4 "TRANSPORT_CANDIDATE: normal-addressing ISO-TP. PSA-RE bits 6.7-6.0. ";
CM_ SG_ 293 UnknownData5 "TRANSPORT_CANDIDATE: normal-addressing ISO-TP. PSA-RE bits 6.7-6.0. ";
CM_ SG_ 293 ConsecutiveData5 "TRANSPORT_CANDIDATE: normal-addressing ISO-TP. PSA-RE bits 6.7-6.0. ";
CM_ SG_ 293 SingleData5 "TRANSPORT_CANDIDATE: normal-addressing ISO-TP. PSA-RE bits 6.7-6.0. ";
CM_ SG_ 293 FlowPadding2 "TRANSPORT_CANDIDATE: normal-addressing ISO-TP. PSA-RE bits 5.7-5.0. ";
CM_ SG_ 293 FirstData3 "TRANSPORT_CANDIDATE: normal-addressing ISO-TP. PSA-RE bits 5.7-5.0. ";
CM_ SG_ 293 UnknownData4 "TRANSPORT_CANDIDATE: normal-addressing ISO-TP. PSA-RE bits 5.7-5.0. ";
CM_ SG_ 293 ConsecutiveData4 "TRANSPORT_CANDIDATE: normal-addressing ISO-TP. PSA-RE bits 5.7-5.0. ";
CM_ SG_ 293 SingleData4 "TRANSPORT_CANDIDATE: normal-addressing ISO-TP. PSA-RE bits 5.7-5.0. ";
CM_ SG_ 293 FlowPadding1 "TRANSPORT_CANDIDATE: normal-addressing ISO-TP. PSA-RE bits 4.7-4.0. ";
CM_ SG_ 293 FirstData2 "TRANSPORT_CANDIDATE: normal-addressing ISO-TP. PSA-RE bits 4.7-4.0. ";
CM_ SG_ 293 UnknownData3 "TRANSPORT_CANDIDATE: normal-addressing ISO-TP. PSA-RE bits 4.7-4.0. ";
CM_ SG_ 293 ConsecutiveData3 "TRANSPORT_CANDIDATE: normal-addressing ISO-TP. PSA-RE bits 4.7-4.0. ";
CM_ SG_ 293 SingleData3 "TRANSPORT_CANDIDATE: normal-addressing ISO-TP. PSA-RE bits 4.7-4.0. ";
CM_ SG_ 293 FirstData1 "TRANSPORT_CANDIDATE: normal-addressing ISO-TP. PSA-RE bits 3.7-3.0. ";
CM_ SG_ 293 UnknownData2 "TRANSPORT_CANDIDATE: normal-addressing ISO-TP. PSA-RE bits 3.7-3.0. ";
CM_ SG_ 293 ConsecutiveData2 "TRANSPORT_CANDIDATE: normal-addressing ISO-TP. PSA-RE bits 3.7-3.0. ";
CM_ SG_ 293 SingleData2 "TRANSPORT_CANDIDATE: normal-addressing ISO-TP. PSA-RE bits 3.7-3.0. ";
CM_ SG_ 293 SeparationTimeRaw "TRANSPORT_CANDIDATE: normal-addressing ISO-TP. PSA-RE bits 3.7-3.0. Raw STmin code; 0xF1..0xF9 are not milliseconds.";
CM_ SG_ 293 UnknownData1 "TRANSPORT_CANDIDATE: normal-addressing ISO-TP. PSA-RE bits 2.7-2.0. ";
CM_ SG_ 293 ConsecutiveData1 "TRANSPORT_CANDIDATE: normal-addressing ISO-TP. PSA-RE bits 2.7-2.0. ";
CM_ SG_ 293 SingleData1 "TRANSPORT_CANDIDATE: normal-addressing ISO-TP. PSA-RE bits 2.7-2.0. ";
CM_ SG_ 293 BlockSize "TRANSPORT_CANDIDATE: normal-addressing ISO-TP. PSA-RE bits 2.7-2.0. ";
CM_ SG_ 293 UnknownPciLow "TRANSPORT_CANDIDATE: normal-addressing ISO-TP. PSA-RE bits 1.3-1.0. ";
CM_ SG_ 293 FlowStatus "TRANSPORT_CANDIDATE: normal-addressing ISO-TP. PSA-RE bits 1.3-1.0. ";
CM_ SG_ 293 ConsecutiveSequence "TRANSPORT_CANDIDATE: normal-addressing ISO-TP. PSA-RE bits 1.3-1.0. ";
CM_ SG_ 293 FirstFrameLength "TRANSPORT_CANDIDATE: normal-addressing ISO-TP. PSA-RE bits 1.3-2.0. 12-bit declared PDU length; not a reassembled value.";
CM_ SG_ 293 SingleFrameLength "TRANSPORT_CANDIDATE: normal-addressing ISO-TP. PSA-RE bits 1.3-1.0. Declared data length; not a validity check.";
CM_ SG_ 293 IsoTpFrameType "TRANSPORT_CANDIDATE: normal-addressing ISO-TP. PSA-RE bits 1.7-1.4. PCI high nibble; normal addressing candidate.";
CM_ BO_ 294 "DATABASE_CANDIDATE: physical interpretation unverified; capture/layout evidence reported separately. INFO-DIV CAN, 125000 bit/s; CAN ID 0x126. PSA-RE title: PARKING_AID_COMMAND. Parking aid commands sent by the BSI on change: sound/visual inhibition requests, parking space measurement activation and cluster display request. Source: https://github.com/prototux/PSA-RE/blob/67f7581e7622410efdbb29c7eda3b86982b9b450/buses/AEE2010.full/LS.INFO-DIV/126.yml. Source sender alternatives: BSI; physical TX/gateway forwarding not verified. Unresolved alternative source layouts preserved in source JSON. ";
CM_ SG_ 294 Unused2 "DATABASE_CANDIDATE: physical interpretation unverified; capture/layout evidence reported separately. PSA-RE bits 3.7-3.0. ";
CM_ SG_ 294 Unused1 "DATABASE_CANDIDATE: physical interpretation unverified; capture/layout evidence reported separately. PSA-RE bits 2.1-2.0. ";
CM_ SG_ 294 SmallSpareWheelDetected "DATABASE_CANDIDATE: physical interpretation unverified; capture/layout evidence reported separately. PSA-RE bits 2.2. Small-diameter spare wheel detected Upstream default raw=0 (not necessarily valid data).";
CM_ SG_ 294 CrashInfoToCpk "DATABASE_CANDIDATE: physical interpretation unverified; capture/layout evidence reported separately. PSA-RE bits 2.3. Crash information sent to the CPK function Upstream default raw=0 (not necessarily valid data).";
CM_ SG_ 294 GearPositionToDisplay "DATABASE_CANDIDATE: physical interpretation unverified; capture/layout evidence reported separately. PSA-RE bits 2.7-2.4. Gear position to display on the instrument cluster (P, R, N, D, 6th gear) Upstream default raw=11 (not necessarily valid data).";
CM_ SG_ 294 SpaceMeasurementRequest "DATABASE_CANDIDATE: physical interpretation unverified; capture/layout evidence reported separately. PSA-RE bits 1.0. Request to activate the parking space measurement (MPD) function Upstream default raw=0 (not necessarily valid data).";
CM_ SG_ 294 TowHookPresence "DATABASE_CANDIDATE: physical interpretation unverified; capture/layout evidence reported separately. PSA-RE bits 1.1. Tow hook presence Upstream default raw=0 (not necessarily valid data).";
CM_ SG_ 294 TrailerPresence "DATABASE_CANDIDATE: physical interpretation unverified; capture/layout evidence reported separately. PSA-RE bits 1.2. Trailer presence Upstream default raw=0 (not necessarily valid data).";
CM_ SG_ 294 ParkingAidVisualInhibition "DATABASE_CANDIDATE: physical interpretation unverified; capture/layout evidence reported separately. PSA-RE bits 1.3. Parking sensor (AAS) visual display inhibition request Upstream default raw=0 (not necessarily valid data).";
CM_ SG_ 294 ParkingAidSoundInhibition "DATABASE_CANDIDATE: physical interpretation unverified; capture/layout evidence reported separately. PSA-RE bits 1.4. Parking sensor (AAS) sound inhibition request Upstream default raw=0 (not necessarily valid data).";
CM_ SG_ 294 AvailableSpace "DATABASE_CANDIDATE: physical interpretation unverified; capture/layout evidence reported separately. PSA-RE bits 1.5. Available parking space measurement Upstream default raw=0 (not necessarily valid data).";
CM_ SG_ 294 SamActivationRequestStatus "DATABASE_CANDIDATE: physical interpretation unverified; capture/layout evidence reported separately. PSA-RE bits 1.7-1.6. Driver request status for activating/deactivating the parking space measurement (SAM) function Upstream default raw=1 (not necessarily valid data).";
CM_ BO_ 295 "DATABASE_CANDIDATE: physical interpretation unverified; capture/layout evidence reported separately. INFO-DIV CAN, 125000 bit/s; CAN ID 0x127. PSA-RE title: ADAPTIVE_CRUISE_STATUS. Adaptive cruise control status relayed by the body computer: detected target, collision risk, inter-vehicle distance and time gap. Source: https://github.com/prototux/PSA-RE/blob/67f7581e7622410efdbb29c7eda3b86982b9b450/buses/AEE2010.full/LS.INFO-DIV/127.yml. Source sender alternatives: BSI; physical TX/gateway forwarding not verified. ";
CM_ SG_ 295 FrameChecksum "DATABASE_CANDIDATE: physical interpretation unverified; capture/layout evidence reported separately. PSA-RE bits 7.3-7.0. Checksum of the frame Upstream default raw=0 (not necessarily valid data).";
CM_ SG_ 295 ProcessCounter "DATABASE_CANDIDATE: physical interpretation unverified; capture/layout evidence reported separately. PSA-RE bits 7.7-7.4. Rolling counter incremented at each calculation cycle Upstream default raw=0 (not necessarily valid data).";
CM_ SG_ 295 Unused3 "DATABASE_CANDIDATE: physical interpretation unverified; capture/layout evidence reported separately. PSA-RE bits 5.1-6.0. ";
CM_ SG_ 295 InterVehicleTimeDisplay "DATABASE_CANDIDATE: physical interpretation unverified; capture/layout evidence reported separately. PSA-RE bits 5.7-5.2. Inter-vehicle time for display Raw invalid=63; numeric DBC decoders may still scale it: check raw before use. Upstream default raw=63 (not necessarily valid data).";
CM_ SG_ 295 Unused2 "DATABASE_CANDIDATE: physical interpretation unverified; capture/layout evidence reported separately. PSA-RE bits 3.2-4.0. ";
CM_ SG_ 295 ReducedVisibilityStatus "DATABASE_CANDIDATE: physical interpretation unverified; capture/layout evidence reported separately. PSA-RE bits 3.3. Reduced visibility Upstream default raw=0 (not necessarily valid data).";
CM_ SG_ 295 CollisionRiskAlertFunctionState "DATABASE_CANDIDATE: physical interpretation unverified; capture/layout evidence reported separately. PSA-RE bits 3.5-3.4. Collision risk alert function state Upstream default raw=0 (not necessarily valid data).";
CM_ SG_ 295 InterVehicleDistance "DATABASE_CANDIDATE: physical interpretation unverified; capture/layout evidence reported separately. PSA-RE bits 2.7-3.6. Inter-vehicle distance Raw invalid=1023; numeric DBC decoders may still scale it: check raw before use. Upstream default raw=1023 (not necessarily valid data).";
CM_ SG_ 295 TargetDetectedStatus "DATABASE_CANDIDATE: physical interpretation unverified; capture/layout evidence reported separately. PSA-RE bits 1.0. Detected target information Upstream default raw=0 (not necessarily valid data).";
CM_ SG_ 295 DriverTakeoverRequest "DATABASE_CANDIDATE: physical interpretation unverified; capture/layout evidence reported separately. PSA-RE bits 1.2-1.1. Request for the driver to take back control Upstream default raw=0 (not necessarily valid data).";
CM_ SG_ 295 Unused1 "DATABASE_CANDIDATE: physical interpretation unverified; capture/layout evidence reported separately. PSA-RE bits 1.3. ";
CM_ SG_ 295 SensorBlindedStatus "DATABASE_CANDIDATE: physical interpretation unverified; capture/layout evidence reported separately. PSA-RE bits 1.4. Sensor blinded (obstructed) Upstream default raw=0 (not necessarily valid data).";
CM_ SG_ 295 CollisionRiskAlert "DATABASE_CANDIDATE: physical interpretation unverified; capture/layout evidence reported separately. PSA-RE bits 1.7-1.5. Collision risk alert Upstream default raw=0 (not necessarily valid data).";
CM_ BO_ 296 "OWNER_CONFIRMED_FIELDS: GearPositionToDisplay, ParkingBrakes; other fields remain candidates. INFO-DIV CAN, 125000 bit/s; CAN ID 0x128. PSA-RE title: CLUSTER_SIGNAL_COMMAND. Signalling commands sent by the BSI to the instrument cluster: indicators, hazard warning, engine fault display and cluster colour/personalisation. Source: https://github.com/prototux/PSA-RE/blob/67f7581e7622410efdbb29c7eda3b86982b9b450/buses/AEE2010.full/LS.INFO-DIV/128.yml. Source sender alternatives: ICSV,BSI; physical TX/gateway forwarding not verified. Observed 2953 frames in info_apka.csv,info_buzeni_obc.csv,info_charging.csv,info_standby.csv,info_start_jizda.csv,infocan.csv; DLCs [8]. ";
CM_ SG_ 296 Customization "DATABASE_CANDIDATE: physical interpretation unverified; capture/layout evidence reported separately. PSA-RE bits 8.0. Instrument cluster customization change request Upstream default raw=0 (not necessarily valid data).";
CM_ SG_ 296 ColorChange "DATABASE_CANDIDATE: physical interpretation unverified; capture/layout evidence reported separately. PSA-RE bits 8.1. Instrument cluster color change request Upstream default raw=0 (not necessarily valid data).";
CM_ SG_ 296 IgnitionReady "DATABASE_CANDIDATE: physical interpretation unverified; capture/layout evidence reported separately. PSA-RE bits 8.2. READY indicator lighting (hybrid) Upstream default raw=0 (not necessarily valid data).";
CM_ SG_ 296 LowFuelBlink "DATABASE_CANDIDATE: physical interpretation unverified; capture/layout evidence reported separately. PSA-RE bits 8.3. Low fuel indicator blinking request Upstream default raw=0 (not necessarily valid data).";
CM_ SG_ 296 ClutchPedal "DATABASE_CANDIDATE: physical interpretation unverified; capture/layout evidence reported separately. PSA-RE bits 8.5-8.4. Foot on clutch pedal indicator Upstream default raw=0 (not necessarily valid data).";
CM_ SG_ 296 EngineWarningLampCommand "DATABASE_CANDIDATE: physical interpretation unverified; capture/layout evidence reported separately. PSA-RE bits 8.7-8.6. Engine warning lamp lighting command Upstream default raw=0 (not necessarily valid data).";
CM_ SG_ 296 FrontPassengerProtection "DATABASE_CANDIDATE: physical interpretation unverified; capture/layout evidence reported separately. PSA-RE bits 7.0. Front passenger protection activated Upstream default raw=0 (not necessarily valid data).";
CM_ SG_ 296 Warnings "DATABASE_CANDIDATE: physical interpretation unverified; capture/layout evidence reported separately. PSA-RE bits 7.1. Hazard warning lights command Upstream default raw=0 (not necessarily valid data).";
CM_ SG_ 296 OdometerStatus "DATABASE_CANDIDATE: physical interpretation unverified; capture/layout evidence reported separately. PSA-RE bits 7.2. Instrument cluster on/off (held active while the cluster must operate) Upstream default raw=0 (not necessarily valid data).";
CM_ SG_ 296 RearRightSeatbeltBlinkDuplicate "DATABASE_CANDIDATE: physical interpretation unverified; capture/layout evidence reported separately. PSA-RE bits 7.3. Rear right seatbelt reminder light blinking request Upstream default raw=0 (not necessarily valid data).";
CM_ SG_ 296 RearRightSeatbelt "DATABASE_CANDIDATE: physical interpretation unverified; capture/layout evidence reported separately. PSA-RE bits 7.4. Rear right seatbelt reminder Upstream default raw=0 (not necessarily valid data).";
CM_ SG_ 296 RearMiddleSeatbeltBlink "DATABASE_CANDIDATE: physical interpretation unverified; capture/layout evidence reported separately. PSA-RE bits 7.5. Rear middle seatbelt reminder light blinking request Upstream default raw=0 (not necessarily valid data).";
CM_ SG_ 296 RearMiddleSeatbelt "DATABASE_CANDIDATE: physical interpretation unverified; capture/layout evidence reported separately. PSA-RE bits 7.6. Rear middle seatbelt reminder Upstream default raw=0 (not necessarily valid data).";
CM_ SG_ 296 RearLeftSeatbeltBlink "DATABASE_CANDIDATE: physical interpretation unverified; capture/layout evidence reported separately. PSA-RE bits 7.7. Rear left seatbelt reminder light blinking request Upstream default raw=0 (not necessarily valid data).";
CM_ SG_ 296 RearLeftSeatbelt "DATABASE_CANDIDATE: physical interpretation unverified; capture/layout evidence reported separately. PSA-RE bits 6.0. Rear left seatbelt reminder Upstream default raw=0 (not necessarily valid data).";
CM_ SG_ 296 RequestPilotLigthScr "DATABASE_CANDIDATE: physical interpretation unverified; capture/layout evidence reported separately. PSA-RE bits 6.2-6.1. SCR indicator light request Upstream default raw=0 (not necessarily valid data).";
CM_ SG_ 296 FrontRightSeatbeltBlink "DATABASE_CANDIDATE: physical interpretation unverified; capture/layout evidence reported separately. PSA-RE bits 6.3. Passenger seatbelt reminder light blinking request Upstream default raw=0 (not necessarily valid data).";
CM_ SG_ 296 FrontRightSeatbelt "DATABASE_CANDIDATE: physical interpretation unverified; capture/layout evidence reported separately. PSA-RE bits 6.4. Passenger seatbelt reminder Upstream default raw=0 (not necessarily valid data).";
CM_ SG_ 296 FrontLeftSeatbeltBlink "DATABASE_CANDIDATE: physical interpretation unverified; capture/layout evidence reported separately. PSA-RE bits 6.5. Driver seatbelt reminder light blinking request Upstream default raw=0 (not necessarily valid data).";
CM_ SG_ 296 FrontLeftSeatbelt "DATABASE_CANDIDATE: physical interpretation unverified; capture/layout evidence reported separately. PSA-RE bits 6.6. Driver seatbelt reminder Upstream default raw=0 (not necessarily valid data).";
CM_ SG_ 296 LowFuel "DATABASE_CANDIDATE: physical interpretation unverified; capture/layout evidence reported separately. PSA-RE bits 6.7. Low fuel warning Upstream default raw=0 (not necessarily valid data).";
CM_ SG_ 296 Suspension "DATABASE_CANDIDATE: physical interpretation unverified; capture/layout evidence reported separately. PSA-RE bits 5.0. Sport suspension activated Upstream default raw=0 (not necessarily valid data).";
CM_ SG_ 296 EspBlink "DATABASE_CANDIDATE: physical interpretation unverified; capture/layout evidence reported separately. PSA-RE bits 5.1. ESP active (regulating) Upstream default raw=0 (not necessarily valid data).";
CM_ SG_ 296 EspDesactived "DATABASE_CANDIDATE: physical interpretation unverified; capture/layout evidence reported separately. PSA-RE bits 5.2. ESP disabled Upstream default raw=0 (not necessarily valid data).";
CM_ SG_ 296 CafrIndicatorLighting "DATABASE_CANDIDATE: physical interpretation unverified; capture/layout evidence reported separately. PSA-RE bits 5.3. CAFR high beam indicator lamp lit Upstream default raw=0 (not necessarily valid data).";
CM_ SG_ 296 AvailablePlaceBlink "DATABASE_CANDIDATE: physical interpretation unverified; capture/layout evidence reported separately. PSA-RE bits 5.4. Parking space measurement indicator blinking request Upstream default raw=0 (not necessarily valid data).";
CM_ SG_ 296 AvailableSpace "DATABASE_CANDIDATE: physical interpretation unverified; capture/layout evidence reported separately. PSA-RE bits 5.5. Parking space measurement indicator Upstream default raw=0 (not necessarily valid data).";
CM_ SG_ 296 OpenDoorWarningLamp "DATABASE_CANDIDATE: physical interpretation unverified; capture/layout evidence reported separately. PSA-RE bits 5.6. Open door/hatch warning lamp Upstream default raw=0 (not necessarily valid data).";
CM_ SG_ 296 Preheat "DATABASE_CANDIDATE: physical interpretation unverified; capture/layout evidence reported separately. PSA-RE bits 5.7. Diesel glow plug preheating indicator Upstream default raw=0 (not necessarily valid data).";
CM_ SG_ 296 ParkingBrakeDesactivated "DATABASE_CANDIDATE: physical interpretation unverified; capture/layout evidence reported separately. PSA-RE bits 4.0. Electric parking brake disabled Upstream default raw=0 (not necessarily valid data).";
CM_ SG_ 296 ParkingBrakes "OWNER_CONFIRMED: owner Opel Corsa-e, 2026-10-31; Owner confirms selected gear and parking-brake indication work on the installed dashboard. Scope: Gear indication and parking-brake polarity; other cluster flags and exhaustive enum/sentinel behavior are unverified.. PSA-RE bits 4.1. Parking brake status Upstream default raw=0 (not necessarily valid data).";
CM_ SG_ 296 BrakePedal "DATABASE_CANDIDATE: physical interpretation unverified; capture/layout evidence reported separately. PSA-RE bits 4.3-4.2. Foot on brake pedal indicator Upstream default raw=0 (not necessarily valid data).";
CM_ SG_ 296 PassengerAirbag "DATABASE_CANDIDATE: physical interpretation unverified; capture/layout evidence reported separately. PSA-RE bits 4.4. Passenger airbag disabled warning light Upstream default raw=0 (not necessarily valid data).";
CM_ SG_ 296 ChildSafety "DATABASE_CANDIDATE: physical interpretation unverified; capture/layout evidence reported separately. PSA-RE bits 4.5. Child safety lock active indicator Upstream default raw=0 (not necessarily valid data).";
CM_ SG_ 296 Stop "DATABASE_CANDIDATE: physical interpretation unverified; capture/layout evidence reported separately. PSA-RE bits 4.6. STOP indicator lighting Upstream default raw=0 (not necessarily valid data).";
CM_ SG_ 296 Maintenance "DATABASE_CANDIDATE: physical interpretation unverified; capture/layout evidence reported separately. PSA-RE bits 4.7. Service reminder indicator Upstream default raw=0 (not necessarily valid data).";
CM_ SG_ 296 GearboxType "DATABASE_CANDIDATE: physical interpretation unverified; capture/layout evidence reported separately. PSA-RE bits 3.1-3.0. Gearbox mode selection (automatic/manual/robotized) Upstream default raw=1 (not necessarily valid data).";
CM_ SG_ 296 GearShiftArrow "DATABASE_CANDIDATE: physical interpretation unverified; capture/layout evidence reported separately. PSA-RE bits 3.3-3.2. Gear shift indicator arrow lighting Upstream default raw=0 (not necessarily valid data).";
CM_ SG_ 296 GearboxMode "DATABASE_CANDIDATE: physical interpretation unverified; capture/layout evidence reported separately. PSA-RE bits 3.6-3.4. Selected gearbox program (automatic / piloted manual) Upstream default raw=0 (not necessarily valid data).";
CM_ SG_ 296 GearShiftArrowBlink "DATABASE_CANDIDATE: physical interpretation unverified; capture/layout evidence reported separately. PSA-RE bits 3.7. Gear shift arrow lighting type (fixed/blinking) Upstream default raw=0 (not necessarily valid data).";
CM_ SG_ 296 CurrentGearBlink "DATABASE_CANDIDATE: physical interpretation unverified; capture/layout evidence reported separately. PSA-RE bits 2.0. Displayed gear number blinking Upstream default raw=0 (not necessarily valid data).";
CM_ SG_ 296 DriveGear "DATABASE_CANDIDATE: physical interpretation unverified; capture/layout evidence reported separately. PSA-RE bits 2.3-2.1. Gear to display in drive mode Upstream default raw=0 (not necessarily valid data).";
CM_ SG_ 296 GearPositionToDisplay "OWNER_CONFIRMED: owner Opel Corsa-e, 2026-10-31; Owner confirms selected gear and parking-brake indication work on the installed dashboard. Scope: Gear indication and parking-brake polarity; other cluster flags and exhaustive enum/sentinel behavior are unverified.. PSA-RE bits 2.7-2.4. Gear position to display on the instrument cluster (P, R, N, D, 6th gear) Upstream default raw=11 (not necessarily valid data).";
CM_ SG_ 296 Daylights "DATABASE_CANDIDATE: physical interpretation unverified; capture/layout evidence reported separately. PSA-RE bits 1.0. Daytime running lights indicator Upstream default raw=0 (not necessarily valid data).";
CM_ SG_ 296 LeftTurn "DATABASE_CANDIDATE: physical interpretation unverified; capture/layout evidence reported separately. PSA-RE bits 1.1. Left indicator telltale lit Upstream default raw=0 (not necessarily valid data).";
CM_ SG_ 296 RightTurn "DATABASE_CANDIDATE: physical interpretation unverified; capture/layout evidence reported separately. PSA-RE bits 1.2. Right indicator telltale lit Upstream default raw=0 (not necessarily valid data).";
CM_ SG_ 296 RearFogLights "DATABASE_CANDIDATE: physical interpretation unverified; capture/layout evidence reported separately. PSA-RE bits 1.3. Rear fog light telltale lit Upstream default raw=0 (not necessarily valid data).";
CM_ SG_ 296 FrontFogLights "DATABASE_CANDIDATE: physical interpretation unverified; capture/layout evidence reported separately. PSA-RE bits 1.4. Front fog light telltale lit Upstream default raw=0 (not necessarily valid data).";
CM_ SG_ 296 FullBeam "DATABASE_CANDIDATE: physical interpretation unverified; capture/layout evidence reported separately. PSA-RE bits 1.5. High beam telltale lit Upstream default raw=0 (not necessarily valid data).";
CM_ SG_ 296 LowBeam "DATABASE_CANDIDATE: physical interpretation unverified; capture/layout evidence reported separately. PSA-RE bits 1.6. Low beam telltale lit Upstream default raw=0 (not necessarily valid data).";
CM_ SG_ 296 Sidelights "DATABASE_CANDIDATE: physical interpretation unverified; capture/layout evidence reported separately. PSA-RE bits 1.7. Side marker lights telltale lit Upstream default raw=0 (not necessarily valid data).";
CM_ BO_ 297 "DATABASE_CANDIDATE: physical interpretation unverified; capture/layout evidence reported separately. INFO-DIV CAN, 125000 bit/s; CAN ID 0x129. PSA-RE title: NAV_ROAD_CONTEXT_INFO. Road context data relayed to the inter-system bus by the body computer (BSI) gateway: country code, driving side, distance to next junction/speed camera, number of lanes and speed zone. Source: https://github.com/prototux/PSA-RE/blob/67f7581e7622410efdbb29c7eda3b86982b9b450/buses/AEE2010.full/LS.INFO-DIV/129.yml. Source sender alternatives: ICSV,BTEL,OVIP; physical TX/gateway forwarding not verified. ";
CM_ SG_ 297 Unused1 "DATABASE_CANDIDATE: physical interpretation unverified; capture/layout evidence reported separately. PSA-RE bits 7.2-7.0. ";
CM_ SG_ 297 OppositeDirectionLaneCount "DATABASE_CANDIDATE: physical interpretation unverified; capture/layout evidence reported separately. PSA-RE bits 7.4-7.3. Number of lanes in the opposite driving direction Upstream default raw=3 (not necessarily valid data).";
CM_ SG_ 297 LaneCountDrivingDirection "DATABASE_CANDIDATE: physical interpretation unverified; capture/layout evidence reported separately. PSA-RE bits 7.7-7.5. Number of lanes in the driving direction Upstream default raw=7 (not necessarily valid data).";
CM_ SG_ 297 BuiltUpAreaZone "DATABASE_CANDIDATE: physical interpretation unverified; capture/layout evidence reported separately. PSA-RE bits 6.1-6.0. Built-up area status Upstream default raw=2 (not necessarily valid data).";
CM_ SG_ 297 RoadType "DATABASE_CANDIDATE: physical interpretation unverified; capture/layout evidence reported separately. PSA-RE bits 6.5-6.2. Type of road (motorway, multi-lane, single carriageway, roundabout...) Upstream default raw=0 (not necessarily valid data).";
CM_ SG_ 297 DrivingSide "DATABASE_CANDIDATE: physical interpretation unverified; capture/layout evidence reported separately. PSA-RE bits 6.6. Driving side (left-hand or right-hand traffic) Upstream default raw=0 (not necessarily valid data).";
CM_ SG_ 297 SpeedLimitType "DATABASE_CANDIDATE: physical interpretation unverified; capture/layout evidence reported separately. PSA-RE bits 6.7. Speed limit type (implicit/explicit) Upstream default raw=0 (not necessarily valid data).";
CM_ SG_ 297 DistanceToNextSpeedCamera "DATABASE_CANDIDATE: physical interpretation unverified; capture/layout evidence reported separately. PSA-RE bits 5.7-5.0. Distance to the next speed camera Raw invalid=255; numeric DBC decoders may still scale it: check raw before use. Upstream default raw=255 (not necessarily valid data).";
CM_ SG_ 297 DistanceToNextIntersection "DATABASE_CANDIDATE: physical interpretation unverified; capture/layout evidence reported separately. PSA-RE bits 4.7-4.0. Distance to the next intersection Raw invalid=255; numeric DBC decoders may still scale it: check raw before use. Upstream default raw=255 (not necessarily valid data).";
CM_ SG_ 297 CountryCode "DATABASE_CANDIDATE: physical interpretation unverified; capture/layout evidence reported separately. PSA-RE bits 1.7-3.0. Country code (ISO 3166-1 alpha-3) of the current position Source text/byte field exposed as raw integer; no string decoding. Upstream default raw=0 (not necessarily valid data).";
VAL_ 223 ListRefreshRequest 0 "No refresh requested" 1 "Refresh requested" 2 "Refresh stop requested" 3 "Invalid" ;
VAL_ 223 RepeatEnabled 0 "Option deactivated" 1 "Option activated" ;
VAL_ 223 ShuffleModeStatus 0 "Option deactivated" 1 "Option activated" ;
VAL_ 223 RandomEnabled 0 "Option deactivated" 1 "Option activated" ;
VAL_ 223 RadioDabFmStatus 0 "Option not activated" 1 "Option activated" ;
VAL_ 223 RadioTextModeStatus 0 "Option deactivated" 1 "Option activated" ;
VAL_ 223 RadioRdsAfStatus 0 "Option deactivated" 1 "Option activated" ;
VAL_ 223 RadioNewsOption7Status 0 "Option not activated" 1 "Option activated" ;
VAL_ 223 RadioNewsOption6Status 0 "Option not activated" 1 "Option activated" ;
VAL_ 223 RadioNewsOption5Status 0 "Option not activated" 1 "Option activated" ;
VAL_ 223 RadioNewsOption4Status 0 "Option not activated" 1 "Option activated" ;
VAL_ 223 RadioNewsOption3Status 0 "Option not activated" 1 "Option activated" ;
VAL_ 223 RadioNewsOption2Status 0 "Option not activated" 1 "Option activated" ;
VAL_ 223 RadioNewsOption1Status 0 "Option not activated" 1 "Option activated" ;
VAL_ 223 NextListTypeRequested 0 "No acess" 1 "Directory" 2 "Artist" 3 "Genre" 4 "Playlist" 5 "CD list" ;
VAL_ 223 DesignatorBlockType 0 "RAD-specific management" 1 "Block 1" 2 "Block 2" 3 "Block 1 + Block 2" ;
VAL_ 223 ListOpenRequest 0 "No opening request" 1 "Media/tuner list opening request" 2 "Request to open combinations list" 3 "Request to open the pairing list for replacement" 4 "Full phone directory opening request" 5 "Opening request of KML internal directory for view" 6 "Phone directory opening request for single-entry deletion" 7 "Opening request for the BT scan list" 8 "Call log opening request" ;
VAL_ 223 CdTextModeStatus 0 "Option deactivated" 1 "Option activated" ;
VAL_ 223 ModificationInProgress 0 "No modification" 1 "Modification to be taken into account" ;
VAL_ 223 DesignatorButtonManager 0 "Radio" 2 "EMF" ;
VAL_ 224 AcPrecondSundaySchedule4Active 0 "Function off" 1 "Function active" ;
VAL_ 224 AcPrecondSaturdaySchedule4Active 0 "Function off" 1 "Function active" ;
VAL_ 224 AcPrecondFridaySchedule4Active 0 "Function off" 1 "Function active" ;
VAL_ 224 AcPrecondThursdaySchedule4Active 0 "Function off" 1 "Function active" ;
VAL_ 224 AcPrecondWednesdaySchedul_8f02bb 0 "Function off" 1 "Function active" ;
VAL_ 224 AcPrecondTuesdaySchedule4Active 0 "Function off" 1 "Function active" ;
VAL_ 224 AcPrecondMondaySchedule4Active 0 "Function off" 1 "Function active" ;
VAL_ 224 AcPrecondSchedule4Enabled 0 "Function off" 1 "Function active" ;
VAL_ 224 AcPrecondSundaySchedule3Active 0 "Function off" 1 "Function active" ;
VAL_ 224 AcPrecondSaturdaySchedule3Active 0 "Function off" 1 "Function active" ;
VAL_ 224 AcPrecondFridaySchedule3Active 0 "Function off" 1 "Function active" ;
VAL_ 224 AcPrecondThursdaySchedule3Active 0 "Function off" 1 "Function active" ;
VAL_ 224 AcPrecondWednesdaySchedul_dacc80 0 "Function off" 1 "Function active" ;
VAL_ 224 AcPrecondTuesdaySchedule3Active 0 "Function off" 1 "Function active" ;
VAL_ 224 AcPrecondMondaySchedule3Active 0 "Function off" 1 "Function active" ;
VAL_ 224 AcPrecondSchedule3Enabled 0 "Function off" 1 "Function active" ;
VAL_ 225 CpkMenuRequest 0 "No request" 1 "Requested" ;
VAL_ 225 Scp9HmiRequest 0 "No request" 1 "Direction choice requested" 2 "Automatic parking exit" 3 "End of movement" 4 "Deactivated" ;
VAL_ 225 Scp6HmiRequest 0 "No request" 1 "Direction choice requested" 2 "Measurement in progress" 3 "Move forward request" 4 "Reverse gear transition request" 5 "Automatic parking" 6 "End of movement" 7 "Deactivated" ;
VAL_ 225 Scp9Status 0 "No operate" 1 "Manoeuvre in progress" ;
VAL_ 225 NetworkVoltageBoostRequest 0 "No need" 1 "Need" ;
VAL_ 225 EngineOnRequest 0 "False" 1 "True" ;
VAL_ 225 SpaceMeasurementDisplayRequest 0 "No display request" 1 "Display request" ;
VAL_ 225 MeasuredDistance 0 "Insufficient space" 1 "Small space" 2 "Medium space" 3 "Large space" ;
VAL_ 225 SpaceMeasurementStatus 1 "Failure detected" 2 "Status off" 3 "Trailer inhibit" 4 "Active" 5 "Waiting" 6 "Out of service" ;
VAL_ 225 AasDisplayRequest 0 "No display request" 1 "Display request" ;
VAL_ 225 FrontRightStatus 0 "Zone 1 (very close obstacle)" 1 "Area 2" 2 "Zone 3" 3 "zone 4" 4 "Zone 5" 5 "Zone 6" 6 "Zone 7" 7 "Zone 8 (obstacle very far)" ;
VAL_ 225 FrontMiddleStatus 0 "Zone 1 (very close obstacle)" 1 "Area 2" 2 "Zone 3" 3 "zone 4" 4 "Zone 5" 5 "Zone 6" 6 "Zone 7" 7 "Zone 8 (obstacle very far)" ;
VAL_ 225 LateralBeepLocation 0 "No beep" 1 "Rear (maximum)" 2 "Front (maximum)" 3 "Rear and front" ;
VAL_ 225 FrontLeftStatus 0 "Zone 1 (very close obstacle)" 1 "Area 2" 2 "Zone 3" 3 "zone 4" 4 "Zone 5" 5 "Zone 6" 6 "Zone 7" 7 "Zone 8 (obstacle very far)" ;
VAL_ 225 RearRightStatus 0 "Zone 1 (very close obstacle)" 1 "Area 2" 2 "Zone 3" 3 "zone 4" 4 "Zone 5" 5 "Zone 6" 6 "Zone 7" 7 "Zone 8 (obstacle very far)" ;
VAL_ 225 ScpLampStatus 0 "Off" 1 "Steady on" 2 "On, blinking" ;
VAL_ 225 RearMiddleStatus 0 "Zone 1 (very close obstacle)" 1 "Area 2" 2 "Zone 3" 3 "zone 4" 4 "Zone 5" 5 "Zone 6" 6 "Zone 7" 7 "Zone 8 (obstacle very far)" ;
VAL_ 225 RearLeftStatus 0 "Zone 1 (very close obstacle)" 1 "Area 2" 2 "Zone 3" 3 "zone 4" 4 "Zone 5" 5 "Zone 6" 6 "Zone 7" 7 "Zone 8 (obstacle very far)" ;
VAL_ 225 ParkAssistBeepDuration 0 "Duration 1" 1 "Duration 2" 2 "Time 3" 3 "Duration 4" ;
VAL_ 225 LateralParkAssistStatus 1 "Fault" 2 "Driver inhibition" 3 "Trailer inhibit" 4 "Active" 5 "Waiting" 6 "Out of service" ;
VAL_ 225 SoundEnabled 0 "No audio request" 1 "Audio request" ;
VAL_ 225 SoundFr 0 "Rear" 1 "Front (maximum)" ;
VAL_ 225 SoundLr 0 "No beep" 1 "Left" 2 "Right" 3 "Left and Right" ;
VAL_ 225 CpkSelection 0 "Inactive" 1 "Left" 2 "Right" ;
VAL_ 225 FrontStatus 1 "Failure detected" 2 "Driver inhibition" 4 "Active" 5 "Waiting" 6 "Out of service" ;
VAL_ 225 RearParkAssistStatus 1 "Failure detected" 2 "Driver inhibition" 3 "Trailer inhibit" 4 "Active" 5 "Waiting" 6 "Out of service" ;
VAL_ 226 DiscStatus6 0 "Disc inoperative" 1 "Cannot read disc" 2 "Disc upside-down" 3 "Disc absent" ;
VAL_ 226 DiscFormat6 0 "None *" 1 "Audio" 2 "MP3/WMA" ;
VAL_ 226 DiscStatus5 0 "Disc inoperative" 1 "Cannot read disc" 2 "Disc upside-down" 3 "Disc absent" ;
VAL_ 226 DiscFormat5 0 "None *" 1 "Audio" 2 "MP3/WMA" ;
VAL_ 226 DiscStatus4 0 "Disc inoperative" 1 "Cannot read disc" 2 "Disc upside-down" 3 "Disc absent" ;
VAL_ 226 DiscFormat4 0 "None *" 1 "Audio" 2 "MP3/WMA" ;
VAL_ 226 DiscStatus3 0 "Disc inoperative" 1 "Cannot read disc" 2 "Disc upside-down" 3 "Disc absent" ;
VAL_ 226 DiscFormat3 0 "None *" 1 "Audio" 2 "MP3/WMA" ;
VAL_ 226 DiscStatus2 0 "Disc inoperative" 1 "Cannot read disc" 2 "Disc upside-down" 3 "Disc absent" ;
VAL_ 226 DiscFormat2 0 "None *" 1 "Audio" 2 "MP3/WMA" ;
VAL_ 226 DiscStatus1 0 "Disc inoperative" 1 "Cannot read disc" 2 "Disc upside-down" 3 "Disc absent" ;
VAL_ 226 DiscFormat1 0 "None *" 1 "Audio" 2 "MP3/WMA" ;
VAL_ 226 SelectedPresetNumber 0 "None (no longitudinal control)" 1 "Preset 1" 2 "Preset 2" 3 "Preset 3" 4 "Preset 4" 5 "Preset 5" 6 "Preset 6" 7 "Preset 7" 8 "Preset 8" 9 "Preset 9" 10 "Preset 10" 11 "Preset 11" 12 "preset 12" 13 "Preset 13" 14 "Preset 14" 15 "preset 15" ;
VAL_ 226 CdcListCommand 0 "Rest" 1 "List closing request" 2 "List mode refused" 3 "List mode accepted" ;
VAL_ 226 CdcDirectoryType 0 "None" 1 "Disc recall mode" ;
VAL_ 230 BrakeFunctionNeedForStartStop 0 "No need, per brake function" 1 "Stop transition inhibition" 2 "Restart request" 3 "Stop and restart transition inhibited" ;
VAL_ 230 BrakeEcuPowerManagementFault 0 "No fault detected" 1 "Failure detected" ;
VAL_ 230 EmergencyBrakingSignaliza_517ee3 0 "SFU function not present in the brake ECU" 1 "SFU function present in the brake ECU" ;
VAL_ 230 BatteryVoltageUcBrake 255 "Not_available" ;
VAL_ 230 RearRightWheelSpeedSensorFault 0 "No fault on the rear right pulse counter" 1 "Rear right pulse counter fault" ;
VAL_ 230 RearLeftWheelSpeedSensorFault 0 "No fault on RRL pulse counter" 1 "Rear left pulse counter fault" ;
VAL_ 230 AbsFaultLampRequest 0 "Lamp off" 1 "Lamp on" ;
VAL_ 230 BrakeFluidLevelAlert 0 "No alert" 1 "Alert" ;
VAL_ 230 WornBrakePadsIndicator 0 "Brake pads in good condition" 1 "Brake pads worn out" ;
VAL_ 230 RefInProgress 0 "Not in regulation" 1 "In regulation" ;
VAL_ 230 AutomaticHazardLightsByUcBrake 0 "AAFD function not present in the brake ECU" 1 "AAFD function present in the brake ECU" ;
VAL_ 230 AbsInProgress 0 "Not in regulation" 1 "In regulation" ;
VAL_ 230 RefFaultLamp 0 "Lamp off" 1 "Lamp on" ;
VAL_ 231 FrontCollisionWarningRequest 0 "No alert" 1 "Alert" ;
VAL_ 231 AbnormalLaneCrossingRight 0 "No abnormal right-hand crossing" 1 "Abnormal right-hand crossing" ;
VAL_ 231 AbnormalLaneCrossingLeft 0 "No abnormal left-hand crossing" 1 "Abnormal left-hand crossing" ;
VAL_ 231 StlPushLedRequest 0 "Off" 1 "Steady on" 2 "On, blinking" 3 "Invalid" ;
VAL_ 231 ArcPushLedRequest 0 "Off" 1 "Steady on" 2 "On, blinking" 3 "Invalid" ;
VAL_ 232 PowertrainTorquePercent 101 "Not_available" ;
VAL_ 232 PowertrainBoostPercent 101 "Not_available" ;
VAL_ 232 PowertrainPowerPercent 101 "Not_available" ;
VAL_ 233 FlowStatus 0 "ContinueToSend" 1 "Wait" 2 "Overflow" ;
VAL_ 233 IsoTpFrameType 0 "SingleFrame" 1 "FirstFrame" 2 "ConsecutiveFrame" 3 "FlowControl" ;
VAL_ 246 BlinkersStatus 0 "Indicator not active" 1 "Right indicator active" 2 "Left indicator active" 3 "Left and right indicators both active" ;
VAL_ 246 ConnectorAreaLightCommand 0 "Off" 1 "On" ;
VAL_ 246 ClusterIndicatorsTest 0 "No warning lamp test" 1 "Telltale test" ;
VAL_ 246 WheelPosition 0 "Invalid" 1 "Steering right" 2 "Steering left" 3 "Invalid" ;
VAL_ 246 FrontWipersStatus 0 "No wiping confirmed" 1 "Wiping confirmed" ;
VAL_ 246 ReverseStatus 0 "Reverse not engaged" 1 "Reverse engaged" ;
VAL_ 246 ExternalFilteredTemperature 255 "Not_available" ;
VAL_ 246 ExternalTemperature 255 "Not_available" ;
VAL_ 246 TotalMileage 16777215 "Not_available" ;
VAL_ 246 CoolantTemperature 255 "Not_available" ;
VAL_ 246 PowertrainStatus 0 "Engine not running" 1 "Starting in progress" 2 "Engine running" 3 "Engine stopped in stop phase" ;
VAL_ 246 GenStatus 0 "Generator not operational (GNO)" 1 "Generator operational (GO)" ;
VAL_ 246 MainStatus 0 "Stop" 1 "Ignition on" 2 "DEM (starter)" ;
VAL_ 246 FactoryPark 0 "Not parked" 1 "Parked" ;
VAL_ 246 ConfigMode 0 "Factory" 2 "Customer (normal)" ;
VAL_ 257 FlowStatus 0 "ContinueToSend" 1 "Wait" 2 "Overflow" ;
VAL_ 257 IsoTpFrameType 0 "SingleFrame" 1 "FirstFrame" 2 "ConsecutiveFrame" 3 "FlowControl" ;
VAL_ 267 SteeringWheelAngleSource 0 "Estimator" 1 "CAV3" 2 "Integrated CAV3" 3 "other" ;
VAL_ 267 SteeringWheelAngleInaccurate 0 "Accurate steering wheel angle" 1 "Uncertain steering wheel angle" ;
VAL_ 267 SteeringWheelAngleInitialized 0 "Steering wheel angle available" 1 "Steering wheel angle memorised" ;
VAL_ 267 SteeringWheelRotationSpee_effc71 255 "Not_available" ;
VAL_ 267 SteeringWheelAngleSensorStatus 0 "Sensor fault" 1 "Sensor OK" ;
VAL_ 267 SteeringWheelAngleSensorC_affc57 0 "Sensor not calibrated" 1 "Sensor calibrated" ;
VAL_ 267 SteeringWheelAngleSensorA_f0288c 0 "Sensor not adjusted" 1 "Sensor adjusted" ;
VAL_ 267 SteeringWheelAngleSensorF_3754bb 0 "No fault, or fault no longer present" 1 "Inconsistency detected by ESP in steering wheel rotation speed data" 2 "Inconsistency detected by ESP in the steering angle information" 3 "Inconsistency detected by ESP on steering wheel speed and angle information" ;
VAL_ 267 SteeringWheelRotationDirection 0 "Trigonometric (counter-clockwise) direction" 1 "Clockwise" ;
VAL_ 267 SteeringWheelRotationSpeed 255 "Not_available" ;
VAL_ 267 SteeringWheelAngle 32767 "Not_available" ;
VAL_ 274 HmiSoundHarmonyRequest 0 "Family 1" 1 "Family 2" 2 "Family 3" 3 "Family 4" 4 "Family 5" 5 "Family 6" 6 "Family 7" ;
VAL_ 274 HmiSoundLocationRequest 0 "Wheel" 1 "Front left" 2 "Front right" 3 "Rear left" 4 "Rear right" 5 "Touch screen" 6 "Magic touch" 7 "Front center" 8 "Left" 9 "Right" 10 "Centre" 11 "TTS voice recognition" 12 "Front left & right" 13 "Rear left and right" 14 "Invalid" 15 "Invalid" ;
VAL_ 283 ClimatePrecondRemoteSunda_f317f4 0 "Function off" 1 "Function active" ;
VAL_ 283 ClimatePrecondRemoteSatur_993fe6 0 "Function off" 1 "Function active" ;
VAL_ 283 ClimatePrecondRemoteFrida_b8e5fa 0 "Function off" 1 "Function active" ;
VAL_ 283 ClimatePrecondRemoteThurs_ff4734 0 "Function off" 1 "Function active" ;
VAL_ 283 ClimatePrecondRemoteWedne_4ee4b3 0 "Function off" 1 "Function active" ;
VAL_ 283 ClimatePrecondRemoteTuesd_931c43 0 "Function off" 1 "Function active" ;
VAL_ 283 ClimatePrecondRemoteMonda_aa1b42 0 "Function off" 1 "Function active" ;
VAL_ 283 ClimatePrecondRemoteSlot4Enabled 0 "Function off" 1 "Function active" ;
VAL_ 283 ClimatePrecondRemoteSunda_628b10 0 "Function off" 1 "Function active" ;
VAL_ 283 ClimatePrecondRemoteSatur_18e3bf 0 "Function off" 1 "Function active" ;
VAL_ 283 ClimatePrecondRemoteFrida_c5f06a 0 "Function off" 1 "Function active" ;
VAL_ 283 ClimatePrecondRemoteThurs_3604aa 0 "Function off" 1 "Function active" ;
VAL_ 283 ClimatePrecondRemoteWedne_be6e1a 0 "Function off" 1 "Function active" ;
VAL_ 283 ClimatePrecondRemoteTuesd_46cf5d 0 "Function off" 1 "Function active" ;
VAL_ 283 ClimatePrecondRemoteMonda_edf0b6 0 "Function off" 1 "Function active" ;
VAL_ 283 ClimatePrecondRemoteSlot3Enabled 0 "Function off" 1 "Function active" ;
VAL_ 284 SpeedInfoRobustnessFlag 0 "Not robust" 1 "robust" ;
VAL_ 284 SpeedSignType 0 "Speed limit area" 1 "End of speed limit area" 3 "Invalid" ;
VAL_ 284 IlvSpeedToDisplay 255 "Not_available" ;
VAL_ 284 CdpStatus 0 "Normal" 1 "Faulty" ;
VAL_ 284 RainSensorWiperState 0 "Stop" 2 "Low speed (or variable speed)" 3 "HS (high side)" ;
VAL_ 284 WiperSweepSpeed 0 "Speed 0 (low speed)" 1 "Speed 1" 2 "Speed 2" 3 "Speed 3" 4 "Speed 4" 5 "Speed 5" 6 "Speed 6" 7 "Speed 7" 8 "Speed 8" 9 "Speed 9" 10 "Speed 10" 11 "Speed 11" 12 "Speed 12" 13 "Speed 13" 14 "Speed 14" 15 "Speed 15 (HS)" ;
VAL_ 284 CdlStatus 0 "Normal" 1 "Faulty" ;
VAL_ 284 AafRequest 0 "No request" 1 "Requested" ;
VAL_ 284 CafrBrightnessStatus 0 "CAFR brightness not OK" 1 "CAFR brightness OK" ;
VAL_ 284 CafrFunctionFault 0 "Normal" 1 "Faulty" ;
VAL_ 284 LowHighBeamSwitchingRequest 0 "Dipped beam position" 1 "High beam position" ;
VAL_ 284 AbnormalLaneDepartureLeft 0 "No abnormal left-hand crossing" 1 "Abnormal left-hand crossing" ;
VAL_ 284 AbnormalLaneDepartureRight 0 "No abnormal right-hand crossing" 1 "Abnormal right-hand crossing" ;
VAL_ 284 StlFaultPresent 0 "No fault detected" 1 "Failure detected" ;
VAL_ 287 FlowStatus 0 "ContinueToSend" 1 "Wait" 2 "Overflow" ;
VAL_ 287 IsoTpFrameType 0 "SingleFrame" 1 "FirstFrame" 2 "ConsecutiveFrame" 3 "FlowControl" ;
VAL_ 288 AlertLogMenuAvailability 0 "Menu not accessible, cannot be activated" 1 "Menu not accessible, activation possible" 2 "Menu accessible but cannot be activated" 3 "Menu accessible and can be activated" ;
VAL_ 288 TotalDataBlockCount 0 "data invalid" 1 "1 data block" 2 "2 data blocks" 3 "3 data blocks" ;
VAL_ 288 ActiveDataBlockNumber 0 "data invalid" 1 "Data block no. 1" 2 "Data block no. 2" 3 "Data block no. 3" ;
VAL_ 289 StopStartPreparationStatus 1 "No restart preparation in process" 2 "Restart preparation in progress" ;
VAL_ 290 Knob2SyncRequest 0 "Synchronization requested" 1 "No synchronization requested" ;
VAL_ 290 Knob1SyncRequest 0 "Synchronization requested" 1 "No synchronization requested" ;
VAL_ 290 FrontPanelBpKeyPressed 0 "Released" 1 "Pressed" ;
VAL_ 290 FrontPanelKey45Pressed 0 "Released" 1 "Pressed" ;
VAL_ 290 PanelKey44Pressed 0 "Released" 1 "Pressed" ;
VAL_ 290 PanelKey43Pressed 0 "Released" 1 "Pressed" ;
VAL_ 290 PanelKey42Pressed 0 "Released" 1 "Pressed" ;
VAL_ 290 PanelKey41Pressed 0 "Released" 1 "Pressed" ;
VAL_ 290 PanelKey40Pressed 0 "Released" 1 "Pressed" ;
VAL_ 290 PanelKey39Pressed 0 "Released" 1 "Pressed" ;
VAL_ 290 PanelKey38Pressed 0 "Released" 1 "Pressed" ;
VAL_ 290 PanelKey37Pressed 0 "Released" 1 "Pressed" ;
VAL_ 290 PanelKey36Pressed 0 "Released" 1 "Pressed" ;
VAL_ 290 PanelKey35Pressed 0 "Released" 1 "Pressed" ;
VAL_ 290 PanelKey34Pressed 0 "Released" 1 "Pressed" ;
VAL_ 290 PanelKey33Pressed 0 "Released" 1 "Pressed" ;
VAL_ 290 PanelKey32Pressed 0 "Released" 1 "Pressed" ;
VAL_ 290 PanelKey31Pressed 0 "Released" 1 "Pressed" ;
VAL_ 290 PanelKey30Pressed 0 "Released" 1 "Pressed" ;
VAL_ 290 PanelKey29Pressed 0 "Released" 1 "Pressed" ;
VAL_ 290 PanelKey28Pressed 0 "Released" 1 "Pressed" ;
VAL_ 290 PanelKey27Pressed 0 "Released" 1 "Pressed" ;
VAL_ 290 PanelKey26Pressed 0 "Released" 1 "Pressed" ;
VAL_ 290 PanelKey25Pressed 0 "Released" 1 "Pressed" ;
VAL_ 290 PanelKey24Pressed 0 "Released" 1 "Pressed" ;
VAL_ 290 PanelKey23Pressed 0 "Released" 1 "Pressed" ;
VAL_ 290 PanelKey22Pressed 0 "Released" 1 "Pressed" ;
VAL_ 290 PanelKey21Pressed 0 "Released" 1 "Pressed" ;
VAL_ 290 PanelKey20Pressed 0 "Released" 1 "Pressed" ;
VAL_ 290 PanelKey19Pressed 0 "Released" 1 "Pressed" ;
VAL_ 290 PanelKey18Pressed 0 "Released" 1 "Pressed" ;
VAL_ 290 PanelKey17Pressed 0 "Released" 1 "Pressed" ;
VAL_ 290 PanelKey16Pressed 0 "Released" 1 "Pressed" ;
VAL_ 290 PanelKey15Pressed 0 "Released" 1 "Pressed" ;
VAL_ 290 PanelKey14Pressed 0 "Released" 1 "Pressed" ;
VAL_ 290 PanelKey13Pressed 0 "Released" 1 "Pressed" ;
VAL_ 290 PanelKey12Pressed 0 "Released" 1 "Pressed" ;
VAL_ 290 PanelKey11Pressed 0 "Released" 1 "Pressed" ;
VAL_ 290 PanelKey10Pressed 0 "Released" 1 "Pressed" ;
VAL_ 290 PanelKey9Pressed 0 "Released" 1 "Pressed" ;
VAL_ 290 PanelKey8Pressed 0 "Released" 1 "Pressed" ;
VAL_ 290 PanelKey7Pressed 0 "Released" 1 "Pressed" ;
VAL_ 290 PanelKey6Pressed 0 "Released" 1 "Pressed" ;
VAL_ 290 PanelKey5Pressed 0 "Released" 1 "Pressed" ;
VAL_ 290 PanelKey4Pressed 0 "Released" 1 "Pressed" ;
VAL_ 290 PanelKey3Pressed 0 "Released" 1 "Pressed" ;
VAL_ 290 PanelKey2Pressed 0 "Released" 1 "Pressed" ;
VAL_ 290 PanelKey1Pressed 0 "Released" 1 "Pressed" ;
VAL_ 291 FlowStatus 0 "ContinueToSend" 1 "Wait" 2 "Overflow" ;
VAL_ 291 IsoTpFrameType 0 "SingleFrame" 1 "FirstFrame" 2 "ConsecutiveFrame" 3 "FlowControl" ;
VAL_ 293 FlowStatus 0 "ContinueToSend" 1 "Wait" 2 "Overflow" ;
VAL_ 293 IsoTpFrameType 0 "SingleFrame" 1 "FirstFrame" 2 "ConsecutiveFrame" 3 "FlowControl" ;
VAL_ 294 SmallSpareWheelDetected 0 "No small spare wheel detected" 1 "Small spare wheel detected" ;
VAL_ 294 CrashInfoToCpk 0 "No crash" 1 "Crash" ;
VAL_ 294 GearPositionToDisplay 0 "Passenger-side display" 1 "Rear display" 2 "N displayed" 3 "Right-side display" 4 "Gear 6" 5 "5th gear" 6 "4th gear" 7 "3rd gear" 8 "Gear 2" 9 "1st gear" 10 "Invalid" 11 "No gear to display" 12 "7th gear" 13 "8th gear" 14 "Gear 9" 15 "B displayed" ;
VAL_ 294 SpaceMeasurementRequest 0 "Inactive" 1 "Active" ;
VAL_ 294 TowHookPresence 0 "No hook" 1 "Hook present" ;
VAL_ 294 TrailerPresence 0 "No trailer" 1 "Trailer present" ;
VAL_ 294 ParkingAidVisualInhibition 0 "No inhibition" 1 "Inhibition" ;
VAL_ 294 ParkingAidSoundInhibition 0 "No inhibition" 1 "Inhibition" ;
VAL_ 294 AvailableSpace 0 "Command not activated" 1 "Command activated" ;
VAL_ 294 SamActivationRequestStatus 0 "Not pressed" 1 "Pressed" 2 "Invalid" 3 "Invalid" ;
VAL_ 295 InterVehicleTimeDisplay 63 "Not_available" ;
VAL_ 295 ReducedVisibilityStatus 0 "No reduced visibility" 1 "Reduced visibility" ;
VAL_ 295 CollisionRiskAlertFunctionState 0 "Initialisation" 1 "Unavailable" 2 "Nominal" 3 "Fault" ;
VAL_ 295 InterVehicleDistance 1023 "Not_available" ;
VAL_ 295 TargetDetectedStatus 0 "Initialisation or no target detected" 1 "Target detected" ;
VAL_ 295 DriverTakeoverRequest 0 "No request" 1 "Non-critical request" 2 "Critical request" 3 "Invalid" ;
VAL_ 295 SensorBlindedStatus 0 "False" 1 "True" ;
VAL_ 295 CollisionRiskAlert 0 "No alert" 1 "Latent warning" 2 "Acute pre-warning" 3 "Latent warning and acute pre-warning" 4 "Acute warning" 5 "Latent warning and acute warning" 6 "Acute pre-warning and acute warning" 7 "Warning and acute pre-warning and acute warning" ;
VAL_ 296 Customization 0 "No request" 1 "Requested" ;
VAL_ 296 ColorChange 0 "No request" 1 "Requested" ;
VAL_ 296 IgnitionReady 0 "No request" 1 "Requested" ;
VAL_ 296 LowFuelBlink 0 "Steady lighting request" 1 "Flashing request" ;
VAL_ 296 ClutchPedal 0 "Off" 1 "On" 2 "Flashing" 3 "Invalid" ;
VAL_ 296 EngineWarningLampCommand 0 "No request" 1 "G3 request" 2 "G4 request" ;
VAL_ 296 FrontPassengerProtection 0 "No request" 1 "Requested" ;
VAL_ 296 Warnings 0 "Warnings not activated" 1 "Hazard warning activated" ;
VAL_ 296 OdometerStatus 0 "Handheld not activated" 1 "Handset activated" ;
VAL_ 296 RearRightSeatbeltBlinkDuplicate 0 "Steady" 1 "Flashing lamp" ;
VAL_ 296 RearRightSeatbelt 0 "Normal" 1 "Unfastened" ;
VAL_ 296 RearMiddleSeatbeltBlink 0 "Steady" 1 "Flashing lamp" ;
VAL_ 296 RearMiddleSeatbelt 0 "Normal" 1 "Unfastened" ;
VAL_ 296 RearLeftSeatbeltBlink 0 "Steady" 1 "Flashing lamp" ;
VAL_ 296 RearLeftSeatbelt 0 "Normal" 1 "Unfastened" ;
VAL_ 296 RequestPilotLigthScr 0 "Off" 1 "Flashing" 2 "Steady on" ;
VAL_ 296 FrontRightSeatbeltBlink 0 "Steady" 1 "Flashing lamp" ;
VAL_ 296 FrontRightSeatbelt 0 "Normal" 1 "Unfastened" ;
VAL_ 296 FrontLeftSeatbeltBlink 0 "Steady" 1 "Flashing lamp" ;
VAL_ 296 FrontLeftSeatbelt 0 "Normal" 1 "Unfastened" ;
VAL_ 296 LowFuel 0 "Off" 1 "On" ;
VAL_ 296 Suspension 0 "Sport suspension not activated" 1 "Sport suspension activated" ;
VAL_ 296 EspBlink 0 "Inactive" 1 "Active" ;
VAL_ 296 EspDesactived 0 "Operation" 1 "Inhibited" ;
VAL_ 296 CafrIndicatorLighting 0 "High beams off" 1 "High beam lights on" ;
VAL_ 296 AvailablePlaceBlink 0 "Steady" 1 "Flashing lamp" ;
VAL_ 296 AvailableSpace 0 "Lamp off" 1 "Lamp on" ;
VAL_ 296 OpenDoorWarningLamp 0 "Hard" 1 "Open" ;
VAL_ 296 Preheat 0 "Preheating not active" 1 "Preheating activated" ;
VAL_ 296 ParkingBrakeDesactivated 0 "Normal" 1 "Inhibited" ;
VAL_ 296 ParkingBrakes 0 "Loose" 1 "Tight" ;
VAL_ 296 BrakePedal 0 "Off" 1 "On" 2 "Flashing" 3 "Invalid" ;
VAL_ 296 PassengerAirbag 0 "Normal" 1 "Inhibited" ;
VAL_ 296 ChildSafety 0 "Inactive" 1 "Active" ;
VAL_ 296 Stop 0 "Lamp off" 1 "Lamp on" ;
VAL_ 296 Maintenance 0 "Lamp off" 1 "Lamp on" ;
VAL_ 296 GearboxType 0 "Automatic gearbox mode" 1 "Manual gearbox mode" 2 "Piloted manual gearbox" 3 "DCT mode" ;
VAL_ 296 GearShiftArrow 0 "No ignition" 1 "Rising-arrow ignition" 2 "Lowering arrow ignition" 3 "Rising and lowering arrow lit" ;
VAL_ 296 GearboxMode 0 "Automatic" 2 "Auto + Sport" 4 "Sequential" 5 "Sequential + Sport" 6 "Auto + Snow" 7 "ASM" ;
VAL_ 296 GearShiftArrowBlink 0 "Arrow lit steady" 1 "Arrow lit, blinking" ;
VAL_ 296 CurrentGearBlink 0 "Steady" 1 "Flashing" ;
VAL_ 296 DriveGear 0 "Disengaged" 1 "Gear 1" 2 "Gear 2" 3 "Gear 3" 4 "Gear 4" 5 "Gear 5" 6 "Gear ratio 6" 7 "Invalid" ;
VAL_ 296 GearPositionToDisplay 0 "Passenger-side display" 1 "Rear display" 2 "N displayed" 3 "Right-side display" 4 "Gear 6" 5 "5th gear" 6 "4th gear" 7 "3rd gear" 8 "Gear 2" 9 "1st gear" 10 "Invalid" 11 "No gear to display" 12 "7th gear" 13 "8th gear" 14 "Gear 9" 15 "B displayed" ;
VAL_ 296 Daylights 0 "Lamp off" 1 "Lamp on" ;
VAL_ 296 LeftTurn 0 "Left indicator off" 1 "Left indicator active" ;
VAL_ 296 RightTurn 0 "Right indicator off" 1 "Right indicator active" ;
VAL_ 296 RearFogLights 0 "Rear fog lights off" 1 "Rear fog lamp on" ;
VAL_ 296 FrontFogLights 0 "Front fog lights off" 1 "Front fog lights on" ;
VAL_ 296 FullBeam 0 "High beams off" 1 "High beam lights on" ;
VAL_ 296 LowBeam 0 "Low beams off" 1 "Dipped beam lights on" ;
VAL_ 296 Sidelights 0 "Position lights off" 1 "Position lights on" ;
VAL_ 297 OppositeDirectionLaneCount 0 "0" 1 "1" 2 "2" 3 "Invalid" ;
VAL_ 297 LaneCountDrivingDirection 0 "0" 1 "1" 2 "2" 3 "3" 4 "4" 5 "5" 6 "6" 7 "Invalid" ;
VAL_ 297 BuiltUpAreaZone 0 "Segment not part of a built-up area" 1 "Segment part of a built-up area" 2 "Unknown" 3 "Invalid" ;
VAL_ 297 RoadType 0 "Unknown" 1 "Freeway or controlled-access road that is not a ramp or slip road" 2 "Multiple carriageway (or road digitized multiple times)" 3 "Single carriageway" 4 "Roundabout" 5 "Traffic squares / special traffic pattern" 8 "Parallel road (slip road type)" 9 "Slip road/ramp on a motorway or controlled-access road" 10 "Slip road/ramp (not on a motorway or controlled-access road)" 11 "Service road" 12 "Entrance to or exit from a car park" 13 "Entering or exiting a service station" 14 "Pedestrian zone" 15 "Invalid" ;
VAL_ 297 DrivingSide 0 "Right (maximum)" 1 "Left" ;
VAL_ 297 SpeedLimitType 0 "Default" 1 "Explicit" ;
VAL_ 297 DistanceToNextSpeedCamera 255 "Not_available" ;
VAL_ 297 DistanceToNextIntersection 255 "Not_available" ;
SG_MUL_VAL_ 233 SingleFrameLength IsoTpFrameType 0-0;
SG_MUL_VAL_ 233 FirstFrameLength IsoTpFrameType 1-1;
SG_MUL_VAL_ 233 ConsecutiveSequence IsoTpFrameType 2-2;
SG_MUL_VAL_ 233 FlowStatus IsoTpFrameType 3-3;
SG_MUL_VAL_ 233 UnknownPciLow IsoTpFrameType 4-15;
SG_MUL_VAL_ 233 BlockSize IsoTpFrameType 3-3;
SG_MUL_VAL_ 233 SingleData1 IsoTpFrameType 0-0;
SG_MUL_VAL_ 233 ConsecutiveData1 IsoTpFrameType 2-2;
SG_MUL_VAL_ 233 UnknownData1 IsoTpFrameType 4-15;
SG_MUL_VAL_ 233 SeparationTimeRaw IsoTpFrameType 3-3;
SG_MUL_VAL_ 233 SingleData2 IsoTpFrameType 0-0;
SG_MUL_VAL_ 233 ConsecutiveData2 IsoTpFrameType 2-2;
SG_MUL_VAL_ 233 UnknownData2 IsoTpFrameType 4-15;
SG_MUL_VAL_ 233 FirstData1 IsoTpFrameType 1-1;
SG_MUL_VAL_ 233 SingleData3 IsoTpFrameType 0-0;
SG_MUL_VAL_ 233 ConsecutiveData3 IsoTpFrameType 2-2;
SG_MUL_VAL_ 233 UnknownData3 IsoTpFrameType 4-15;
SG_MUL_VAL_ 233 FirstData2 IsoTpFrameType 1-1;
SG_MUL_VAL_ 233 FlowPadding1 IsoTpFrameType 3-3;
SG_MUL_VAL_ 233 SingleData4 IsoTpFrameType 0-0;
SG_MUL_VAL_ 233 ConsecutiveData4 IsoTpFrameType 2-2;
SG_MUL_VAL_ 233 UnknownData4 IsoTpFrameType 4-15;
SG_MUL_VAL_ 233 FirstData3 IsoTpFrameType 1-1;
SG_MUL_VAL_ 233 FlowPadding2 IsoTpFrameType 3-3;
SG_MUL_VAL_ 233 SingleData5 IsoTpFrameType 0-0;
SG_MUL_VAL_ 233 ConsecutiveData5 IsoTpFrameType 2-2;
SG_MUL_VAL_ 233 UnknownData5 IsoTpFrameType 4-15;
SG_MUL_VAL_ 233 FirstData4 IsoTpFrameType 1-1;
SG_MUL_VAL_ 233 FlowPadding3 IsoTpFrameType 3-3;
SG_MUL_VAL_ 233 SingleData6 IsoTpFrameType 0-0;
SG_MUL_VAL_ 233 ConsecutiveData6 IsoTpFrameType 2-2;
SG_MUL_VAL_ 233 UnknownData6 IsoTpFrameType 4-15;
SG_MUL_VAL_ 233 FirstData5 IsoTpFrameType 1-1;
SG_MUL_VAL_ 233 FlowPadding4 IsoTpFrameType 3-3;
SG_MUL_VAL_ 233 SingleData7 IsoTpFrameType 0-0;
SG_MUL_VAL_ 233 ConsecutiveData7 IsoTpFrameType 2-2;
SG_MUL_VAL_ 233 UnknownData7 IsoTpFrameType 4-15;
SG_MUL_VAL_ 233 FirstData6 IsoTpFrameType 1-1;
SG_MUL_VAL_ 233 FlowPadding5 IsoTpFrameType 3-3;
SG_MUL_VAL_ 257 SingleFrameLength IsoTpFrameType 0-0;
SG_MUL_VAL_ 257 FirstFrameLength IsoTpFrameType 1-1;
SG_MUL_VAL_ 257 ConsecutiveSequence IsoTpFrameType 2-2;
SG_MUL_VAL_ 257 FlowStatus IsoTpFrameType 3-3;
SG_MUL_VAL_ 257 UnknownPciLow IsoTpFrameType 4-15;
SG_MUL_VAL_ 257 BlockSize IsoTpFrameType 3-3;
SG_MUL_VAL_ 257 SingleData1 IsoTpFrameType 0-0;
SG_MUL_VAL_ 257 ConsecutiveData1 IsoTpFrameType 2-2;
SG_MUL_VAL_ 257 UnknownData1 IsoTpFrameType 4-15;
SG_MUL_VAL_ 257 SeparationTimeRaw IsoTpFrameType 3-3;
SG_MUL_VAL_ 257 SingleData2 IsoTpFrameType 0-0;
SG_MUL_VAL_ 257 ConsecutiveData2 IsoTpFrameType 2-2;
SG_MUL_VAL_ 257 UnknownData2 IsoTpFrameType 4-15;
SG_MUL_VAL_ 257 FirstData1 IsoTpFrameType 1-1;
SG_MUL_VAL_ 257 SingleData3 IsoTpFrameType 0-0;
SG_MUL_VAL_ 257 ConsecutiveData3 IsoTpFrameType 2-2;
SG_MUL_VAL_ 257 UnknownData3 IsoTpFrameType 4-15;
SG_MUL_VAL_ 257 FirstData2 IsoTpFrameType 1-1;
SG_MUL_VAL_ 257 FlowPadding1 IsoTpFrameType 3-3;
SG_MUL_VAL_ 257 SingleData4 IsoTpFrameType 0-0;
SG_MUL_VAL_ 257 ConsecutiveData4 IsoTpFrameType 2-2;
SG_MUL_VAL_ 257 UnknownData4 IsoTpFrameType 4-15;
SG_MUL_VAL_ 257 FirstData3 IsoTpFrameType 1-1;
SG_MUL_VAL_ 257 FlowPadding2 IsoTpFrameType 3-3;
SG_MUL_VAL_ 257 SingleData5 IsoTpFrameType 0-0;
SG_MUL_VAL_ 257 ConsecutiveData5 IsoTpFrameType 2-2;
SG_MUL_VAL_ 257 UnknownData5 IsoTpFrameType 4-15;
SG_MUL_VAL_ 257 FirstData4 IsoTpFrameType 1-1;
SG_MUL_VAL_ 257 FlowPadding3 IsoTpFrameType 3-3;
SG_MUL_VAL_ 257 SingleData6 IsoTpFrameType 0-0;
SG_MUL_VAL_ 257 ConsecutiveData6 IsoTpFrameType 2-2;
SG_MUL_VAL_ 257 UnknownData6 IsoTpFrameType 4-15;
SG_MUL_VAL_ 257 FirstData5 IsoTpFrameType 1-1;
SG_MUL_VAL_ 257 FlowPadding4 IsoTpFrameType 3-3;
SG_MUL_VAL_ 257 SingleData7 IsoTpFrameType 0-0;
SG_MUL_VAL_ 257 ConsecutiveData7 IsoTpFrameType 2-2;
SG_MUL_VAL_ 257 UnknownData7 IsoTpFrameType 4-15;
SG_MUL_VAL_ 257 FirstData6 IsoTpFrameType 1-1;
SG_MUL_VAL_ 257 FlowPadding5 IsoTpFrameType 3-3;
SG_MUL_VAL_ 287 SingleFrameLength IsoTpFrameType 0-0;
SG_MUL_VAL_ 287 FirstFrameLength IsoTpFrameType 1-1;
SG_MUL_VAL_ 287 ConsecutiveSequence IsoTpFrameType 2-2;
SG_MUL_VAL_ 287 FlowStatus IsoTpFrameType 3-3;
SG_MUL_VAL_ 287 UnknownPciLow IsoTpFrameType 4-15;
SG_MUL_VAL_ 287 BlockSize IsoTpFrameType 3-3;
SG_MUL_VAL_ 287 SingleData1 IsoTpFrameType 0-0;
SG_MUL_VAL_ 287 ConsecutiveData1 IsoTpFrameType 2-2;
SG_MUL_VAL_ 287 UnknownData1 IsoTpFrameType 4-15;
SG_MUL_VAL_ 287 SeparationTimeRaw IsoTpFrameType 3-3;
SG_MUL_VAL_ 287 SingleData2 IsoTpFrameType 0-0;
SG_MUL_VAL_ 287 ConsecutiveData2 IsoTpFrameType 2-2;
SG_MUL_VAL_ 287 UnknownData2 IsoTpFrameType 4-15;
SG_MUL_VAL_ 287 FirstData1 IsoTpFrameType 1-1;
SG_MUL_VAL_ 287 SingleData3 IsoTpFrameType 0-0;
SG_MUL_VAL_ 287 ConsecutiveData3 IsoTpFrameType 2-2;
SG_MUL_VAL_ 287 UnknownData3 IsoTpFrameType 4-15;
SG_MUL_VAL_ 287 FirstData2 IsoTpFrameType 1-1;
SG_MUL_VAL_ 287 FlowPadding1 IsoTpFrameType 3-3;
SG_MUL_VAL_ 287 SingleData4 IsoTpFrameType 0-0;
SG_MUL_VAL_ 287 ConsecutiveData4 IsoTpFrameType 2-2;
SG_MUL_VAL_ 287 UnknownData4 IsoTpFrameType 4-15;
SG_MUL_VAL_ 287 FirstData3 IsoTpFrameType 1-1;
SG_MUL_VAL_ 287 FlowPadding2 IsoTpFrameType 3-3;
SG_MUL_VAL_ 287 SingleData5 IsoTpFrameType 0-0;
SG_MUL_VAL_ 287 ConsecutiveData5 IsoTpFrameType 2-2;
SG_MUL_VAL_ 287 UnknownData5 IsoTpFrameType 4-15;
SG_MUL_VAL_ 287 FirstData4 IsoTpFrameType 1-1;
SG_MUL_VAL_ 287 FlowPadding3 IsoTpFrameType 3-3;
SG_MUL_VAL_ 287 SingleData6 IsoTpFrameType 0-0;
SG_MUL_VAL_ 287 ConsecutiveData6 IsoTpFrameType 2-2;
SG_MUL_VAL_ 287 UnknownData6 IsoTpFrameType 4-15;
SG_MUL_VAL_ 287 FirstData5 IsoTpFrameType 1-1;
SG_MUL_VAL_ 287 FlowPadding4 IsoTpFrameType 3-3;
SG_MUL_VAL_ 287 SingleData7 IsoTpFrameType 0-0;
SG_MUL_VAL_ 287 ConsecutiveData7 IsoTpFrameType 2-2;
SG_MUL_VAL_ 287 UnknownData7 IsoTpFrameType 4-15;
SG_MUL_VAL_ 287 FirstData6 IsoTpFrameType 1-1;
SG_MUL_VAL_ 287 FlowPadding5 IsoTpFrameType 3-3;
SG_MUL_VAL_ 291 SingleFrameLength IsoTpFrameType 0-0;
SG_MUL_VAL_ 291 FirstFrameLength IsoTpFrameType 1-1;
SG_MUL_VAL_ 291 ConsecutiveSequence IsoTpFrameType 2-2;
SG_MUL_VAL_ 291 FlowStatus IsoTpFrameType 3-3;
SG_MUL_VAL_ 291 UnknownPciLow IsoTpFrameType 4-15;
SG_MUL_VAL_ 291 BlockSize IsoTpFrameType 3-3;
SG_MUL_VAL_ 291 SingleData1 IsoTpFrameType 0-0;
SG_MUL_VAL_ 291 ConsecutiveData1 IsoTpFrameType 2-2;
SG_MUL_VAL_ 291 UnknownData1 IsoTpFrameType 4-15;
SG_MUL_VAL_ 291 SeparationTimeRaw IsoTpFrameType 3-3;
SG_MUL_VAL_ 291 SingleData2 IsoTpFrameType 0-0;
SG_MUL_VAL_ 291 ConsecutiveData2 IsoTpFrameType 2-2;
SG_MUL_VAL_ 291 UnknownData2 IsoTpFrameType 4-15;
SG_MUL_VAL_ 291 FirstData1 IsoTpFrameType 1-1;
SG_MUL_VAL_ 291 SingleData3 IsoTpFrameType 0-0;
SG_MUL_VAL_ 291 ConsecutiveData3 IsoTpFrameType 2-2;
SG_MUL_VAL_ 291 UnknownData3 IsoTpFrameType 4-15;
SG_MUL_VAL_ 291 FirstData2 IsoTpFrameType 1-1;
SG_MUL_VAL_ 291 FlowPadding1 IsoTpFrameType 3-3;
SG_MUL_VAL_ 291 SingleData4 IsoTpFrameType 0-0;
SG_MUL_VAL_ 291 ConsecutiveData4 IsoTpFrameType 2-2;
SG_MUL_VAL_ 291 UnknownData4 IsoTpFrameType 4-15;
SG_MUL_VAL_ 291 FirstData3 IsoTpFrameType 1-1;
SG_MUL_VAL_ 291 FlowPadding2 IsoTpFrameType 3-3;
SG_MUL_VAL_ 291 SingleData5 IsoTpFrameType 0-0;
SG_MUL_VAL_ 291 ConsecutiveData5 IsoTpFrameType 2-2;
SG_MUL_VAL_ 291 UnknownData5 IsoTpFrameType 4-15;
SG_MUL_VAL_ 291 FirstData4 IsoTpFrameType 1-1;
SG_MUL_VAL_ 291 FlowPadding3 IsoTpFrameType 3-3;
SG_MUL_VAL_ 291 SingleData6 IsoTpFrameType 0-0;
SG_MUL_VAL_ 291 ConsecutiveData6 IsoTpFrameType 2-2;
SG_MUL_VAL_ 291 UnknownData6 IsoTpFrameType 4-15;
SG_MUL_VAL_ 291 FirstData5 IsoTpFrameType 1-1;
SG_MUL_VAL_ 291 FlowPadding4 IsoTpFrameType 3-3;
SG_MUL_VAL_ 291 SingleData7 IsoTpFrameType 0-0;
SG_MUL_VAL_ 291 ConsecutiveData7 IsoTpFrameType 2-2;
SG_MUL_VAL_ 291 UnknownData7 IsoTpFrameType 4-15;
SG_MUL_VAL_ 291 FirstData6 IsoTpFrameType 1-1;
SG_MUL_VAL_ 291 FlowPadding5 IsoTpFrameType 3-3;
SG_MUL_VAL_ 293 SingleFrameLength IsoTpFrameType 0-0;
SG_MUL_VAL_ 293 FirstFrameLength IsoTpFrameType 1-1;
SG_MUL_VAL_ 293 ConsecutiveSequence IsoTpFrameType 2-2;
SG_MUL_VAL_ 293 FlowStatus IsoTpFrameType 3-3;
SG_MUL_VAL_ 293 UnknownPciLow IsoTpFrameType 4-15;
SG_MUL_VAL_ 293 BlockSize IsoTpFrameType 3-3;
SG_MUL_VAL_ 293 SingleData1 IsoTpFrameType 0-0;
SG_MUL_VAL_ 293 ConsecutiveData1 IsoTpFrameType 2-2;
SG_MUL_VAL_ 293 UnknownData1 IsoTpFrameType 4-15;
SG_MUL_VAL_ 293 SeparationTimeRaw IsoTpFrameType 3-3;
SG_MUL_VAL_ 293 SingleData2 IsoTpFrameType 0-0;
SG_MUL_VAL_ 293 ConsecutiveData2 IsoTpFrameType 2-2;
SG_MUL_VAL_ 293 UnknownData2 IsoTpFrameType 4-15;
SG_MUL_VAL_ 293 FirstData1 IsoTpFrameType 1-1;
SG_MUL_VAL_ 293 SingleData3 IsoTpFrameType 0-0;
SG_MUL_VAL_ 293 ConsecutiveData3 IsoTpFrameType 2-2;
SG_MUL_VAL_ 293 UnknownData3 IsoTpFrameType 4-15;
SG_MUL_VAL_ 293 FirstData2 IsoTpFrameType 1-1;
SG_MUL_VAL_ 293 FlowPadding1 IsoTpFrameType 3-3;
SG_MUL_VAL_ 293 SingleData4 IsoTpFrameType 0-0;
SG_MUL_VAL_ 293 ConsecutiveData4 IsoTpFrameType 2-2;
SG_MUL_VAL_ 293 UnknownData4 IsoTpFrameType 4-15;
SG_MUL_VAL_ 293 FirstData3 IsoTpFrameType 1-1;
SG_MUL_VAL_ 293 FlowPadding2 IsoTpFrameType 3-3;
SG_MUL_VAL_ 293 SingleData5 IsoTpFrameType 0-0;
SG_MUL_VAL_ 293 ConsecutiveData5 IsoTpFrameType 2-2;
SG_MUL_VAL_ 293 UnknownData5 IsoTpFrameType 4-15;
SG_MUL_VAL_ 293 FirstData4 IsoTpFrameType 1-1;
SG_MUL_VAL_ 293 FlowPadding3 IsoTpFrameType 3-3;
SG_MUL_VAL_ 293 SingleData6 IsoTpFrameType 0-0;
SG_MUL_VAL_ 293 ConsecutiveData6 IsoTpFrameType 2-2;
SG_MUL_VAL_ 293 UnknownData6 IsoTpFrameType 4-15;
SG_MUL_VAL_ 293 FirstData5 IsoTpFrameType 1-1;
SG_MUL_VAL_ 293 FlowPadding4 IsoTpFrameType 3-3;
SG_MUL_VAL_ 293 SingleData7 IsoTpFrameType 0-0;
SG_MUL_VAL_ 293 ConsecutiveData7 IsoTpFrameType 2-2;
SG_MUL_VAL_ 293 UnknownData7 IsoTpFrameType 4-15;
SG_MUL_VAL_ 293 FirstData6 IsoTpFrameType 1-1;
SG_MUL_VAL_ 293 FlowPadding5 IsoTpFrameType 3-3;
